VERSION ""

NS_ :

BS_:

BU_: Turbocharger OnBoardDataLogger OffBoardDiagnosticTool2 OffBoardDiagnosticTool1 FileServer ParkingBrakeController SeatControl2 FanDriveController SteeringColumnUnit CommunicationUnitRadio CommunicationUnitSatellite CommunicationUnitCellular PropulsionBatteryCharger ChassisController2 ChassisController1 EngineValveControl AuxiliaryHeater2 AuxiliaryHeater1 ClutchUnit RampControl InformationSystem1 SuspensionSystemController2 OilSensor VehicleDynamicStability ExhaustEmissionController TransmissionDisplay2 TransmissionDisplay1 ClimateControl2 WaterPumpController RearAxleSteeringController LightingOperatorControl SeatController1 IgnitionController2 IgnitionController1 TirePressureController CabController2 CabController1 PneumaticSystemController SuspensionSystemController1 HydraulicPumpController EnduranceBrakingSystem RetarderExhaustEngine2 OnBoardDiagnosticUnit HeadwayController RetarderExhaustEngine1 CabDisplay1 ManagementComputer VirtualTerminal OffVehicleGateway PowerTakeOffFront HitchControl AuxiliaryValveControl BodyController TractorTrailerBridge1 StarterSystem ElectricalSystem VehicleSecurity VehicleNavigation AerodynamicControl ElectricalChargingSystem ClimateControl1 TripRecorder InstrumentCluster SuspensionDriveAxle2 SuspensionDriveAxle1 SuspensionSteerAxle SteeringController FuelSystem CruiseControl RetarderDriveline RetarderEngine BrakesDriveAxle2 BrakesDriveAxle1 BrakesSystemController BrakesSteerAxle AxleDrive2 AxleDrive1 AxleSteering PowerTakeOff ShiftConsoleSecondary ShiftConsolePrimary Transmission2 Transmission1 Engine2 Engine1
VAL_TABLE_ FMI 31 "Not available" 19 "Received network data in error" 18 "Below normal (moderately severe)" 17 "Below normal (least severe)" 16 "Above normal (moderately severe)" 15 "Above normal (least severe)" 14 "Special intstructions" 13 "Out of calibration" 12 "Bad intelligent device" 11 "Root cause not known" 10 "Abnormal rate of change" 9 "Abnormal update rate" 8 "Abnormal frequency" 7 "Mechanical system not responding" 6 "Current above normal" 5 "Current below normal" 4 "Voltage below normal" 3 "Voltage above normal" 2 "Data erratic" 1 "Below normal (most severe)" 0 "Above normal (most severe)" ;

BO_ 3221225472 VECTOR__INDEPENDENT_SIG_MSG: 0 Vector__XXX
 SG_ New_Signal_6357 : 0|8@1+ (1,0) [0|0] "" Vector__XXX
 SG_ New_Signal_6356 : 0|8@1+ (1,0) [0|0] "" Vector__XXX
 SG_ TrailerWeight : 0|16@1+ (2,0) [0|128510] "kg" Vector__XXX
 SG_ ReferenceTirePressSetting : 0|8@1+ (1,0) [0|2000] "kPa" Vector__XXX
 SG_ ReferenceTirePress : 0|8@1+ (1,0) [0|2000] "kPa" Vector__XXX
 SG_ TirePressThresholdDetection : 0|3@1+ (1,0) [0|7] "" Vector__XXX
 SG_ TireAirLeakageRate : 0|16@1+ (0.1,0) [0|6425.5] "Pa/s" Vector__XXX
 SG_ CTIWheelEndElectricalFault : 0|2@1+ (1,0) [0|3] "" Vector__XXX
 SG_ CTITireStatus : 0|2@1+ (1,0) [0|3] "" Vector__XXX
 SG_ CTIWheelSensorStatus : 0|2@1+ (1,0) [0|3] "" Vector__XXX
 SG_ TireTemp : 0|16@1+ (0.03125,-273) [-273|1734.96875] "deg C" Vector__XXX
 SG_ TirePress : 0|8@1+ (4,0) [0|1000] "kPa" Vector__XXX
 SG_ EngTurningGearEngaged : 0|2@1+ (1,0) [0|3] "" Vector__XXX
 SG_ ChangeChildPositionParentObjectI : 0|16@1+ (1,0) [0|65535] "" Vector__XXX
 SG_ ChangeChildLocationParentObjectI : 0|16@1+ (1,0) [0|65535] "" Vector__XXX
 SG_ InputObjectId : 0|16@1+ (1,0) [0|255] "" Vector__XXX
 SG_ KeyActivationCode : 0|8@1+ (1,0) [0|2] "" Vector__XXX
 SG_ ButtonActivationCode : 0|8@1+ (1,0) [0|2] "" Vector__XXX
 SG_ XPosition : 0|16@1+ (1,0) [0|65535] "" Vector__XXX
 SG_ VTSelectInputObjectID : 0|16@1+ (1,0) [0|65535] "" Vector__XXX
 SG_ VTEscObjectID : 0|16@1+ (1,0) [0|65535] "" Vector__XXX
 SG_ VTChangeNumericValueObjectID : 0|16@1+ (1,0) [0|65535] "" Vector__XXX
 SG_ VTChangeActiveMaskObjectID : 0|16@1+ (1,0) [0|65535] "" Vector__XXX
 SG_ VTChangeSoftKeyMaskParentID : 0|16@1+ (1,0) [0|65535] "" Vector__XXX
 SG_ AuxiliaryFunctionObjectID : 0|16@1+ (1,0) [0|65535] "" Vector__XXX
 SG_ InputStatusObjectId : 0|16@1+ (1,0) [0|255] "" Vector__XXX
 SG_ SelectInputObjectID : 0|16@1+ (1,0) [0|65535] "" Vector__XXX
 SG_ ObjectToSizeID : 0|16@1+ (1,0) [0|65535] "" Vector__XXX
 SG_ ObjectToChangeColourID : 0|16@1+ (1,0) [0|65535] "" Vector__XXX
 SG_ ObjectToChangeNumValueID : 0|16@1+ (1,0) [0|65535] "" Vector__XXX
 SG_ ObjectToChangeEndPointID : 0|16@1+ (1,0) [0|65535] "" Vector__XXX
 SG_ ObjectToChangeFontID : 0|16@1+ (1,0) [0|65535] "" Vector__XXX
 SG_ ObjectToChangeFillAttributesID : 0|16@1+ (1,0) [0|65535] "" Vector__XXX
 SG_ ObjectToChangeAttributeID : 0|16@1+ (1,0) [0|65535] "" Vector__XXX
 SG_ AlarmMaskObjectID : 0|16@1+ (1,0) [0|65535] "" Vector__XXX
 SG_ ListInputObjectID : 0|16@1+ (1,0) [0|65535] "" Vector__XXX
 SG_ PolygonObjectToChangeID : 0|16@1+ (1,0) [0|65535] "" Vector__XXX
 SG_ PolygonObjectToScaleID : 0|16@1+ (1,0) [0|65535] "" Vector__XXX
 SG_ GraphicsContextObjectID : 0|16@1+ (1,0) [0|65535] "" Vector__XXX
 SG_ ObjectToGetAttributeID : 0|16@1+ (1,0) [0|65535] "" Vector__XXX
 SG_ ColourMapObjectID : 0|16@1+ (1,0) [0|65535] "" Vector__XXX
 SG_ LockUnlockCommand : 0|8@1+ (1,0) [0|1] "" Vector__XXX
 SG_ MacroObjecID : 0|8@1+ (1,0) [0|255] "" Vector__XXX
 SG_ CodePlane : 0|8@1+ (1,0) [0|16] "" Vector__XXX
 SG_ KeyObjectID : 0|16@1+ (1,0) [0|65535] "" Vector__XXX
 SG_ ButtonObjectID : 0|16@1+ (1,0) [0|65535] "" Vector__XXX
 SG_ DataOrAlarmMaskObjectID : 0|16@1+ (1,0) [0|65535] "" Vector__XXX
 SG_ MemoryRequired : 0|32@1+ (1,0) [0|4294967295] "" Vector__XXX
 SG_ FirstWideChar : 0|16@1+ (1,0) [0|65535] "" Vector__XXX
 SG_ IdentityNumber : 0|21@1+ (1,0) [0|2097152] "" Vector__XXX
 SG_ Status_1 : 0|8@1+ (1,0) [0|1] "" Vector__XXX
 SG_ YPosition : 0|16@1+ (1,0) [0|65535] "" Vector__XXX
 SG_ VTSelectInputObjectStatus : 0|8@1+ (1,0) [0|1] "" Vector__XXX
 SG_ VTChangeSoftKeyMaskObjectID : 0|16@1+ (1,0) [0|65535] "" Vector__XXX
 SG_ AuxInputEnable : 0|8@1+ (1,0) [0|1] "" Vector__XXX
 SG_ ChangeChildPositionObjectID : 0|16@1+ (1,0) [0|65535] "" Vector__XXX
 SG_ NewBackgroundColour : 0|8@1+ (1,0) [0|255] "" Vector__XXX
 SG_ AttributeID : 0|8@1+ (1,0) [0|16777200] "" Vector__XXX
 SG_ NewPriority : 0|8@1+ (1,0) [0|255] "" Vector__XXX
 SG_ ListIndex : 0|8@1+ (1,0) [0|255] "" Vector__XXX
 SG_ ChangeChildLocationObjectID : 0|16@1+ (1,0) [0|65535] "" Vector__XXX
 SG_ NewWidthAttribute : 0|16@1+ (1,0) [0|65535] "" Vector__XXX
 SG_ SubCommandID : 0|8@1+ (1,0) [0|0] "" Vector__XXX
 SG_ Value1 : 0|16@1+ (1,0) [0|65535] "" Vector__XXX
 SG_ KeyObjectParentID : 0|16@1+ (1,0) [0|65535] "" Vector__XXX
 SG_ ButtonObjectParentID : 0|16@1+ (1,0) [0|65535] "" Vector__XXX
 SG_ VTChangeNumericValueValue : 0|32@1+ (1,0) [0|4294967295] "" Vector__XXX
 SG_ NewObjectID : 0|16@1+ (1,0) [0|65535] "" Vector__XXX
 SG_ LastWideChar : 0|16@1+ (1,0) [0|65535] "" Vector__XXX
 SG_ ManufacturerCode : 0|11@1+ (1,0) [0|2047] "" Vector__XXX
 SG_ TouchState : 0|8@1+ (1,0) [0|255] "" Vector__XXX
 SG_ NewHeigthAttribute : 0|16@1+ (1,0) [0|0] "" Vector__XXX
 SG_ Value2 : 0|16@1+ (1,0) [0|65535] "" Vector__XXX
 SG_ Status_2 : 0|8@1+ (1,0) [0|1] "" Vector__XXX
 SG_ SoftKeyCode : 0|8@1+ (1,0) [0|255] "" Vector__XXX
 SG_ ButtonKeyCode : 0|8@1+ (1,0) [0|255] "" Vector__XXX
 SG_ ECUInstance : 0|3@1+ (1,0) [0|7] "" Vector__XXX
 SG_ FunctionInstance : 0|5@1+ (1,0) [0|31] "" Vector__XXX
 SG_ OperatingState1 : 0|1@1+ (1,0) [0|1] "" Vector__XXX
 SG_ Function : 0|8@1+ (1,0) [0|255] "" Vector__XXX
 SG_ OperatingState2 : 0|1@1+ (1,0) [0|1] "" Vector__XXX
 SG_ VehicleSystem2 : 0|7@1+ (1,0) [0|127] "" Vector__XXX
 SG_ VehicleSystemInstance : 0|4@1+ (1,0) [0|15] "" Vector__XXX
 SG_ IndustryGroup : 0|3@1+ (1,0) [0|7] "" Vector__XXX
 SG_ ArbitraryAddressCapable : 0|1@1+ (1,0) [0|1] "" Vector__XXX
 SG_ MalfunctionIndicatorLampStatus : 0|2@1+ (1,0) [0|3] "" Vector__XXX
 SG_ RedStopLampState : 0|2@1+ (1,0) [0|3] "" Vector__XXX
 SG_ AmberWarningLampStatus : 0|2@1+ (1,0) [0|3] "" Vector__XXX
 SG_ ProtectLampStatus : 0|2@1+ (1,0) [0|3] "" Vector__XXX
 SG_ FlashRedStopLamp : 0|2@1+ (1,0) [0|3] "" Vector__XXX
 SG_ FlashProtectLamp : 0|2@1+ (1,0) [0|3] "" Vector__XXX
 SG_ FlashMalfuncIndicatorLamp : 0|2@1+ (1,0) [0|3] "" Vector__XXX
 SG_ FlashAmberWarningLamp : 0|2@1+ (1,0) [0|3] "" Vector__XXX
 SG_ DTC5 : 0|32@1+ (1,0) [0|4294967295] "" Vector__XXX
 SG_ DTC4 : 0|32@1+ (1,0) [0|4294967295] "" Vector__XXX
 SG_ DTC3 : 0|32@1+ (1,0) [0|4294967295] "" Vector__XXX
 SG_ DTC2 : 0|32@1+ (1,0) [0|4294967295] "" Vector__XXX
 SG_ DTC1 : 0|32@1+ (1,0) [0|4294967295] "" Vector__XXX

BO_ 682 reverseCurrent2: 1 Vector__XXX
 SG_ error : 0|8@1+ (1,0) [0|0] "enum" Vector__XXX

BO_ 681 reverseCurrnet1: 4 Vector__XXX
 SG_ current : 0|32@1+ (1,0) [0|0] "uA" Vector__XXX

BO_ 2566835198 DM2: 22 Vector__XXX
 SG_ SPN_Conversion_Method5 : 175|1@1+ (1,0) [0|0] "" Vector__XXX
 SG_ Occurance_Count5 : 168|7@1+ (1,0) [0|0] "" Vector__XXX
 SG_ Failure_Mode_Indentifier5 : 160|5@1+ (1,0) [0|0] "" Vector__XXX
 SG_ SPN5 : 151|19@0+ (1,0) [0|0] "" Vector__XXX
 SG_ SPN_Conversion_Method4 : 143|1@1+ (1,0) [0|0] "" Vector__XXX
 SG_ Occurance_Count4 : 136|7@1+ (1,0) [0|0] "" Vector__XXX
 SG_ Failure_Mode_Indentifier4 : 128|5@1+ (1,0) [0|0] "" Vector__XXX
 SG_ SPN4 : 119|19@0+ (1,0) [0|0] "" Vector__XXX
 SG_ SPN_Conversion_Method3 : 111|1@1+ (1,0) [0|0] "" Vector__XXX
 SG_ Occurance_Count3 : 104|7@1+ (1,0) [0|0] "" Vector__XXX
 SG_ Failure_Mode_Indentifier3 : 96|5@1+ (1,0) [0|0] "" Vector__XXX
 SG_ SPN3 : 87|19@0+ (1,0) [0|0] "" Vector__XXX
 SG_ Occurance_Count2 : 72|7@1+ (1,0) [0|0] "" Vector__XXX
 SG_ SPN_Conversion_Method2 : 79|1@1+ (1,0) [0|0] "" Vector__XXX
 SG_ Failure_Mode_Indentifier2 : 64|5@1+ (1,0) [0|0] "" Vector__XXX
 SG_ SPN2 : 55|19@0+ (1,0) [0|0] "" Vector__XXX
 SG_ SPN : 23|19@0+ (1,0) [0|0] "" Vector__XXX
 SG_ SPN_Conversion_Method : 47|1@1+ (1,0) [0|0] "" Vector__XXX
 SG_ Occurance_Count : 40|7@1+ (1,0) [0|0] "" Vector__XXX
 SG_ Failure_Mode_Indentifier : 32|5@1+ (1,0) [0|0] "" Vector__XXX
 SG_ FlashRedStopLamp : 12|2@1+ (1,0) [0|3] "" Vector__XXX
 SG_ FlashProtectLamp : 8|2@1+ (1,0) [0|3] "" Vector__XXX
 SG_ FlashMalfuncIndicatorLamp : 14|2@1+ (1,0) [0|3] "" Vector__XXX
 SG_ FlashAmberWarningLamp : 10|2@1+ (1,0) [0|3] "" Vector__XXX
 SG_ MalfunctionIndicatorLampStatus : 6|2@1+ (1,0) [0|3] "" Vector__XXX
 SG_ AmberWarningLampStatus : 2|2@1+ (1,0) [0|3] "" Vector__XXX
 SG_ RedStopLampState : 4|2@1+ (1,0) [0|3] "" Vector__XXX
 SG_ ProtectLampStatus : 0|2@1+ (1,0) [0|3] "" Vector__XXX

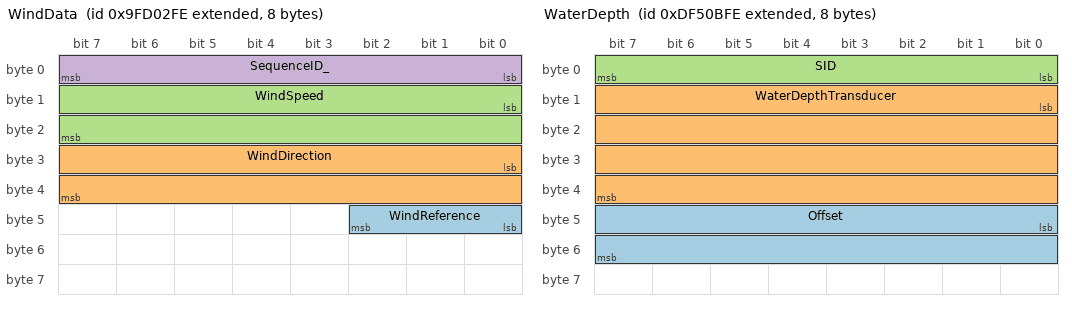
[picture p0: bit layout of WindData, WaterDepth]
BO_ 2315059966 WindData: 8 Vector__XXX
 SG_ WindReference : 40|3@1+ (1,0) [0|7] "" Vector__XXX
 SG_ WindDirection : 24|16@1+ (0.0001,0) [0|6.28318] "rad" Vector__XXX
 SG_ WindSpeed : 8|16@1+ (0.01,0) [0|655.32] "m/s" Vector__XXX
 SG_ SequenceID_ : 0|8@1+ (1,0) [0|252] "" Vector__XXX

BO_ 2381646846 WaterDepth: 8 Vector__XXX
 SG_ Offset : 40|16@1- (0.001,0) [-32.764|32.764] "m" Vector__XXX
 SG_ WaterDepthTransducer : 8|32@1+ (0.01,0) [0|42950000] "m" Vector__XXX
 SG_ SID : 0|8@1+ (1,0) [0|252] "" Vector__XXX

BO_ 2315129598 VesselSpeedComponents: 12 Vector__XXX
 SG_ SternSpeedGroundreferenced : 80|16@1- (0.001,0) [-32.764|32.764] "m/s" Vector__XXX
 SG_ SternSpeedWaterreferenced : 64|16@1- (0.001,0) [-32.764|32.764] "m/s" Vector__XXX
 SG_ TransverseSpeedGroundreferenced : 48|16@1- (0.001,0) [-32.764|32.764] "m/s" Vector__XXX
 SG_ LngtudinalSpeedGroundreferenced : 32|16@1- (0.001,0) [-32.764|32.764] "m/s" Vector__XXX
 SG_ TransverseSpeedWaterreferenced : 16|16@1- (0.001,0) [-32.764|32.764] "m/s" Vector__XXX
 SG_ LngitudinalSpeedWaterreferenced : 0|16@1- (0.001,0) [-32.764|32.764] "m/s" Vector__XXX

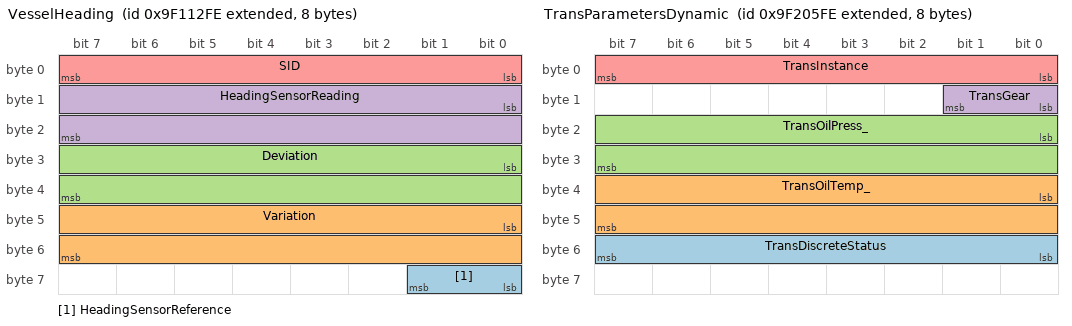
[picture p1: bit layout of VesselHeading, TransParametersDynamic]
BO_ 2314277630 VesselHeading: 8 Vector__XXX
 SG_ HeadingSensorReference : 56|2@1+ (1,0) [0|3] "" Vector__XXX
 SG_ Variation : 40|16@1- (0.0001,0) [-3.14159|3.14159] "rad" Vector__XXX
 SG_ Deviation : 24|16@1- (0.0001,0) [-3.14159|3.14159] "rad" Vector__XXX
 SG_ HeadingSensorReading : 8|16@1+ (0.0001,0) [0|6.28318] "rad" Vector__XXX
 SG_ SID : 0|8@1+ (1,0) [0|252] "" Vector__XXX

BO_ 2583172606 UserDatumSettings: 37 Vector__XXX
 SG_ DatumName : 288|8@1+ (1,0) [0|255] "ASCII" Vector__XXX
 SG_ EllipsoidFlatteningInverse : 256|32@1- (1,0) [-3.4E+038|3.4E+038] "" Vector__XXX
 SG_ EllipsoidSemimajorAxis : 224|32@1- (0.01,0) [-21470000|21470000] "m" Vector__XXX
 SG_ Scale : 192|32@1- (1,0) [-3.4E+038|3.4E+038] "" Vector__XXX
 SG_ RotationInZ : 160|32@1- (1,0) [-3.4E+038|3.4E+038] "" Vector__XXX
 SG_ RotationInY : 128|32@1- (1,0) [-3.4E+038|3.4E+038] "" Vector__XXX
 SG_ RotationInX : 96|32@1- (1,0) [-3.4E+038|3.4E+038] "" Vector__XXX
 SG_ DeltaZ : 64|32@1- (0.01,0) [-21470000|21470000] "m" Vector__XXX
 SG_ DeltaY : 32|32@1- (0.01,0) [-21470000|21470000] "m" Vector__XXX
 SG_ DeltaX : 0|32@1- (0.01,0) [-21470000|21470000] "m" Vector__XXX

BO_ 2515667198 TripParametersVessel: 14 Vector__XXX
 SG_ TripRunTime : 80|32@1+ (0.001,0) [0|4295000] "sec" Vector__XXX
 SG_ EstFuelRemaining : 64|16@1+ (0.001,0) [0|65.532] "cu m" Vector__XXX
 SG_ DistanceToEmpty : 32|32@1+ (0.01,0) [0|42950000] "m" Vector__XXX
 SG_ TimeToEmpty : 0|32@1+ (0.001,0) [0|4295000] "sec" Vector__XXX

BO_ 2515667454 TripParametersEng: 9 Vector__XXX
 SG_ InstantaneousFuelEconomy : 56|16@1- (0.0001,0) [-3.2764|3.2764] "(cu m)/hr" Vector__XXX
 SG_ FuelRateEconomy : 40|16@1- (0.0001,0) [-3.2764|3.2764] "(cu m)/hr" Vector__XXX
 SG_ FuelRateAverage : 24|16@1- (0.0001,0) [-3.2764|3.2764] "(cu m)/hr" Vector__XXX
 SG_ TripFuelUsed : 8|16@1+ (0.001,0) [0|65.532] "cu m" Vector__XXX
 SG_ EngInstance : 0|8@1+ (1,0) [0|255] "" Vector__XXX

BO_ 2314339838 TransParametersDynamic: 8 Vector__XXX
 SG_ TransDiscreteStatus : 48|8@1+ (1,0) [0|255] "" Vector__XXX
 SG_ TransOilTemp_ : 32|16@1+ (0.1,0) [0|6553.2] "°K" Vector__XXX
 SG_ TransOilPress_ : 16|16@1+ (100,0) [0|6553200] "Pa" Vector__XXX
 SG_ TransGear : 8|2@1+ (1,0) [0|3] "" Vector__XXX
 SG_ TransInstance : 0|8@1+ (1,0) [0|255] "" Vector__XXX

BO_ 2314602750 TrackedTargetData: 27 Vector__XXX
 SG_ CPA : 112|32@1- (0.01,0) [-21470000|21470000] "m" Vector__XXX
 SG_ Speed : 96|16@1+ (0.01,0) [0|655.32] "m/s" Vector__XXX
 SG_ Course : 80|16@1+ (0.0001,0) [0|6.28318] "rad" Vector__XXX
 SG_ Distance : 48|32@1- (0.01,0) [-21470000|21470000] "m" Vector__XXX
 SG_ Bearing : 32|16@1+ (0.0001,0) [0|6.28318] "rad" Vector__XXX
 SG_ BearingReference : 28|2@1+ (1,0) [0|3] "" Vector__XXX
 SG_ TrackStatus : 24|4@1+ (1,0) [0|15] "" Vector__XXX
 SG_ TargetID : 8|16@1+ (1,0) [0|65532] "" Vector__XXX
 SG_ SequenceID_ : 0|8@1+ (1,0) [0|252] "" Vector__XXX
 SG_ Name : 208|8@1+ (1,0) [0|255] "ASCII" Vector__XXX
 SG_ UTCOfFix : 176|32@1+ (0.0001,0) [0|86401] "sec" Vector__XXX
 SG_ TCPA : 144|32@1- (0.001,0) [-2148000|2148000] "sec" Vector__XXX

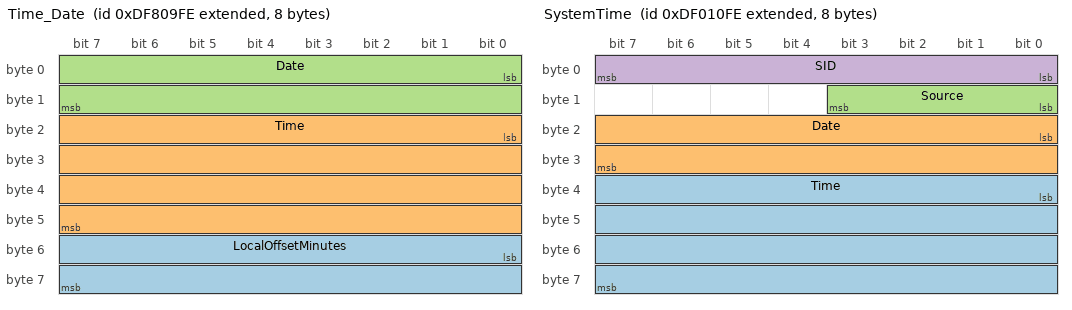
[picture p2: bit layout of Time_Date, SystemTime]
BO_ 2381842942 Time_Date: 8 Vector__XXX
 SG_ LocalOffsetMinutes : 48|16@1- (1,0) [-32764|32764] "mins" Vector__XXX
 SG_ Time : 16|32@1+ (0.0001,0) [0|86401] "sec" Vector__XXX
 SG_ Date : 0|16@1+ (1,0) [0|65532] "day" Vector__XXX

BO_ 2381911550 TimeTo_FromMark: 10 Vector__XXX
 SG_ MarkID : 48|32@1+ (1,0) [0|4294967292] "" Vector__XXX
 SG_ MarkType : 40|4@1+ (1,0) [0|15] "" Vector__XXX
 SG_ TimeElapsedTogoToMark : 8|32@1- (0.001,0) [-2148000|2148000] "sec" Vector__XXX
 SG_ SID : 0|8@1+ (1,0) [0|252] "" Vector__XXX

BO_ 2583499006 TideStationData: 20 Vector__XXX
 SG_ StationIDString : 152|8@1+ (1,0) [0|255] "ASCII" Vector__XXX
 SG_ TideLevelStandardDeviation : 136|16@1+ (0.01,0) [0|655.32] "m" Vector__XXX
 SG_ TideLevel : 120|16@1- (0.001,0) [-32.764|32.764] "m" Vector__XXX
 SG_ StationLocationLongitude : 88|32@1- (1E-007,0) [-180|180] "deg" Vector__XXX
 SG_ StationLocationLatitude : 56|32@1- (1E-007,0) [-90|90] "deg" Vector__XXX
 SG_ MeasurementTime : 24|32@1+ (0.0001,0) [0|86401] "sec" Vector__XXX
 SG_ MeasurementDate : 8|16@1+ (1,0) [0|65532] "day" Vector__XXX
 SG_ TideTendency : 4|2@1+ (1,0) [0|3] "" Vector__XXX
 SG_ Mode : 0|4@1+ (1,0) [0|15] "" Vector__XXX

BO_ 2381320446 SystemTime: 8 Vector__XXX
 SG_ Time : 32|32@1+ (0.0001,0) [0|86401] "sec" Vector__XXX
 SG_ Date : 16|16@1+ (1,0) [0|65532] "day" Vector__XXX
 SG_ Source : 8|4@1+ (1,0) [0|15] "" Vector__XXX
 SG_ SID : 0|8@1+ (1,0) [0|252] "" Vector__XXX

BO_ 2381451006 SwitchBankCtrl: 8 Vector__XXX
 SG_ Switch28 : 62|2@1+ (1,0) [0|3] "" Vector__XXX
 SG_ Switch27 : 60|2@1+ (1,0) [0|3] "" Vector__XXX
 SG_ Switch26 : 58|2@1+ (1,0) [0|3] "" Vector__XXX
 SG_ Switch25 : 56|2@1+ (1,0) [0|3] "" Vector__XXX
 SG_ Switch24 : 54|2@1+ (1,0) [0|3] "" Vector__XXX
 SG_ Switch23 : 52|2@1+ (1,0) [0|3] "" Vector__XXX
 SG_ Switch22 : 50|2@1+ (1,0) [0|3] "" Vector__XXX
 SG_ Switch21 : 48|2@1+ (1,0) [0|3] "" Vector__XXX
 SG_ Switch20 : 46|2@1+ (1,0) [0|3] "" Vector__XXX
 SG_ Switch19 : 44|2@1+ (1,0) [0|3] "" Vector__XXX
 SG_ Switch18 : 42|2@1+ (1,0) [0|3] "" Vector__XXX
 SG_ Switch17 : 40|2@1+ (1,0) [0|3] "" Vector__XXX
 SG_ Switch16 : 38|2@1+ (1,0) [0|3] "" Vector__XXX
 SG_ Switch15 : 36|2@1+ (1,0) [0|3] "" Vector__XXX
 SG_ Switch14 : 34|2@1+ (1,0) [0|3] "" Vector__XXX
 SG_ Switch13 : 32|2@1+ (1,0) [0|3] "" Vector__XXX
 SG_ Switch12 : 30|2@1+ (1,0) [0|3] "" Vector__XXX
 SG_ Switch11 : 28|2@1+ (1,0) [0|3] "" Vector__XXX
 SG_ Switch10 : 26|2@1+ (1,0) [0|3] "" Vector__XXX
 SG_ Switch9 : 24|2@1+ (1,0) [0|3] "" Vector__XXX
 SG_ Switch8 : 22|2@1+ (1,0) [0|3] "" Vector__XXX
 SG_ Switch7 : 20|2@1+ (1,0) [0|3] "" Vector__XXX
 SG_ Switch6 : 18|2@1+ (1,0) [0|3] "" Vector__XXX
 SG_ Switch5 : 16|2@1+ (1,0) [0|3] "" Vector__XXX
 SG_ Switch4 : 14|2@1+ (1,0) [0|3] "" Vector__XXX
 SG_ Switch3 : 12|2@1+ (1,0) [0|3] "" Vector__XXX
 SG_ Switch2 : 10|2@1+ (1,0) [0|3] "" Vector__XXX
 SG_ Switch1 : 8|2@1+ (1,0) [0|3] "" Vector__XXX
 SG_ SwitchBankInstance : 0|8@1+ (1,0) [0|252] "" Vector__XXX

BO_ 2314535934 Speed: 9 Vector__XXX
 SG_ SpeedGroundReferenced : 24|22@1+ (0.01,0) [0|655.32] "m/s" Vector__XXX
 SG_ SpeedWaterReferenced : 8|16@1+ (0.01,0) [0|655.32] "m/s" Vector__XXX
 SG_ SequenceID_ : 0|8@1+ (1,0) [0|252] "" Vector__XXX

BO_ 2315129086 SmallCraftStatus: 8 Vector__XXX
 SG_ StarboardTrimTab : 8|8@1- (1,0) [-124|124] "" Vector__XXX
 SG_ PortTrimTab : 0|8@1- (1,0) [-124|124] "" Vector__XXX

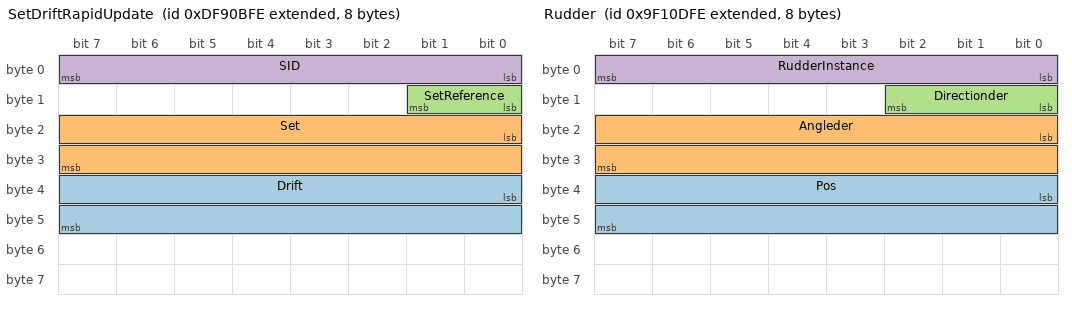
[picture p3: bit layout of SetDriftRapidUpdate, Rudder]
BO_ 2381908990 SetDriftRapidUpdate: 8 Vector__XXX
 SG_ Drift : 32|16@1+ (0.01,0) [0|655.32] "m/s" Vector__XXX
 SG_ Set : 16|16@1+ (0.0001,0) [0|6.28318] "rad" Vector__XXX
 SG_ SetReference : 8|2@1+ (1,0) [0|3] "" Vector__XXX
 SG_ SID : 0|8@1+ (1,0) [0|252] "" Vector__XXX

BO_ 2583499262 SalinityStationData: 22 Vector__XXX
 SG_ StationIDString : 168|8@1+ (1,0) [0|255] "ASCII" Vector__XXX
 SG_ WaterTemp : 152|16@1+ (0.01,0) [0|655.32] "°K" Vector__XXX
 SG_ Salinity : 120|32@1- (1,0) [-3.4E+038|3.4E+038] "" Vector__XXX
 SG_ StationLocationLongitude : 88|32@1- (1E-007,0) [-180|180] "deg" Vector__XXX
 SG_ StationLocationLatitude : 56|32@1- (1E-007,0) [-90|90] "deg" Vector__XXX
 SG_ MeasurementTime : 24|32@1+ (0.0001,0) [0|86401] "sec" Vector__XXX
 SG_ MeasurementDate : 8|16@1+ (1,0) [0|65532] "day" Vector__XXX
 SG_ Mode : 0|4@1+ (1,0) [0|15] "" Vector__XXX

BO_ 2650544894 RuteAndWPServiceWPListWPNamePos: 13 Vector__XXX
 SG_ WPName : 96|8@1+ (1,0) [0|255] "ASCII" Vector__XXX
 SG_ WPID : 80|16@1+ (1,0) [0|65532] "" Vector__XXX
 SG_ reserved : 64|16@1+ (1,0) [0|65532] "" Vector__XXX
 SG_ DatabaseID : 48|16@1+ (1,0) [0|65532] "" Vector__XXX
 SG_ NumberOfValidWPsInWPList : 32|16@1+ (1,0) [0|65532] "" Vector__XXX
 SG_ nItems : 16|16@1+ (1,0) [0|65532] "" Vector__XXX
 SG_ StartWPID : 0|16@1+ (1,0) [0|65532] "" Vector__XXX

BO_ 2650544382 RuteAndWPServiceDatabaseComment: 9 Vector__XXX
 SG_ CommentText : 64|8@1+ (1,0) [0|255] "ASCII" Vector__XXX
 SG_ DatabaseID : 48|16@1+ (1,0) [0|65532] "" Vector__XXX
 SG_ NumberOfDatabasesWithComments : 32|16@1+ (1,0) [0|65532] "" Vector__XXX
 SG_ nItems : 16|16@1+ (1,0) [0|65532] "" Vector__XXX
 SG_ StartDatabaseID : 0|16@1+ (1,0) [0|65532] "" Vector__XXX

BO_ 2314276350 Rudder: 8 Vector__XXX
 SG_ Pos : 32|16@1- (0.0001,0) [-3.14159|3.14159] "rad" Vector__XXX
 SG_ Angleder : 16|16@1- (0.0001,0) [-3.14159|3.14159] "rad" Vector__XXX
 SG_ Directionder : 8|3@1+ (1,0) [0|7] "" Vector__XXX
 SG_ RudderInstance : 0|8@1+ (1,0) [0|255] "" Vector__XXX

BO_ 2650543614 RtAndWPSrvcXTELmtNvgationMethod: 15 Vector__XXX
 SG_ NavMethodInLegAfterWP : 112|2@1+ (1,0) [0|3] "" Vector__XXX
 SG_ XTELimitInLegAfterWP : 96|16@1- (1,0) [-32764|32764] "m" Vector__XXX
 SG_ RPS : 80|16@1+ (1,0) [0|65532] "" Vector__XXX
 SG_ RouteID : 64|16@1+ (1,0) [0|65532] "" Vector__XXX
 SG_ DatabaseID : 48|16@1+ (1,0) [0|65532] "" Vector__XXX
 SG_ NmbrOfWypntsWthASpcfcXTELmtNvMth : 32|16@1+ (1,0) [0|65532] "" Vector__XXX
 SG_ nItems : 16|16@1+ (1,0) [0|65532] "" Vector__XXX
 SG_ StartRPS : 0|16@1+ (1,0) [0|65532] "" Vector__XXX

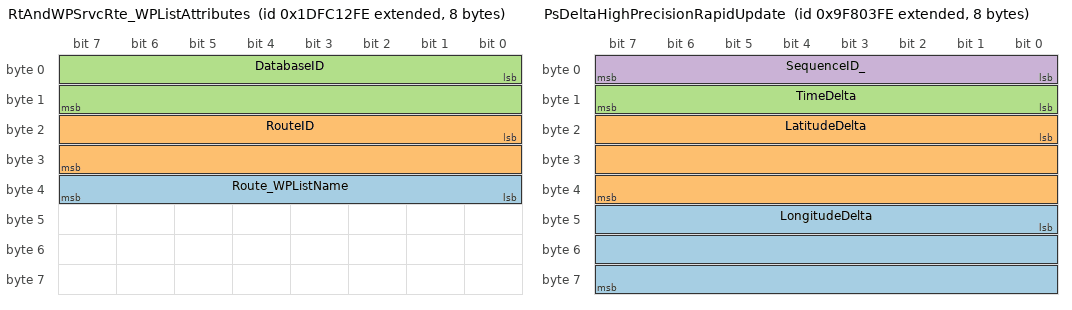
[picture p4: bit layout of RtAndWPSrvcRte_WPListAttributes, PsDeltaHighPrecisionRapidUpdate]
BO_ 2650542846 RtAndWPSrvcRte_WPListAttributes: 8 Vector__XXX
 SG_ Route_WPListName : 32|8@1+ (1,0) [0|255] "ASCII" Vector__XXX
 SG_ RouteID : 16|16@1+ (1,0) [0|65532] "" Vector__XXX
 SG_ DatabaseID : 0|16@1+ (1,0) [0|65532] "" Vector__XXX

BO_ 2650543870 RouteAndWPServiceWPComment: 13 Vector__XXX
 SG_ Comment : 96|8@1+ (1,0) [0|255] "ASCII" Vector__XXX
 SG_ WPID_RPS : 80|16@1+ (1,0) [0|65532] "" Vector__XXX
 SG_ RouteID : 64|16@1+ (1,0) [0|65532] "" Vector__XXX
 SG_ DatabaseID : 48|16@1+ (1,0) [0|65532] "" Vector__XXX
 SG_ NumberOfWPsWithComments : 32|16@1+ (1,0) [0|65532] "" Vector__XXX
 SG_ nItems : 16|16@1+ (1,0) [0|65532] "" Vector__XXX
 SG_ StartID : 0|16@1+ (1,0) [0|65532] "" Vector__XXX

BO_ 2650543102 RouteAndWPServiceRouteWPNamePos: 13 Vector__XXX
 SG_ WPName : 96|8@1+ (1,0) [0|255] "ASCII" Vector__XXX
 SG_ WPID : 80|16@1+ (1,0) [0|65532] "" Vector__XXX
 SG_ RouteID : 64|16@1+ (1,0) [0|65532] "" Vector__XXX
 SG_ DatabaseID : 48|16@1+ (1,0) [0|65532] "" Vector__XXX
 SG_ NumberOfWPsInRoute : 32|16@1+ (1,0) [0|65532] "" Vector__XXX
 SG_ nItems : 16|16@1+ (1,0) [0|65532] "" Vector__XXX
 SG_ StartRPS : 0|16@1+ (1,0) [0|65532] "" Vector__XXX

BO_ 2650543358 RouteAndWPServiceRouteWPName: 13 Vector__XXX
 SG_ WPName : 96|8@1+ (1,0) [0|255] "ASCII" Vector__XXX
 SG_ WPID : 80|16@1+ (1,0) [0|65532] "" Vector__XXX
 SG_ RouteID : 64|16@1+ (1,0) [0|65532] "" Vector__XXX
 SG_ DatabaseID : 48|16@1+ (1,0) [0|65532] "" Vector__XXX
 SG_ NumberOfWPsInRoute : 32|16@1+ (1,0) [0|65532] "" Vector__XXX
 SG_ nItems : 16|16@1+ (1,0) [0|65532] "" Vector__XXX
 SG_ StartRPS : 0|16@1+ (1,0) [0|65532] "" Vector__XXX

BO_ 2650542590 RouteAndWPServiceRouteList: 11 Vector__XXX
 SG_ RouteName : 80|8@1+ (1,0) [0|255] "ASCII" Vector__XXX
 SG_ RouteID : 64|16@1+ (1,0) [0|65532] "" Vector__XXX
 SG_ DatabaseID : 48|16@1+ (1,0) [0|65532] "" Vector__XXX
 SG_ NmbrOfRoutesAvailableInDatabase : 32|16@1+ (1,0) [0|65532] "" Vector__XXX
 SG_ nItems : 16|16@1+ (1,0) [0|65532] "" Vector__XXX
 SG_ StartRouteID : 0|16@1+ (1,0) [0|65532] "" Vector__XXX

BO_ 2650544126 RouteAndWPServiceRouteComment: 11 Vector__XXX
 SG_ Comment : 80|8@1+ (1,0) [0|255] "ASCII" Vector__XXX
 SG_ RouteID : 64|16@1+ (1,0) [0|65532] "" Vector__XXX
 SG_ DatabaseID : 48|16@1+ (1,0) [0|65532] "" Vector__XXX
 SG_ NumberOfRoutesWithComments : 32|16@1+ (1,0) [0|65532] "" Vector__XXX
 SG_ nItems : 16|16@1+ (1,0) [0|65532] "" Vector__XXX
 SG_ StartRouteID : 0|16@1+ (1,0) [0|65532] "" Vector__XXX

BO_ 2650544638 RouteAndWPServiceRadiusOfTurn: 14 Vector__XXX
 SG_ RadiusOfTurn : 96|16@1- (1,0) [-32764|32764] "m" Vector__XXX
 SG_ RPS : 80|16@1+ (1,0) [0|65532] "" Vector__XXX
 SG_ RouteID : 64|16@1+ (1,0) [0|65532] "" Vector__XXX
 SG_ DatabaseID : 48|16@1+ (1,0) [0|65532] "" Vector__XXX
 SG_ NmbrOfWypntsWthASpcfcRdusOfTurn : 32|16@1+ (1,0) [0|65532] "" Vector__XXX
 SG_ nItems : 16|16@1+ (1,0) [0|65532] "" Vector__XXX
 SG_ StartRPS : 0|16@1+ (1,0) [0|65532] "" Vector__XXX

BO_ 2650542334 RouteAndWPServiceDatabaseList: 9 Vector__XXX
 SG_ DatabaseName : 64|8@1+ (1,0) [0|255] "ASCII" Vector__XXX
 SG_ DatabaseID : 48|16@1+ (1,0) [0|65532] "" Vector__XXX
 SG_ NumberOfDatabasesAvailable : 32|16@1+ (1,0) [0|65532] "" Vector__XXX
 SG_ nItems : 16|16@1+ (1,0) [0|65532] "" Vector__XXX
 SG_ StartDatabaseID : 0|16@1+ (1,0) [0|65532] "" Vector__XXX

BO_ 2314277886 RateOfTurn: 8 Vector__XXX
 SG_ RateOfTurn : 8|16@1- (1,0) [-32768|32767] "rad/s" Vector__XXX
 SG_ SequenceID_ : 0|8@1+ (1,0) [0|252] "" Vector__XXX

BO_ 2382039038 RadioFrequency_Mode_Power: 9 Vector__XXX
 SG_ RadioChannel : 64|8@1+ (1,0) [0|255] "ASCII" Vector__XXX
 SG_ TxFrequency : 32|32@1+ (10,0) [0|327040] "Hz" Vector__XXX
 SG_ RxFrequency : 0|32@1+ (10,0) [0|327040] "Hz" Vector__XXX

BO_ 2314732542 PsDeltaHighPrecisionRapidUpdate: 8 Vector__XXX
 SG_ LongitudeDelta : 40|24@1- (1E-005,0) [-83|83] "s('')" Vector__XXX
 SG_ LatitudeDelta : 16|24@1- (1E-005,0) [-83|83] "s('')" Vector__XXX
 SG_ TimeDelta : 8|8@1+ (0.005,0) [0|1.26] "sec" Vector__XXX
 SG_ SequenceID_ : 0|8@1+ (1,0) [0|252] "" Vector__XXX

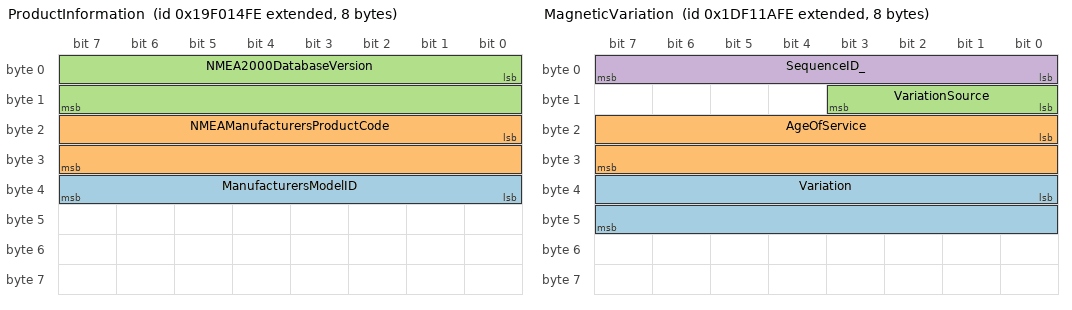
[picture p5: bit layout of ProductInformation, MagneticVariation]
BO_ 2582648062 ProductInformation: 8 Vector__XXX
 SG_ ManufacturersModelID : 32|8@1+ (1,0) [0|255] "ASCII" Vector__XXX
 SG_ NMEAManufacturersProductCode : 16|16@1+ (1,0) [0|65532] "" Vector__XXX
 SG_ NMEA2000DatabaseVersion : 0|16@1+ (1,0) [0|65532] "" Vector__XXX

BO_ 2314732030 PosRapidUpdate: 8 Vector__XXX
 SG_ Longitude_ : 32|32@1- (1E-007,0) [-180|180] "deg" Vector__XXX
 SG_ Latitude_ : 0|32@1- (1E-007,0) [-90|90] "deg" Vector__XXX

BO_ 2582576894 PGNLstTransmitPGNsGroupFunction: 8 Vector__XXX
 SG_ VrblNmbrOfFldsFldNmber2Repeated2 m1 : 32|24@1+ (1,0) [0|16777215] "" Vector__XXX
 SG_ FirstPGNSupported2 m1 : 8|24@1+ (1,0) [0|16777215] "" Vector__XXX
 SG_ VrblNmbrOfFldsFldNmber2Repeated m0 : 32|24@1+ (1,0) [0|16777215] "" Vector__XXX
 SG_ FirstPGNSupported m0 : 8|24@1+ (1,0) [0|16777215] "" Vector__XXX
 SG_ GrpFnctnTrnsmtAndReceivePGNList M : 0|8@1+ (1,0) [0|252] "" Vector__XXX

BO_ 2583234046 NavigationRoute_WPInformation: 11 Vector__XXX
 SG_ RouteName : 73|8@1+ (1,0) [0|255] "ASCII" Vector__XXX
 SG_ SpplmntaryRoute_WPDataAvailable : 68|2@1+ (1,0) [0|3] "" Vector__XXX
 SG_ NavigationDirectionInRoute : 64|4@1+ (1,0) [0|15] "" Vector__XXX
 SG_ RouteID : 48|16@1+ (1,0) [0|65532] "" Vector__XXX
 SG_ DatabaseID : 32|16@1+ (1,0) [0|65532] "" Vector__XXX
 SG_ nItems : 16|16@1+ (1,0) [0|65532] "" Vector__XXX
 SG_ StartRPS : 0|16@1+ (1,0) [0|65532] "" Vector__XXX

BO_ 2381907198 NavigationData: 34 Vector__XXX
 SG_ WaypointClosingVelocity : 256|16@1- (0.01,0) [-327.66|327.66] "m/s" Vector__XXX
 SG_ DestinationWptLongitude : 224|32@1- (1E-007,0) [-180|180] "deg" Vector__XXX
 SG_ DestinationWptLatitude : 192|32@1- (1E-007,0) [-90|90] "deg" Vector__XXX
 SG_ DestinationWaypointNumber : 160|32@1+ (1,0) [0|4294967292] "" Vector__XXX
 SG_ OriginWaypointNumber : 128|32@1+ (1,0) [0|4294967292] "" Vector__XXX
 SG_ BearingPosToDestinationWaypoint : 112|16@1+ (0.0001,0) [0|6.28318] "rad" Vector__XXX
 SG_ BaringiginToDestinationWaypoint : 96|16@1+ (0.0001,0) [0|6.28318] "rad" Vector__XXX
 SG_ ETADate : 80|16@1+ (1,0) [0|65532] "day" Vector__XXX
 SG_ ETATime : 48|32@1+ (0.0001,0) [0|86401] "sec" Vector__XXX
 SG_ CalculationType : 46|2@1+ (1,0) [0|3] "" Vector__XXX
 SG_ ArrivalCircleEntered : 44|2@1+ (1,0) [0|3] "" Vector__XXX
 SG_ PerpendicularCrossed : 42|2@1+ (1,0) [0|3] "" Vector__XXX
 SG_ Course_BearingRef : 40|2@1+ (1,0) [0|3] "" Vector__XXX
 SG_ DistanceToDestinationWaypoint : 8|32@1+ (0.01,0) [0|42950000] "m" Vector__XXX
 SG_ SID : 0|8@1+ (1,0) [0|252] "" Vector__XXX

BO_ 2381184766 NMEARqGroupFunction: 15 Vector__XXX
 SG_ NumberOfRqedCmdedParameters m2 : 48|8@1+ (1,0) [0|252] "" Vector__XXX
 SG_ VrblNmbrOfFldsFldNmber6Repeated3 m2 : 44|4@1+ (1,0) [0|15] "" Vector__XXX
 SG_ FirstParameterErrorCode m2 : 40|4@1+ (1,0) [0|15] "" Vector__XXX
 SG_ TransInterval_PriorityErrorCode m2 : 36|4@1+ (1,0) [0|15] "" Vector__XXX
 SG_ RqedCmdedPGNBeingAcknowledged m2 : 12|24@1+ (1,0) [0|16777215] "" Vector__XXX
 SG_ PGNErrorCode m2 : 8|4@1+ (1,0) [0|15] "" Vector__XXX
 SG_ VrblNmbrOfFldsFldNmber6Repeated2 m1 : 56|8@1+ (1,0) [0|252] "" Vector__XXX
 SG_ FeldNumberOfFirstCmdedParameter m1 : 48|8@1+ (1,0) [0|252] "" Vector__XXX
 SG_ NmbrOfPrsOfCmddPrmetersToFollow m1 : 40|8@1+ (1,0) [0|252] "" Vector__XXX
 SG_ PrioritySetting m1 : 32|4@1+ (1,0) [0|15] "" Vector__XXX
 SG_ CmdedPGN m1 : 8|24@1+ (1,0) [0|16777215] "" Vector__XXX
 SG_ VrblNmbrOfFldsFldNmber6Repeated m0 : 96|8@1+ (1,0) [0|252] "" Vector__XXX
 SG_ FieldNumberOfFirstRqedParameter m0 : 88|8@1+ (1,0) [0|252] "" Vector__XXX
 SG_ NmbrOfPrsOfRqParametersToFollow m0 : 80|8@1+ (1,0) [0|252] "" Vector__XXX
 SG_ TransIntervalOffset m0 : 64|16@1+ (0.01,0) [0|655.32] "sec" Vector__XXX
 SG_ TransInterval m0 : 32|32@1+ (0.001,0) [0|4295000] "sec" Vector__XXX
 SG_ RqedPGN m0 : 8|24@1+ (1,0) [0|16777215] "" Vector__XXX
 SG_ GroupFunctionRq_Cmd_Acknowledge M : 0|8@1+ (1,0) [0|252] "" Vector__XXX

BO_ 2583500030 MooredBuoyStationData: 35 Vector__XXX
 SG_ StationIDString : 272|8@1+ (1,0) [0|255] "ASCII" Vector__XXX
 SG_ WaterTemp : 256|16@1+ (0.01,0) [0|655.32] "°K" Vector__XXX
 SG_ AirTemp : 240|16@1+ (0.01,0) [0|655.32] "°K" Vector__XXX
 SG_ PressTendencyRate : 224|16@1- (10,0) [-327640|327640] "Pa/hr" Vector__XXX
 SG_ AtmosphericPress : 208|16@1+ (100,0) [0|6553200] "Pa" Vector__XXX
 SG_ DominateWavePeriod : 192|16@1+ (0.01,0) [0|655.32] "sec" Vector__XXX
 SG_ WaveHeight : 176|16@1+ (0.01,0) [0|655.32] "m" Vector__XXX
 SG_ WindGusts : 160|16@1+ (0.01,0) [0|655.32] "m/s" Vector__XXX
 SG_ WindReference : 152|3@1+ (1,0) [0|7] "" Vector__XXX
 SG_ WindDirection : 136|16@1+ (0.0001,0) [0|6.28318] "rad" Vector__XXX
 SG_ WindSpeed : 120|16@1+ (0.01,0) [0|655.32] "m/s" Vector__XXX
 SG_ StationLocationLongitude : 88|32@1- (1E-007,0) [-180|180] "deg" Vector__XXX
 SG_ StationLocationLatitude : 56|32@1- (1E-007,0) [-90|90] "deg" Vector__XXX
 SG_ MeasurementTime : 24|32@1+ (0.0001,0) [0|86401] "sec" Vector__XXX
 SG_ MeasurementDate : 8|16@1+ (1,0) [0|65532] "day" Vector__XXX
 SG_ Mode : 0|4@1+ (1,0) [0|15] "" Vector__XXX

BO_ 2583499774 MeteorologicalStationData: 27 Vector__XXX
 SG_ StationIDString : 203|8@1+ (1,0) [0|255] "ASCII" Vector__XXX
 SG_ AirTemp : 187|16@1+ (0.01,0) [0|655.32] "°K" Vector__XXX
 SG_ AtmosphericPress : 171|16@1+ (100,0) [0|6553200] "Pa" Vector__XXX
 SG_ WindGusts : 155|16@1+ (0.01,0) [0|655.32] "m/s" Vector__XXX
 SG_ WindReference : 152|3@1+ (1,0) [0|7] "" Vector__XXX
 SG_ WindDirection : 136|16@1+ (0.0001,0) [0|6.28318] "rad" Vector__XXX
 SG_ WindSpeed : 120|16@1+ (0.01,0) [0|655.32] "m/s" Vector__XXX
 SG_ StationLocationLongitude : 88|32@1- (1E-007,0) [-180|180] "deg" Vector__XXX
 SG_ StationLocationLatitude : 56|32@1- (1E-007,0) [-90|90] "deg" Vector__XXX
 SG_ MeasurementTime : 24|32@1+ (0.0001,0) [0|86401] "sec" Vector__XXX
 SG_ MeasurementDate : 8|16@1+ (1,0) [0|65532] "day" Vector__XXX
 SG_ Mode : 0|4@1+ (1,0) [0|15] "" Vector__XXX

BO_ 2649823998 MagneticVariation: 8 Vector__XXX
 SG_ Variation : 32|16@1- (0.0001,0) [-3.14159|3.14159] "rad" Vector__XXX
 SG_ AgeOfService : 16|16@1+ (1,0) [0|65532] "day" Vector__XXX
 SG_ VariationSource : 8|4@1+ (1,0) [0|15] "" Vector__XXX
 SG_ SequenceID_ : 0|8@1+ (1,0) [0|252] "" Vector__XXX

BO_ 2382103806 LoranCTDData: 32 Vector__XXX
 SG_ Mode : 248|4@1+ (1,0) [0|15] "" Vector__XXX
 SG_ StationStatusZ : 244|4@1+ (1,0) [0|15] "" Vector__XXX
 SG_ StationStatusY : 240|4@1+ (1,0) [0|15] "" Vector__XXX
 SG_ StationStatusX : 236|4@1+ (1,0) [0|15] "" Vector__XXX
 SG_ StationStatusW : 232|4@1+ (1,0) [0|15] "" Vector__XXX
 SG_ StationStatusV : 228|4@1+ (1,0) [0|15] "" Vector__XXX
 SG_ StationStatusMaster : 224|4@1+ (1,0) [0|15] "" Vector__XXX
 SG_ ZSecondTD : 192|32@1- (1E-009,0) [-2.14|2.14] "sec" Vector__XXX
 SG_ YSecondTD : 160|32@1- (1E-009,0) [-2.14|2.14] "sec" Vector__XXX
 SG_ XSecondTD : 128|32@1- (1E-009,0) [-2.14|2.14] "sec" Vector__XXX
 SG_ WSecondTD : 96|32@1- (1E-009,0) [-2.14|2.14] "sec" Vector__XXX
 SG_ VSecondTD : 64|32@1- (1E-009,0) [-2.14|2.14] "sec" Vector__XXX
 SG_ MasterRange : 32|32@1- (1E-009,0) [-2.14|2.14] "sec" Vector__XXX
 SG_ GroupRepetitionInterval : 0|32@1- (1E-009,0) [-2.14|2.14] "sec" Vector__XXX

BO_ 2382104318 LoranCSignalData: 8 Vector__XXX
 SG_ StationIdentifier : 32|8@1+ (1,0) [0|255] "ASCII" Vector__XXX
 SG_ GroupRepetitionInterval : 0|32@1- (1E-009,0) [-2.14|2.14] "sec" Vector__XXX

BO_ 2382104062 LoranCRangeData: 32 Vector__XXX
 SG_ Mode : 248|4@1+ (1,0) [0|15] "" Vector__XXX
 SG_ StationStatusZ : 244|4@1+ (1,0) [0|15] "" Vector__XXX
 SG_ StationStatusY : 240|4@1+ (1,0) [0|15] "" Vector__XXX
 SG_ StationStatusX : 236|4@1+ (1,0) [0|15] "" Vector__XXX
 SG_ StationStatusW : 232|4@1+ (1,0) [0|15] "" Vector__XXX
 SG_ StationStatusV : 228|4@1+ (1,0) [0|15] "" Vector__XXX
 SG_ StationStatusMaster : 224|4@1+ (1,0) [0|15] "" Vector__XXX
 SG_ ZSecondRange : 192|32@1- (1E-009,0) [-2.14|2.14] "sec" Vector__XXX
 SG_ YSecondRange : 160|32@1- (1E-009,0) [-2.14|2.14] "sec" Vector__XXX
 SG_ XSecondRange : 128|32@1- (1E-009,0) [-2.14|2.14] "sec" Vector__XXX
 SG_ WSecondRange : 96|32@1- (1E-009,0) [-2.14|2.14] "sec" Vector__XXX
 SG_ VSecondRange : 64|32@1- (1E-009,0) [-2.14|2.14] "sec" Vector__XXX
 SG_ MasterRange : 32|32@1- (1E-009,0) [-2.14|2.14] "sec" Vector__XXX
 SG_ GroupRepetitionInterval : 0|32@1- (1E-009,0) [-2.14|2.14] "sec" Vector__XXX

BO_ 2314274302 Heading_TrackCtrl: 21 Vector__XXX
 SG_ VesselHeading : 152|16@1+ (0.0001,0) [0|6.28318] "rad" Vector__XXX
 SG_ OffTrackLimit : 136|16@1- (1,0) [-32764|32764] "m" Vector__XXX
 SG_ RateOfTurnder : 120|16@1- (1,0) [-1|1] "rad/s" Vector__XXX
 SG_ RadiusOfTurnder : 104|16@1- (1,0) [-32764|32764] "m" Vector__XXX
 SG_ OffHeadingLimit : 88|16@1+ (0.0001,0) [0|6.28318] "rad" Vector__XXX
 SG_ RudderLimit : 72|16@1+ (0.0001,0) [0|6.28318] "rad" Vector__XXX
 SG_ Track : 56|16@1+ (0.0001,0) [0|6.28318] "rad" Vector__XXX
 SG_ HeadingToSteer : 40|16@1+ (0.0001,0) [0|6.28318] "rad" Vector__XXX
 SG_ CmdedRudderAngle : 24|16@1- (0.0001,0) [-3.14159|3.14159] "rad" Vector__XXX
 SG_ CmdedRudderDirection : 21|3@1+ (1,0) [0|7] "" Vector__XXX
 SG_ HeadingReference : 14|2@1+ (1,0) [0|3] "" Vector__XXX
 SG_ TurnMode : 11|3@1+ (1,0) [0|7] "" Vector__XXX
 SG_ SteerMode : 8|3@1+ (1,0) [0|7] "" Vector__XXX
 SG_ Override : 6|2@1+ (1,0) [0|3] "" Vector__XXX
 SG_ OffTrackLimitExceeded : 4|2@1+ (1,0) [0|3] "" Vector__XXX
 SG_ OffHeadingLimitExceeded : 2|2@1+ (1,0) [0|3] "" Vector__XXX
 SG_ RudderLimitExceeded : 0|2@1+ (1,0) [0|3] "" Vector__XXX

BO_ 2583299582 GPSAlmanacData: 26 Vector__XXX
 SG_ ClockParameter2 : 195|11@1+ (1,0) [0|2047] "" Vector__XXX
 SG_ ClockParameter1 : 184|11@1+ (1,0) [0|2047] "" Vector__XXX
 SG_ MeanAnomaly : 160|24@1+ (1,0) [0|16777215] "" Vector__XXX
 SG_ LongitudeOfAscensionNode : 136|24@1+ (1,0) [0|16777215] "" Vector__XXX
 SG_ ArgumentOfPerigee : 112|24@1+ (1,0) [0|16777215] "" Vector__XXX
 SG_ RootOfSemimajorAxis : 88|24@1+ (1,0) [0|16777215] "" Vector__XXX
 SG_ RateOfRightAscension : 72|16@1+ (1,0) [0|65535] "" Vector__XXX
 SG_ InclinationAngle : 56|16@1+ (1,0) [0|65535] "" Vector__XXX
 SG_ AlmanacReferenceTime : 48|8@1+ (1,0) [0|255] "" Vector__XXX
 SG_ Eccentricity : 32|16@1+ (1,0) [0|65535] "" Vector__XXX
 SG_ SVHealthBits : 24|8@1+ (1,0) [0|255] "" Vector__XXX
 SG_ GPSWeekNumber : 8|16@1+ (1,0) [0|65532] "" Vector__XXX
 SG_ PRN : 0|8@1+ (1,0) [0|252] "" Vector__XXX

BO_ 2583299326 GNSSSatsInView: 27 Vector__XXX
 SG_ PRNStatusN : 208|4@1+ (1,0) [0|15] "" Vector__XXX
 SG_ RangeResidualsN : 176|32@1- (1E-005,0) [-21470|21470] "m" Vector__XXX
 SG_ SNRN : 160|16@1- (0.01,0) [-327.64|327.64] "dB" Vector__XXX
 SG_ AzimuthN : 144|16@1+ (0.0001,0) [0|6.28318] "rad" Vector__XXX
 SG_ ElevationN : 128|16@1- (0.0001,0) [-3.14159|3.14159] "rad" Vector__XXX
 SG_ PRNN : 120|8@1+ (1,0) [0|252] "" Vector__XXX
 SG_ PRNStatus1 : 112|4@1+ (1,0) [0|15] "" Vector__XXX
 SG_ RangeResiduals1 : 80|32@1- (1E-005,0) [-21470|21470] "m" Vector__XXX
 SG_ SNR1 : 64|16@1- (0.01,0) [-327.64|327.64] "dB" Vector__XXX
 SG_ Azimuth1 : 48|16@1+ (0.0001,0) [0|6.28318] "rad" Vector__XXX
 SG_ Elevation1 : 32|16@1- (0.0001,0) [-3.14159|3.14159] "rad" Vector__XXX
 SG_ PRN1 : 24|8@1+ (1,0) [0|252] "" Vector__XXX
 SG_ NumberOfSVs_ : 16|8@1+ (1,0) [0|252] "" Vector__XXX
 SG_ SID : 0|8@1+ (1,0) [0|252] "" Vector__XXX
 SG_ RangeResidualMode : 8|2@1- (1,0) [0|3] "" Vector__XXX

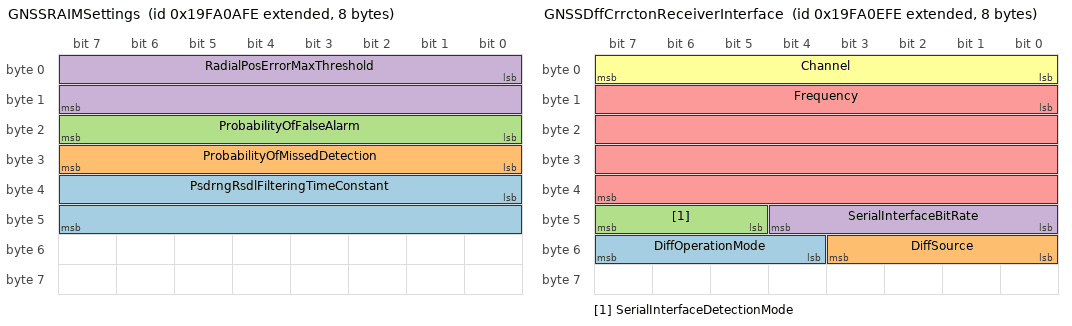
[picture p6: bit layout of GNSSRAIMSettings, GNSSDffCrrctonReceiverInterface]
BO_ 2583300862 GNSSRAIMSettings: 8 Vector__XXX
 SG_ PsdrngRsdlFilteringTimeConstant : 32|16@1+ (1,0) [0|65532] "sec" Vector__XXX
 SG_ ProbabilityOfMissedDetection : 24|8@1- (1,0) [-124|124] "%" Vector__XXX
 SG_ ProbabilityOfFalseAlarm : 16|8@1- (1,0) [-124|124] "" Vector__XXX
 SG_ RadialPosErrorMaxThreshold : 0|16@1+ (0.01,0) [0|655.32] "m" Vector__XXX

BO_ 2583300606 GNSSRAIMOutput: 15 Vector__XXX
 SG_ StdDeviationOfBias : 104|16@1- (0.01,0) [-327.64|327.64] "m" Vector__XXX
 SG_ EstimateOfPseudorangeBias : 88|16@1- (0.01,0) [-327.64|327.64] "m" Vector__XXX
 SG_ ProbabilityOfMissedDetection : 72|8@1- (1,0) [-124|124] "%" Vector__XXX
 SG_ SVIDOfMostLikelyFailedSat : 64|8@1+ (1,0) [0|252] "" Vector__XXX
 SG_ AltitudeExpectedError : 48|16@1- (0.01,0) [-327.64|327.64] "m" Vector__XXX
 SG_ LongitudeExpectedError : 32|16@1- (0.01,0) [-327.64|327.64] "m" Vector__XXX
 SG_ LatitudeExpectedError : 16|16@1- (0.01,0) [-327.64|327.64] "m" Vector__XXX
 SG_ IntegrityFlag : 8|2@1+ (1,0) [0|3] "" Vector__XXX
 SG_ SequenceID_ : 0|8@1+ (1,0) [0|252] "" Vector__XXX

BO_ 2583299838 GNSSPseudorangeNoiseStatistics: 15 Vector__XXX
 SG_ STDOfAltError : 104|16@1+ (0.01,0) [0|655.32] "m" Vector__XXX
 SG_ STDOfLonError : 88|16@1+ (0.01,0) [0|655.32] "m" Vector__XXX
 SG_ STDOfLatError : 72|16@1+ (0.01,0) [0|655.32] "m" Vector__XXX
 SG_ OrientationOfMajorAxis : 56|16@1+ (0.0001,0) [0|6.28318] "rad" Vector__XXX
 SG_ STDOfMinorAxis : 40|16@1+ (0.01,0) [0|655.32] "m" Vector__XXX
 SG_ STDOfMajorAxis : 24|16@1+ (0.01,0) [0|655.32] "m" Vector__XXX
 SG_ RMSOfPosUncertainty : 8|16@1+ (0.01,0) [0|655.32] "m" Vector__XXX
 SG_ SID : 0|8@1+ (1,0) [0|252] "" Vector__XXX

BO_ 2583301118 GNSSPseudorangeErrorStatistics: 15 Vector__XXX
 SG_ StdDevAltitudeError : 104|16@1+ (0.01,0) [0|655.32] "m" Vector__XXX
 SG_ StdDevLongitudeError : 88|16@1+ (0.01,0) [0|655.32] "m" Vector__XXX
 SG_ StdDevLatitudeError : 72|16@1+ (0.01,0) [0|655.32] "m" Vector__XXX
 SG_ OrientationOfErrorEllipse : 56|16@1+ (0.0001,0) [0|6.28318] "rad" Vector__XXX
 SG_ StdDevMinorErrorEllipse : 40|16@1+ (0.01,0) [0|655.32] "m" Vector__XXX
 SG_ StdDevMajorErrorEllipse : 24|16@1+ (0.01,0) [0|655.32] "m" Vector__XXX
 SG_ RMSStdDevOfRangeInputs : 8|16@1+ (0.01,0) [0|655.32] "m" Vector__XXX
 SG_ SequenceID_ : 0|8@1+ (1,0) [0|252] "" Vector__XXX

BO_ 2381841918 GNSSPosData: 51 Vector__XXX
 SG_ AgeOfDGNSSReferenceStationN : 392|16@1+ (0.01,0) [0|655.32] "sec" Vector__XXX
 SG_ ReferenceStationIDN : 380|12@1+ (1,0) [0|4095] "" Vector__XXX
 SG_ ReferenceStationTypeN : 376|4@1+ (1,0) [0|15] "" Vector__XXX
 SG_ AgeOfDGNSSCorrections1_ : 360|16@1+ (0.01,0) [0|655.32] "sec" Vector__XXX
 SG_ ReferenceStationID1_ : 348|12@1+ (1,0) [0|4095] "" Vector__XXX
 SG_ ReferenceStationType1 : 344|4@1+ (1,0) [0|15] "" Vector__XXX
 SG_ NumberOfReferenceStations_ : 336|8@1+ (1,0) [0|252] "" Vector__XXX
 SG_ GeoidalSeparation_ : 304|32@1- (0.01,0) [-21470000|21470000] "m" Vector__XXX
 SG_ PDOP_ : 288|16@1- (0.01,0) [-327.64|327.64] "" Vector__XXX
 SG_ HDOP_ : 272|16@1- (0.01,0) [-327.64|327.64] "" Vector__XXX
 SG_ NumberOfSVs_ : 264|8@1+ (1,0) [0|252] "" Vector__XXX
 SG_ Integrity : 256|2@1+ (1,0) [0|3] "" Vector__XXX
 SG_ MethodGNSS : 252|4@1+ (1,0) [0|15] "" Vector__XXX
 SG_ TypeOfSystem_ : 248|4@1+ (1,0) [0|15] "" Vector__XXX
 SG_ Altitude_high : 216|32@1- (4294.967296,0) [-9223000000000|9223000000000] "m" Vector__XXX
 SG_ Altitude_low : 184|32@1+ (1E-006,0) [0|4294.967295] "m" Vector__XXX
 SG_ Longitude_high : 152|32@1- (4.294967296E-007,0) [-180|180] "deg" Vector__XXX
 SG_ Longitude_low : 120|32@1+ (1E-016,0) [0|4.294967295E-007] "deg" Vector__XXX
 SG_ Latitude_high : 88|32@1- (4.294967296E-007,0) [-90|90] "deg" Vector__XXX
 SG_ Latitude_low : 56|32@1+ (1E-016,0) [0|4.294967295E-007] "deg" Vector__XXX
 SG_ PosTime : 24|32@1+ (0.0001,0) [0|86401] "sec" Vector__XXX
 SG_ PosDate : 8|16@1+ (1,0) [0|65532] "day" Vector__XXX
 SG_ SID : 0|8@1+ (1,0) [0|252] "" Vector__XXX

BO_ 2583301886 GNSSDffCrrctonReceiverInterface: 8 Vector__XXX
 SG_ DiffOperationMode : 52|4@1+ (1,0) [0|15] "" Vector__XXX
 SG_ DiffSource : 48|4@1+ (1,0) [0|15] "" Vector__XXX
 SG_ SerialInterfaceDetectionMode : 45|3@1+ (1,0) [0|7] "" Vector__XXX
 SG_ SerialInterfaceBitRate : 40|5@1+ (1,0) [0|31] "" Vector__XXX
 SG_ Frequency : 8|32@1+ (10,0) [0|327040] "Hz" Vector__XXX
 SG_ Channel : 0|8@1+ (1,0) [0|252] "" Vector__XXX

BO_ 2583302142 GNSSDffCorrectionReceiverSignal: 21 Vector__XXX
 SG_ SatelliteServiceIDNo : 147|16@1+ (1,0) [0|65535] "" Vector__XXX
 SG_ TimeSinceLastSatDiffSync : 131|16@1+ (0.01,0) [0|655.32] "sec" Vector__XXX
 SG_ DiffSource : 127|4@1+ (1,0) [0|15] "" Vector__XXX
 SG_ UsedAsCorrectionSource : 123|2@1+ (1,0) [0|3] "" Vector__XXX
 SG_ DiffSignalDetectionMode : 117|6@1+ (1,0) [0|63] "" Vector__XXX
 SG_ DiffSignalBitRate : 112|5@1+ (1,0) [0|31] "" Vector__XXX
 SG_ StationID : 100|12@1+ (1,0) [0|4095] "" Vector__XXX
 SG_ StationType : 96|4@1+ (1,0) [0|15] "" Vector__XXX
 SG_ Frequency : 64|32@1+ (10,0) [0|327040] "Hz" Vector__XXX
 SG_ SignalSNR : 48|16@1- (0.01,0) [-327.64|327.64] "dB" Vector__XXX
 SG_ SignalStrength : 16|32@1- (0.01,0) [-327.64|327.64] "dB re: uV/m" Vector__XXX
 SG_ Channel : 8|8@1+ (1,0) [0|252] "" Vector__XXX
 SG_ SID : 0|8@1+ (1,0) [0|252] "" Vector__XXX

CM_ BU_ HitchControl "Straight truck hitch (NOT Agricultural hitch – it is in IG 2) ";
CM_ BO_ 3221225472 "This is a message for not used signals, created by Vector CANdb++ DBC OLE DB Provider.";
CM_ SG_ 3221225472 TrailerWeight "Total mass of freight-carrying vehicle designed to be pulled by truck, including the weight of the contents.";
CM_ SG_ 3221225472 ReferenceTirePressSetting "Reference value of the tire pressure setting as basis for the tire pressure monitoring";
CM_ SG_ 3221225472 ReferenceTirePress "Reference value of the tire pressure as basis for the tire pressure monitoring";
CM_ SG_ 3221225472 TirePressThresholdDetection "Signal indicating the pressure level of the tire. The levels defined represent different pressure conditions of the tire:";
CM_ SG_ 3221225472 TireAirLeakageRate "The pressure loss rate of a tire.";
CM_ SG_ 3221225472 CTIWheelEndElectricalFault "Indicates the status of electrical fault on CTI wheel interface.";
CM_ SG_ 3221225472 CTITireStatus "Indicates the status of the tire.";
CM_ SG_ 3221225472 CTIWheelSensorStatus "Indicates whether the wheel is being monitored by the CTI controller.";
CM_ SG_ 3221225472 TireTemp "Temperature at the surface of the tire sidewall.";
CM_ SG_ 3221225472 TirePress "Pressure at which air is contained in cavity formed by tire and rim.";
CM_ SG_ 3221225472 EngTurningGearEngaged "Status signal which indicates that the turning gear is engaged. The turning gear is used to turn the flywheel/crankshaft,";
CM_ SG_ 3221225472 MalfunctionIndicatorLampStatus "A lamp used to relay only emissions-related trouble code information.";
CM_ SG_ 3221225472 RedStopLampState "This lamp is uesed to relay trouble code information that is of a severe enought condition that it warrants stopping the vehicle.";
CM_ SG_ 3221225472 AmberWarningLampStatus "This lamp is used to relay trouble code information that is reporting a problem with the vehicle system but the vehicle need
not be immediately stopped.";
CM_ SG_ 3221225472 ProtectLampStatus "This lamp is used to relay trouble code informatio that is reporting a problem with a vehicle system that is most
probably not electronic subsystem related.";
CM_ SG_ 3221225472 FlashRedStopLamp "This parameter provides the capability to flash the RSL (SPN 3039).";
CM_ SG_ 3221225472 FlashProtectLamp "This parameter provides the capability to flash the engine protect lamp (SPN 3041).";
CM_ SG_ 3221225472 FlashMalfuncIndicatorLamp "This parameter provides the capability to flash the MIL (SPN 3038).";
CM_ SG_ 3221225472 FlashAmberWarningLamp "This parameter provides the capability to flash the AWL (SPN 3040). ";
CM_ SG_ 3221225472 DTC5 "Diagnostic Trouble Code";
CM_ SG_ 3221225472 DTC4 "Diagnostic Trouble Code";
CM_ SG_ 3221225472 DTC3 "Diagnostic Trouble Code";
CM_ SG_ 3221225472 DTC2 "Diagnostic Trouble Code";
CM_ SG_ 3221225472 DTC1 "Diagnostic Trouble Code";
CM_ BO_ 2566835198 "Active diagnostic trouble codes";
CM_ SG_ 2566835198 FlashRedStopLamp "This parameter provides the capability to flash the RSL (SPN 3039).";
CM_ SG_ 2566835198 FlashProtectLamp "This parameter provides the capability to flash the engine protect lamp (SPN 3041).";
CM_ SG_ 2566835198 FlashMalfuncIndicatorLamp "This parameter provides the capability to flash the MIL (SPN 3038).";
CM_ SG_ 2566835198 FlashAmberWarningLamp "This parameter provides the capability to flash the AWL (SPN 3040). ";
CM_ SG_ 2566835198 MalfunctionIndicatorLampStatus "A lamp used to relay only emissions-related trouble code information.";
CM_ SG_ 2566835198 AmberWarningLampStatus "This lamp is used to relay trouble code information that is reporting a problem with the vehicle system but the vehicle need
not be immediately stopped.";
CM_ SG_ 2566835198 RedStopLampState "This lamp is uesed to relay trouble code information that is of a severe enought condition that it warrants stopping the vehicle.";
CM_ SG_ 2566835198 ProtectLampStatus "This lamp is used to relay trouble code informatio that is reporting a problem with a vehicle system that is most
probably not electronic subsystem related.";
CM_ BO_ 2315059966 "Direction and speed of Wind.True wind can be referenced to vessel to ground.Apparent Wind is what is felt standing on the(moving)ship,I.e.,wind measured by typical mast head instruments.
boat referenced true wind is given by vector sum of Apparent wind a";
CM_ SG_ 2315059966 WindReference "0x00 = True (referenced to North)
0x01 = Magnetic
0x02 = Apparent
0x03 = True (boat referenced)
0x04 = Reserved
0x05 = Reserved
0x06 = Error
0x07 = Null";
CM_ SG_ 2315059966 SequenceID_ "An upward counting number used to tie related information together between different PGNs.For example,SID would be used to tie together COG,SOG and RAIM values to a given Pos.255=no valid Pos fix to tie it to.Range 0 to 250 for valid Pos fixes.";
CM_ BO_ 2381646846 "Water depth relative to transducer and offset of measuring transducer.Positive offset numbers provide distance from transducer to waterline.Negative offset numbers provide distance from transducer to part of keel of interest.";
CM_ SG_ 2381646846 Offset "Positive values represent distance from transducer to water line and negative values represent distance from the transducer to the keel.";
CM_ SG_ 2381646846 WaterDepthTransducer "Depth relative to the transducer location.  Range of value specified in 'Maximum Range' field.";
CM_ SG_ 2381646846 SID "An upward counting number used to tie related information together between different PGNs.For example,SID would be used to tie together COG,SOG and RAIM values to a given Pos.255=no valid Pos fix to tie it to.Range 0 to 250 for valid Pos fixes.";
CM_ BO_ 2315129598 "This PGN provides a single Trans that accurately describes speed of a vessel by component vectors.

This information is relevant for large vessels and would typically be provided by a product that interfaces to sensors such as dual axis logs.Products th";
CM_ SG_ 2315129598 SternSpeedGroundreferenced "Positive values represent ahead or starboard transverse speed and negative values represent astern or port transverse speed.";
CM_ SG_ 2315129598 SternSpeedWaterreferenced "Positive values represent ahead or starboard transverse speed and negative values represent astern or port transverse speed.";
CM_ SG_ 2315129598 TransverseSpeedGroundreferenced "Positive values represent ahead or starboard transverse speed and negative values represent astern or port transverse speed.";
CM_ SG_ 2315129598 LngtudinalSpeedGroundreferenced "Positive values represent ahead or starboard transverse speed and negative values represent astern or port transverse speed.";
CM_ SG_ 2315129598 TransverseSpeedWaterreferenced "Positive values represent ahead or starboard transverse speed and negative values represent astern or port transverse speed.";
CM_ SG_ 2315129598 LngitudinalSpeedWaterreferenced "Positive values represent ahead or starboard transverse speed and negative values represent astern or port transverse speed.";
CM_ BO_ 2314277630 "Heading sensor value with a flag for True Magnetic.If sensor value is Magnetic,deviation field can be used to produce a Magnetic heading,and variation field can be used to correct Magnetic heading to produce a True heading.

To obtain Magnetic Heading f";
CM_ SG_ 2314277630 HeadingSensorReference "0 = True, 
1 = Magnetic, 
2 = Error, 
3 = Null";
CM_ SG_ 2314277630 Variation "Positive values are Easterly and negative values are Westerly.";
CM_ SG_ 2314277630 Deviation "Positive values are Easterly and negative values are Westerly.";
CM_ SG_ 2314277630 HeadingSensorReading "Primary output of heading as indicated by the heading sensor.";
CM_ SG_ 2314277630 SID "An upward counting number used to tie related information together between different PGNs.For example,SID would be used to tie together COG,SOG and RAIM values to a given Pos.255=no valid Pos fix to tie it to.Range 0 to 250 for valid Pos fixes.";
CM_ BO_ 2583172606 "Transformation parameters for converting from WGS-84 to other Datums.";
CM_ SG_ 2583172606 DatumName "4-character code for datum currently being output for Pos solution.datum's are defined in IHO Publication S-60,Appendices B and C.first three chars are datum ID as per IHO tables.fourth char is local datum subdivision code.A null char indicates datum subd";
CM_ SG_ 2583172606 EllipsoidFlatteningInverse "Flattening (1/f) of the user Datum ellipsoid.";
CM_ SG_ 2583172606 EllipsoidSemimajorAxis "Semi-major axis (a) of the User Datum ellipsoid.";
CM_ SG_ 2583172606 Scale "Scale factor expressed in parts-per-million";
CM_ SG_ 2583172606 RotationInZ "Rotational shift in X, Y, or Z axis from WGS 84.  Rotations presented use the geodetic sign convention.  When looking along the positive axis towards the origin, counter-clockwise rotations are positive.";
CM_ SG_ 2583172606 RotationInY "Rotational shift in X, Y, or Z axis from WGS 84.  Rotations presented use the geodetic sign convention.  When looking along the positive axis towards the origin, counter-clockwise rotations are positive.";
CM_ SG_ 2583172606 RotationInX "Rotational shift in X, Y, or Z axis from WGS 84.  Rotations presented use the geodetic sign convention.  When looking along the positive axis towards the origin, counter-clockwise rotations are positive.";
CM_ SG_ 2583172606 DeltaZ "Delta Shift in X, Y, or Z axis from WGS 84.";
CM_ SG_ 2583172606 DeltaY "Delta Shift in X, Y, or Z axis from WGS 84.";
CM_ SG_ 2583172606 DeltaX "Delta Shift in X, Y, or Z axis from WGS 84.";
CM_ BO_ 2515667198 "Trip parameters relative to Vessel";
CM_ BO_ 2515667454 "Engine related trip information.";
CM_ SG_ 2515667454 EngInstance "For Engs:
0 = Instance 0;          0 = Single Eng Dual Eng Port
1 = Instance 1;          1 = Dual Eng StarBoard  
                                  (for Multiple Engs,Instances will start 
        thru                            from Bow,Port(0)to Ste";
CM_ BO_ 2314339838 "Used to provide operational state and internal operating parameters of a specific Trans,indicated by Trans instance field.This Msg would normally be broadcasted periodically to provide information for instrumentation Ctrl functions.";
CM_ SG_ 2314339838 TransDiscreteStatus "xxxx xxx1 = Check Tranmission,
xxxx xx1x = Over Temp,
xxxx x1xx = Low Oil Press,
xxxx 1xxx = Low Oil Level,
xxx1 xxxx = Sail Drive,
xx1x xxxx = reserved,
x1xx xxxx = reserved,
1xxx xxxx = reserved,
                    where x = don't care";
CM_ SG_ 2314339838 TransGear "0 = Forward.
1 = Neutral,
2 = Reverse,
3 = [Unavailable, Unknown]";
CM_ SG_ 2314339838 TransInstance "For Engs:
0 = Instance 0;          0 = Single Eng Dual Eng Port
1 = Instance 1;          1 = Dual Eng StarBoard  
                                  (for Multiple Engs,Instances will start 
        thru                            from Bow,Port(0)to Ste";
CM_ BO_ 2314602750 "Message for reporting status and target data from tracking radar external devices.  The reporting interval will vary by the values for target status and quantity of track data files.";
CM_ SG_ 2314602750 Course "Degrees clockwise relative to True North.";
CM_ SG_ 2314602750 Bearing "Degrees clockwise relative to True North.";
CM_ SG_ 2314602750 BearingReference "0 = True, 
1 = Magnetic, 
2 = Error, 
3 = Releative";
CM_ SG_ 2314602750 TrackStatus "xx00 = Cancelled Not Available,
xx01 = Initial Acquisition Target,
xx10 = Tracking Target,
xx11 = Lost Target,
x0xx = Reported Target No,
x1xx = Reported Target Yes,
0xxx = Acquision Manual,
1xxx = Acquision Auto,
                    where x = don";
CM_ SG_ 2314602750 TargetID "Number of route, waypoint, event, mark, etc.";
CM_ SG_ 2314602750 SequenceID_ "An upward counting number used to tie related information together between different PGNs.For example,SID would be used to tie together COG,SOG and RAIM values to a given Pos.255=no valid Pos fix to tie it to.Range 0 to 250 for valid Pos fixes.";
CM_ SG_ 2314602750 Name "Name of place, route, waypoint, destination, vessel, vehicle, etc.";
CM_ SG_ 2314602750 UTCOfFix "24 hour clock, 0 =  midnight,  time is in UTC";
CM_ SG_ 2314602750 TCPA "Time interval in milli-sec.  '-'  = time elapsed since event, '+' = time to go before event.";
CM_ BO_ 2381842942 "This PGN has a single transmission that provides:

- UTC Time
- UTC Date
- Local offset

Products that can maintain or have a method of calculating or manually providing local offset should transmit this PGN.";
CM_ SG_ 2381842942 LocalOffsetMinutes "Local time zone offset in minutes.  Local time zone is added to local time to obtain UTC.  Local zone is generally negative for East longitudes, with local exceptions near the International Date Line.";
CM_ SG_ 2381842942 Time "24 hour clock, 0 =  midnight,  time is in UTC";
CM_ SG_ 2381842942 Date "Days since January 1, 1970,   Date is relative to UTC Time.";
CM_ BO_ 2381911550 "Time to go to elapsed from a generic mark,that may be non-fixed.mark is not generally a specific geographic point but may vary continuously and is most often determined by calculation(recommended turning tacking point for sailing vessels,wheel-over point ";
CM_ SG_ 2381911550 MarkID "Number of route, waypoint, event, mark, etc.";
CM_ SG_ 2381911550 MarkType "0   = Collision, 
  1   = Turning Point, 
  2   = Reference (general), 
  3   = Wheelover, 
  4   = Waypoint, 
5-13 = Reserved, 
 14  = Error, 
 15  = Null";
CM_ SG_ 2381911550 TimeElapsedTogoToMark "Time interval in milli-sec.  '-'  = time elapsed since event, '+' = time to go before event.";
CM_ SG_ 2381911550 SID "An upward counting number used to tie related information together between different PGNs.For example,SID would be used to tie together COG,SOG and RAIM values to a given Pos.255=no valid Pos fix to tie it to.Range 0 to 250 for valid Pos fixes.";
CM_ BO_ 2583499006 "Tide station measurement data including station location, numeric identifier, and name.";
CM_ SG_ 2583499006 StationIDString "Name of place, route, waypoint, destination, vessel, vehicle, etc.";
CM_ SG_ 2583499006 TideLevelStandardDeviation "following text is from NOAA and is placed here to convey an understanding of expected magnitude of values.'tide gage processes 181 water level samples,1 second apart,centered on 6 minute mark.It then computes standard deviation of Samples.Samples more tha";
CM_ SG_ 2583499006 TideLevel "This value is relative to mean lower low water (MLLW).";
CM_ SG_ 2583499006 MeasurementTime "24 hour clock, 0 =  midnight,  time is in UTC";
CM_ SG_ 2583499006 MeasurementDate "Days since January 1, 1970,   Date is relative to UTC Time.";
CM_ SG_ 2583499006 TideTendency "msb/lsb: 
00 = Falling, 
01 = Rising, 
10 = Error, 
11 = Unavailable, Unknown";
CM_ SG_ 2583499006 Mode "Range Residual used in position calculation or range residuals were calculated after the position.  
0=range residuals were used to calculate data; 
1=range residuals were calculated after the position., 
2=Error, 
3=Null";
CM_ BO_ 2381320446 "The purpose of this PGN is twofold:

- To provide a regular transmission of UTC time and date
- To provide synchronism for measurement data";
CM_ SG_ 2381320446 Time "24 hour clock, 0 =  midnight,  time is in UTC";
CM_ SG_ 2381320446 Date "Days since January 1, 1970,   Date is relative to UTC Time.";
CM_ SG_ 2381320446 Source "0x0 = GPS, 
0x1 =GLONASS, 
0x2 = WWV or equivalent Radio Station Time Sync, 
0x3 = Local Cesium clock, 
0x4 = Local Rubidium clock, 
0x5 = Local Crystal clock, 
0x6 - 0xE = reserved, 
0xF = Null";
CM_ SG_ 2381320446 SID "An upward counting number used to tie related information together between different PGNs.For example,SID would be used to tie together COG,SOG and RAIM values to a given Pos.255=no valid Pos fix to tie it to.Range 0 to 250 for valid Pos fixes.";
CM_ BO_ 2381451006 "Universal commands to multiple banks of two-state devices.";
CM_ SG_ 2381451006 Switch28 "00 = [Turn Off, Disable, Reset, Make '0'],
01 = [Turn On, Enable, Set, Make '1'],
02  = Reserved,
03  = No action";
CM_ SG_ 2381451006 Switch27 "00 = [Turn Off, Disable, Reset, Make '0'],
01 = [Turn On, Enable, Set, Make '1'],
02  = Reserved,
03  = No action";
CM_ SG_ 2381451006 Switch26 "00 = [Turn Off, Disable, Reset, Make '0'],
01 = [Turn On, Enable, Set, Make '1'],
02  = Reserved,
03  = No action";
CM_ SG_ 2381451006 Switch25 "00 = [Turn Off, Disable, Reset, Make '0'],
01 = [Turn On, Enable, Set, Make '1'],
02  = Reserved,
03  = No action";
CM_ SG_ 2381451006 Switch24 "00 = [Turn Off, Disable, Reset, Make '0'],
01 = [Turn On, Enable, Set, Make '1'],
02  = Reserved,
03  = No action";
CM_ SG_ 2381451006 Switch23 "00 = [Turn Off, Disable, Reset, Make '0'],
01 = [Turn On, Enable, Set, Make '1'],
02  = Reserved,
03  = No action";
CM_ SG_ 2381451006 Switch22 "00 = [Turn Off, Disable, Reset, Make '0'],
01 = [Turn On, Enable, Set, Make '1'],
02  = Reserved,
03  = No action";
CM_ SG_ 2381451006 Switch21 "00 = [Turn Off, Disable, Reset, Make '0'],
01 = [Turn On, Enable, Set, Make '1'],
02  = Reserved,
03  = No action";
CM_ SG_ 2381451006 Switch20 "00 = [Turn Off, Disable, Reset, Make '0'],
01 = [Turn On, Enable, Set, Make '1'],
02  = Reserved,
03  = No action";
CM_ SG_ 2381451006 Switch19 "00 = [Turn Off, Disable, Reset, Make '0'],
01 = [Turn On, Enable, Set, Make '1'],
02  = Reserved,
03  = No action";
CM_ SG_ 2381451006 Switch18 "00 = [Turn Off, Disable, Reset, Make '0'],
01 = [Turn On, Enable, Set, Make '1'],
02  = Reserved,
03  = No action";
CM_ SG_ 2381451006 Switch17 "00 = [Turn Off, Disable, Reset, Make '0'],
01 = [Turn On, Enable, Set, Make '1'],
02  = Reserved,
03  = No action";
CM_ SG_ 2381451006 Switch16 "00 = [Turn Off, Disable, Reset, Make '0'],
01 = [Turn On, Enable, Set, Make '1'],
02  = Reserved,
03  = No action";
CM_ SG_ 2381451006 Switch15 "00 = [Turn Off, Disable, Reset, Make '0'],
01 = [Turn On, Enable, Set, Make '1'],
02  = Reserved,
03  = No action";
CM_ SG_ 2381451006 Switch14 "00 = [Turn Off, Disable, Reset, Make '0'],
01 = [Turn On, Enable, Set, Make '1'],
02  = Reserved,
03  = No action";
CM_ SG_ 2381451006 Switch13 "00 = [Turn Off, Disable, Reset, Make '0'],
01 = [Turn On, Enable, Set, Make '1'],
02  = Reserved,
03  = No action";
CM_ SG_ 2381451006 Switch12 "00 = [Turn Off, Disable, Reset, Make '0'],
01 = [Turn On, Enable, Set, Make '1'],
02  = Reserved,
03  = No action";
CM_ SG_ 2381451006 Switch11 "00 = [Turn Off, Disable, Reset, Make '0'],
01 = [Turn On, Enable, Set, Make '1'],
02  = Reserved,
03  = No action";
CM_ SG_ 2381451006 Switch10 "00 = [Turn Off, Disable, Reset, Make '0'],
01 = [Turn On, Enable, Set, Make '1'],
02  = Reserved,
03  = No action";
CM_ SG_ 2381451006 Switch9 "00 = [Turn Off, Disable, Reset, Make '0'],
01 = [Turn On, Enable, Set, Make '1'],
02  = Reserved,
03  = No action";
CM_ SG_ 2381451006 Switch8 "00 = [Turn Off, Disable, Reset, Make '0'],
01 = [Turn On, Enable, Set, Make '1'],
02  = Reserved,
03  = No action";
CM_ SG_ 2381451006 Switch7 "00 = [Turn Off, Disable, Reset, Make '0'],
01 = [Turn On, Enable, Set, Make '1'],
02  = Reserved,
03  = No action";
CM_ SG_ 2381451006 Switch6 "00 = [Turn Off, Disable, Reset, Make '0'],
01 = [Turn On, Enable, Set, Make '1'],
02  = Reserved,
03  = No action";
CM_ SG_ 2381451006 Switch5 "00 = [Turn Off, Disable, Reset, Make '0'],
01 = [Turn On, Enable, Set, Make '1'],
02  = Reserved,
03  = No action";
CM_ SG_ 2381451006 Switch4 "00 = [Turn Off, Disable, Reset, Make '0'],
01 = [Turn On, Enable, Set, Make '1'],
02  = Reserved,
03  = No action";
CM_ SG_ 2381451006 Switch3 "00 = [Turn Off, Disable, Reset, Make '0'],
01 = [Turn On, Enable, Set, Make '1'],
02  = Reserved,
03  = No action";
CM_ SG_ 2381451006 Switch2 "00 = [Turn Off, Disable, Reset, Make '0'],
01 = [Turn On, Enable, Set, Make '1'],
02  = Reserved,
03  = No action";
CM_ SG_ 2381451006 Switch1 "00 = [Turn Off, Disable, Reset, Make '0'],
01 = [Turn On, Enable, Set, Make '1'],
02  = Reserved,
03  = No action";
CM_ SG_ 2381451006 SwitchBankInstance "Number of route, waypoint, event, mark, etc.";
CM_ BO_ 2314535934 "The purpose of this PGN is to provide a single transmission that describes the motion of a vessel.";
CM_ SG_ 2314535934 SequenceID_ "An upward counting number used to tie related information together between different PGNs.For example,SID would be used to tie together COG,SOG and RAIM values to a given Pos.255=no valid Pos fix to tie it to.Range 0 to 250 for valid Pos fixes.";
CM_ BO_ 2315129086 "Provides data on various small craft control surfaces and speed through the water. Used primarily by display or instrumentation devices.";
CM_ BO_ 2381908990 "Set and Drift effect on Vessel is direction and speed of  a current.Course&Speed(through water)vector added to Set&Drift vector is COG&SOG vector.bearings may be True Magnetic referenced.
When Set&Drift is calculated from data from a GPS,a compass and a ";
CM_ SG_ 2381908990 Set "Direction towards which current flows.  Degrees relative to True North.";
CM_ SG_ 2381908990 SetReference "0 = True, 
1 = Magnetic, 
2 = Error, 
3 = Null";
CM_ SG_ 2381908990 SID "An upward counting number used to tie related information together between different PGNs.For example,SID would be used to tie together COG,SOG and RAIM values to a given Pos.255=no valid Pos fix to tie it to.Range 0 to 250 for valid Pos fixes.";
CM_ BO_ 2583499262 "Salinity station measurement data including station location, numeric identifier, and name.";
CM_ SG_ 2583499262 StationIDString "Name of place, route, waypoint, destination, vessel, vehicle, etc.";
CM_ SG_ 2583499262 Salinity "The average Salinity of ocean water is about 35 grams of salts per kilogram of sea water (g/kg), usually written as 35 ppt which is read as 35 parts per thousand.";
CM_ SG_ 2583499262 MeasurementTime "24 hour clock, 0 =  midnight,  time is in UTC";
CM_ SG_ 2583499262 MeasurementDate "Days since January 1, 1970,   Date is relative to UTC Time.";
CM_ SG_ 2583499262 Mode "Range Residual used in position calculation or range residuals were calculated after the position.  
0=range residuals were used to calculate data; 
1=range residuals were calculated after the position., 
2=Error, 
3=Null";
CM_ BO_ 2650544894 "Complex Rq of this PGN should return Waypoints of a WP-List.

WARNING:Route Track may not be defined by Waypoint Poss only:Navigation Method(GC/RL)and Radius of Turn at each Waypoint are optional additional parameters defining Track.
PGN 130066 field #";
CM_ SG_ 2650544894 WPName "Name of place, route, waypoint, destination, vessel, vehicle, etc.";
CM_ SG_ 2650544894 WPID "Number of route, waypoint, event, mark, etc.";
CM_ SG_ 2650544894 reserved "Number of route, waypoint, event, mark, etc.";
CM_ SG_ 2650544894 DatabaseID "Number of route, waypoint, event, mark, etc.";
CM_ SG_ 2650544894 NumberOfValidWPsInWPList "Number of route, waypoint, event, mark, etc.";
CM_ SG_ 2650544894 nItems "Number of route, waypoint, event, mark, etc.";
CM_ SG_ 2650544894 StartWPID "Number of route, waypoint, event, mark, etc.";
CM_ BO_ 2650544382 "Complex Rq of this PGN should return supplementary Comments attached to Databases in navigation Device.

Databases without a Comment shall not be included in this PGN.

reply should use same transfer Protcl as Rq.
ISO Rq for this PGN shall return 059";
CM_ SG_ 2650544382 DatabaseID "Number of route, waypoint, event, mark, etc.";
CM_ SG_ 2650544382 NumberOfDatabasesWithComments "Number of route, waypoint, event, mark, etc.";
CM_ SG_ 2650544382 nItems "Number of route, waypoint, event, mark, etc.";
CM_ SG_ 2650544382 StartDatabaseID "Number of route, waypoint, event, mark, etc.";
CM_ BO_ 2314276350 "Rudderder Cmd in direction angle with current rudder angle reading.Directionder field is for non-follow-up rudderders and Angleder field is for follow-up rudderders.When used as a Cmd,Directionder field and Angleder field shall never containder values at ";
CM_ SG_ 2314276350 Pos "Rudder angle where positive values are starboard and negative values are port";
CM_ SG_ 2314276350 Angleder "Rudder angle where positive values are starboard and negative values are port";
CM_ SG_ 2314276350 Directionder "MSB/LSB: 
000 = No Order, 
001 = Move to starboard, 
010 = Move to port.";
CM_ SG_ 2314276350 RudderInstance "For Engs:
0 = Instance 0;          0 = Single Eng Dual Eng Port
1 = Instance 1;          1 = Dual Eng StarBoard  
                                  (for Multiple Engs,Instances will start 
        thru                            from Bow,Port(0)to Ste";
CM_ BO_ 2650543614 "Complex Rq of this PGN will return XTE Limit and/or Navigation Method specific to individual legs of a Route.

Database ID and Route ID shall be specified in Rq/reply.

parameters apply to one leg after Waypoint identified with RPS# in Forward Directi";
CM_ SG_ 2650543614 NavMethodInLegAfterWP "0 = Great Circle calculations, 
1 = Rhumb Line calculations, 
2 = Error, 
3 = Null";
CM_ SG_ 2650543614 XTELimitInLegAfterWP "A commanded distance like radius order, off-track limit, etc.";
CM_ SG_ 2650543614 RPS "Number of route, waypoint, event, mark, etc.";
CM_ SG_ 2650543614 RouteID "Number of route, waypoint, event, mark, etc.";
CM_ SG_ 2650543614 DatabaseID "Number of route, waypoint, event, mark, etc.";
CM_ SG_ 2650543614 NmbrOfWypntsWthASpcfcXTELmtNvMth "Number of route, waypoint, event, mark, etc.";
CM_ SG_ 2650543614 nItems "Number of route, waypoint, event, mark, etc.";
CM_ SG_ 2650543614 StartRPS "Number of route, waypoint, event, mark, etc.";
CM_ BO_ 2650542846 "Complex Rq for this PGN should return attributes of a Route WP-List.

WARNING:Route Track may not be defined by Waypoint Poss only:Navigation Method(GC/RL)and Radius of Turn at each Waypoint are optional additional parameters defining Track.
PGN 130066";
CM_ SG_ 2650542846 Route_WPListName "Name of place, route, waypoint, destination, vessel, vehicle, etc.";
CM_ SG_ 2650542846 RouteID "Number of route, waypoint, event, mark, etc.";
CM_ SG_ 2650542846 DatabaseID "Number of route, waypoint, event, mark, etc.";
CM_ BO_ 2650543870 "Complex Rq of this PGN should return supplementary Comments attached to Waypoints in a Route a WP-List.

Waypoints without a Commment shall not be included in this PGN.

If Route ID is set to 65535(NA),Comments will be for Waypoints in WP-List.
Datab";
CM_ SG_ 2650543870 WPID_RPS "Number of route, waypoint, event, mark, etc.";
CM_ SG_ 2650543870 RouteID "Number of route, waypoint, event, mark, etc.";
CM_ SG_ 2650543870 DatabaseID "Number of route, waypoint, event, mark, etc.";
CM_ SG_ 2650543870 NumberOfWPsWithComments "Number of route, waypoint, event, mark, etc.";
CM_ SG_ 2650543870 nItems "Number of route, waypoint, event, mark, etc.";
CM_ SG_ 2650543870 StartID "Number of route, waypoint, event, mark, etc.";
CM_ BO_ 2650543102 "Complex Rq of this PGN should return Waypoints belonging to a Route.

WARNING:Route Track may not be defined by Waypoint Poss only:Navigation Method(GC/RL)and Radius of Turn at each Waypoint are optional additional parameters defining Track.
PGN 130066";
CM_ SG_ 2650543102 WPName "Name of place, route, waypoint, destination, vessel, vehicle, etc.";
CM_ SG_ 2650543102 WPID "Number of route, waypoint, event, mark, etc.";
CM_ SG_ 2650543102 RouteID "Number of route, waypoint, event, mark, etc.";
CM_ SG_ 2650543102 DatabaseID "Number of route, waypoint, event, mark, etc.";
CM_ SG_ 2650543102 NumberOfWPsInRoute "Number of route, waypoint, event, mark, etc.";
CM_ SG_ 2650543102 nItems "Number of route, waypoint, event, mark, etc.";
CM_ SG_ 2650543102 StartRPS "Number of route, waypoint, event, mark, etc.";
CM_ BO_ 2650543358 "Complex Rq of this PGN should return Waypoints belonging to a Route.

WARNING:Route Track may not be defined by Waypoint Poss only:Navigation Method(GC/RL)and Radius of Turn at each Waypoint are optional additional parameters defining Track.
PGN 130066";
CM_ SG_ 2650543358 WPName "Name of place, route, waypoint, destination, vessel, vehicle, etc.";
CM_ SG_ 2650543358 WPID "Number of route, waypoint, event, mark, etc.";
CM_ SG_ 2650543358 RouteID "Number of route, waypoint, event, mark, etc.";
CM_ SG_ 2650543358 DatabaseID "Number of route, waypoint, event, mark, etc.";
CM_ SG_ 2650543358 NumberOfWPsInRoute "Number of route, waypoint, event, mark, etc.";
CM_ SG_ 2650543358 nItems "Number of route, waypoint, event, mark, etc.";
CM_ SG_ 2650543358 StartRPS "Number of route, waypoint, event, mark, etc.";
CM_ BO_ 2650542590 "Complex Rq for this PGN should return a list of Routes in a Database.

A Database may contain Routes identified with Route ID in range 0-65532.There may be empty gaps(Route ID does not represent a valid/existent Route)anywhere in this range.This PGN sha";
CM_ SG_ 2650542590 RouteName "Name of place, route, waypoint, destination, vessel, vehicle, etc.";
CM_ SG_ 2650542590 RouteID "Number of route, waypoint, event, mark, etc.";
CM_ SG_ 2650542590 DatabaseID "Number of route, waypoint, event, mark, etc.";
CM_ SG_ 2650542590 NmbrOfRoutesAvailableInDatabase "Number of route, waypoint, event, mark, etc.";
CM_ SG_ 2650542590 nItems "Number of route, waypoint, event, mark, etc.";
CM_ SG_ 2650542590 StartRouteID "Number of route, waypoint, event, mark, etc.";
CM_ BO_ 2650544126 "Complex Rq of this PGN should return supplementary Comments attached to Routes.

Database ID shall be specified in Rq/reply.
Routes without a comment shall not be included in this PGN.

reply should use same transfer Protcl as Rq.
ISO Rq for this PG";
CM_ SG_ 2650544126 RouteID "Number of route, waypoint, event, mark, etc.";
CM_ SG_ 2650544126 DatabaseID "Number of route, waypoint, event, mark, etc.";
CM_ SG_ 2650544126 NumberOfRoutesWithComments "Number of route, waypoint, event, mark, etc.";
CM_ SG_ 2650544126 nItems "Number of route, waypoint, event, mark, etc.";
CM_ SG_ 2650544126 StartRouteID "Number of route, waypoint, event, mark, etc.";
CM_ BO_ 2650544638 "Complex Rq of this PGN should return Radius of Turn at specific Waypoints of a Route.

For a complete description of Route and WP PGNs,see App note in Appendix D.Radius of Turn is described in Appendix D.5.15.6.

Database ID and Route ID shall be spec";
CM_ SG_ 2650544638 RadiusOfTurn "A commanded distance like radius order, off-track limit, etc.";
CM_ SG_ 2650544638 RPS "Number of route, waypoint, event, mark, etc.";
CM_ SG_ 2650544638 RouteID "Number of route, waypoint, event, mark, etc.";
CM_ SG_ 2650544638 DatabaseID "Number of route, waypoint, event, mark, etc.";
CM_ SG_ 2650544638 NmbrOfWypntsWthASpcfcRdusOfTurn "Number of route, waypoint, event, mark, etc.";
CM_ SG_ 2650544638 nItems "Number of route, waypoint, event, mark, etc.";
CM_ SG_ 2650544638 StartRPS "Number of route, waypoint, event, mark, etc.";
CM_ BO_ 2650542334 "Complex Rq for this PGN should return a list of Databases in which a navigation Deviceganizes its Routes and WPs.

A Database may contain one WP-List and multiple Routes.

A device need not support concept of multiple Databases.support of this PGN is ";
CM_ SG_ 2650542334 DatabaseName "Name of place, route, waypoint, destination, vessel, vehicle, etc.";
CM_ SG_ 2650542334 DatabaseID "Number of route, waypoint, event, mark, etc.";
CM_ SG_ 2650542334 NumberOfDatabasesAvailable "Number of route, waypoint, event, mark, etc.";
CM_ SG_ 2650542334 nItems "Number of route, waypoint, event, mark, etc.";
CM_ SG_ 2650542334 StartDatabaseID "Number of route, waypoint, event, mark, etc.";
CM_ BO_ 2314277886 "Rate of Turn is the rate of change of the Heading.

Heading is defined as the direction of the vertical projection of the fore-and-aft line of the ship onto the horizontal plane.";
CM_ SG_ 2314277886 RateOfTurn "+ = Bow turning to starboard, 1 deg/min = .00029 rad/sec";
CM_ SG_ 2314277886 SequenceID_ "An upward counting number used to tie related information together between different PGNs.For example,SID would be used to tie together COG,SOG and RAIM values to a given Pos.255=no valid Pos fix to tie it to.Range 0 to 250 for valid Pos fixes.";
CM_ BO_ 2382039038 "This PGN provides status and control for a Radiotelephone, connected to a NMEA 2000 network.

The Radiotelephone will transmit and receive status along with remote control and repeater products.";
CM_ SG_ 2382039038 RadioChannel "MF/HF telephone channels to have first digit 3 followed by ITU channel numbers with leading zeros as required.MF/HF teletype channels to have first digit 4; second and third digit give frequency bands; and fourth to sixth digits ITU channel numbers; each ";
CM_ BO_ 2314732542 "The'Pos Delta,High Precision Rapid Update'Parameter Group is intended for Apps where very high precision and very fast update rates are needed for Pos data.This PG can provide delta Pos changes down to 1 millimeter with a delta time period accurate to 5 m";
CM_ SG_ 2314732542 SequenceID_ "An upward counting number used to tie related information together between different PGNs.For example,SID would be used to tie together COG,SOG and RAIM values to a given Pos.255=no valid Pos fix to tie it to.Range 0 to 250 for valid Pos fixes.";
CM_ BO_ 2582648062 "Provides product information onto network that could be important for determining quality of data coming from this product.Each field must be provided if data is typically available from such a product.At Min NMEA 2000 Version,NMEA Manufacturer’s Product ";
CM_ SG_ 2582648062 ManufacturersModelID "Length specified by PGN field definition.";
CM_ SG_ 2582648062 NMEAManufacturersProductCode "Number of route, waypoint, event, mark, etc.";
CM_ SG_ 2582648062 NMEA2000DatabaseVersion "Number of route, waypoint, event, mark, etc.";
CM_ BO_ 2314732030 "This PGN provides latitude and longitude referenced to WGS84.Being defined as single frame Msg,as opposed to other PGNs that include latitude and longitude and are defined as fast multi-packet,this PGN lends itself to being transmitted more frequently wit";
CM_ BO_ 2582576894 "Transmit/Receive PGN List Group type of function is defined by first field.Msg will be a Transmit Receive PGN List group function.These are defined as follows:

Transmit PGN List group function:This Msg contains a list of Transmitted PGNs that are suppo";
CM_ SG_ 2582576894 VrblNmbrOfFldsFldNmber2Repeated2 "24-bit Parameter Group Number (PGN) expressed in binary, LSB is transmitted first";
CM_ SG_ 2582576894 FirstPGNSupported2 "24-bit Parameter Group Number (PGN) expressed in binary, LSB is transmitted first";
CM_ SG_ 2582576894 VrblNmbrOfFldsFldNmber2Repeated "24-bit Parameter Group Number (PGN) expressed in binary, LSB is transmitted first";
CM_ SG_ 2582576894 FirstPGNSupported "24-bit Parameter Group Number (PGN) expressed in binary, LSB is transmitted first";
CM_ SG_ 2582576894 GrpFnctnTrnsmtAndReceivePGNList "0 = Transmit PGN List Message, 
1 = Receive PGN List Message";
CM_ BO_ 2583234046 "This PGN shall return Route and WP data ahead in Active Route.
It can be Rqed may be transmitted without a Rq,typically at each Waypoint advance.
 
When navigating Route in Forward direction,Waypoints shall be included inder of increasing RPS#s.When na";
CM_ SG_ 2583234046 RouteName "Name of place, route, waypoint, destination, vessel, vehicle, etc.";
CM_ SG_ 2583234046 SpplmntaryRoute_WPDataAvailable "MSB/LSB: 
00 = [No, Off, Disabled, Reset, '0'], 
01 = [Yes, On, Enabled, Set, '1'], 
10 = Error, 
11= [Unavailable, Unknown]";
CM_ SG_ 2583234046 NavigationDirectionInRoute "0=Forward, 
1=Reverse, 
2-5 Reserved, 
6= Error, 
7=Null (info not available)";
CM_ SG_ 2583234046 RouteID "Number of route, waypoint, event, mark, etc.";
CM_ SG_ 2583234046 DatabaseID "Number of route, waypoint, event, mark, etc.";
CM_ SG_ 2583234046 nItems "Number of route, waypoint, event, mark, etc.";
CM_ SG_ 2583234046 StartRPS "Number of route, waypoint, event, mark, etc.";
CM_ BO_ 2381907198 "This PGN provides essential navigation data for following a route.

Transmissions will originate from products that can create and manage routes using waypoints.  This information is intended for navigational repeaters.";
CM_ SG_ 2381907198 WaypointClosingVelocity "Positive values represent ahead or starboard transverse speed and negative values represent astern or port transverse speed.";
CM_ SG_ 2381907198 DestinationWaypointNumber "Number of route, waypoint, event, mark, etc.";
CM_ SG_ 2381907198 OriginWaypointNumber "Number of route, waypoint, event, mark, etc.";
CM_ SG_ 2381907198 BearingPosToDestinationWaypoint "The horizontal direction of one terrestrial point from another, expressed as the angular distance from a reference direction, measured from 000 at the reference direction clockwise through 359 degrees.";
CM_ SG_ 2381907198 BaringiginToDestinationWaypoint "The horizontal direction of one terrestrial point from another, expressed as the angular distance from a reference direction, measured from 000 at the reference direction clockwise through 359 degrees.";
CM_ SG_ 2381907198 ETADate "Days since January 1, 1970,   Date is relative to UTC Time.";
CM_ SG_ 2381907198 ETATime "24 hour clock, 0 =  midnight,  time is in UTC";
CM_ SG_ 2381907198 CalculationType "0 = Great Circle calculations, 
1 = Rhumb Line calculations, 
2 = Error, 
3 = Null";
CM_ SG_ 2381907198 ArrivalCircleEntered "MSB/LSB: 
00 = [No, Off, Disabled, Reset, '0'], 
01 = [Yes, On, Enabled, Set, '1'], 
10 = Error, 
11= [Unavailable, Unknown]";
CM_ SG_ 2381907198 PerpendicularCrossed "MSB/LSB: 
00 = [No, Off, Disabled, Reset, '0'], 
01 = [Yes, On, Enabled, Set, '1'], 
10 = Error, 
11= [Unavailable, Unknown]";
CM_ SG_ 2381907198 Course_BearingRef "0 = True, 
1 = Magnetic, 
2 = Error, 
3 = Null";
CM_ SG_ 2381907198 SID "An upward counting number used to tie related information together between different PGNs.For example,SID would be used to tie together COG,SOG and RAIM values to a given Pos.255=no valid Pos fix to tie it to.Range 0 to 250 for valid Pos fixes.";
CM_ BO_ 2381184766 "Rq/Cmd/Acknowledge Group type of function is defined by first field.Msg will be a Rq,Cmd,or Acknowledge Group Function.These are defined as follows:

Rq Group Function:This Msg Rqs Trans of a specific set of data in a Parameter Group by setting variable";
CM_ SG_ 2381184766 NumberOfRqedCmdedParameters "Numeric count, event counter, sequence counter";
CM_ SG_ 2381184766 VrblNmbrOfFldsFldNmber6Repeated3 "0x0 = No Error/Acknowledge; 
0x1 = Invalid request or command parameter field; 
0x2 = Temporarily unable to comply; 
0x3 = Request or command parameter out-of-range; 
0x4 = Access denied; 
0x5 = Request or Command Group Function not supported";
CM_ SG_ 2381184766 FirstParameterErrorCode "0x0 = No Error/Acknowledge; 
0x1 = Invalid request or command parameter field; 
0x2 = Temporarily unable to comply; 
0x3 = Request or command parameter out-of-range; 
0x4 = Access denied; 
0x5 = Request or Command Group Function not supported";
CM_ SG_ 2381184766 TransInterval_PriorityErrorCode "0x0 = No Error/Acknowledge, 
0x1 = Transmit Interval /Priority not supported,
0x2 = Transmit interval is less than measurement/calculation interval, 
0x3 = Access denied.
0x4 = Request is not supported.";
CM_ SG_ 2381184766 RqedCmdedPGNBeingAcknowledged "24-bit Parameter Group Number (PGN) expressed in binary, LSB is transmitted first";
CM_ SG_ 2381184766 PGNErrorCode "0x0 = No Error/Acknowledge, 
0x1 = PGN not supported, 
0x2 = PGN temporarily not available, 
0x3 = Access denied,
0x4 = Request is not supported.";
CM_ SG_ 2381184766 VrblNmbrOfFldsFldNmber6Repeated2 "Number of route, waypoint, event, mark, etc.";
CM_ SG_ 2381184766 FeldNumberOfFirstCmdedParameter "Number of route, waypoint, event, mark, etc.";
CM_ SG_ 2381184766 NmbrOfPrsOfCmddPrmetersToFollow "Numeric count, event counter, sequence counter";
CM_ SG_ 2381184766 PrioritySetting "0x0 to 0x7 = commanded priority value; 
0x8 = do not change priority; 
0x9 = return priority to default; 
0xA to 0xF = reserved";
CM_ SG_ 2381184766 CmdedPGN "24-bit Parameter Group Number (PGN) expressed in binary, LSB is transmitted first";
CM_ SG_ 2381184766 VrblNmbrOfFldsFldNmber6Repeated "Number of route, waypoint, event, mark, etc.";
CM_ SG_ 2381184766 FieldNumberOfFirstRqedParameter "Number of route, waypoint, event, mark, etc.";
CM_ SG_ 2381184766 NmbrOfPrsOfRqParametersToFollow "Numeric count, event counter, sequence counter";
CM_ SG_ 2381184766 TransIntervalOffset "Offset in transmit time from time of request command: 0x0 = transmit immediately, 0xFFFF = Do not change offset.";
CM_ SG_ 2381184766 TransInterval "Time interval between data transmissions: 0x0 = Turn-off transmission  0xFFFF FFFF = Do not change interval";
CM_ SG_ 2381184766 RqedPGN "24-bit Parameter Group Number (PGN) expressed in binary, LSB is transmitted first";
CM_ SG_ 2381184766 GroupFunctionRq_Cmd_Acknowledge "0 = Request Message, 
1 = Command Message, 
2 = Acknowledge Message";
CM_ BO_ 2583500030 "Moored buoy measurement data including station location and numeric identifier.";
CM_ SG_ 2583500030 StationIDString "Name of place, route, waypoint, destination, vessel, vehicle, etc.";
CM_ SG_ 2583500030 PressTendencyRate "Positive value indicates Rising, Negative value indicates Falling.";
CM_ SG_ 2583500030 DominateWavePeriod "Average wave period of all waves during a 20-minute period. Dominant wave period is the period with the maximum wave energy.  Note: See DD50 note.";
CM_ SG_ 2583500030 WaveHeight "Wave height is calculated as highest one-third of all of wave heights during a 20-minute sampling period.Note:Accelerometers inclinometers on board buoys measure heave acceleration vertical displacement of buoy hull during wave acquisition time.A Fast Fou";
CM_ SG_ 2583500030 WindGusts "Peak wind gust speed.  Sustained wind over an interval of 5 seconds.";
CM_ SG_ 2583500030 WindReference "0x00 = True (referenced to North)
0x01 = Magnetic
0x02 = Apparent
0x03 = True (boat referenced)
0x04 = Reserved
0x05 = Reserved
0x06 = Error
0x07 = Null";
CM_ SG_ 2583500030 MeasurementTime "24 hour clock, 0 =  midnight,  time is in UTC";
CM_ SG_ 2583500030 MeasurementDate "Days since January 1, 1970,   Date is relative to UTC Time.";
CM_ SG_ 2583500030 Mode "Range Residual used in position calculation or range residuals were calculated after the position.  
0=range residuals were used to calculate data; 
1=range residuals were calculated after the position., 
2=Error, 
3=Null";
CM_ BO_ 2583499774 "Meteorological station measurement data including station location, numeric identifier, and name.";
CM_ SG_ 2583499774 StationIDString "Name of place, route, waypoint, destination, vessel, vehicle, etc.";
CM_ SG_ 2583499774 WindGusts "Peak wind gust speed.  Sustained wind over an interval of 5 seconds.";
CM_ SG_ 2583499774 WindReference "0x00 = True (referenced to North)
0x01 = Magnetic
0x02 = Apparent
0x03 = True (boat referenced)
0x04 = Reserved
0x05 = Reserved
0x06 = Error
0x07 = Null";
CM_ SG_ 2583499774 MeasurementTime "24 hour clock, 0 =  midnight,  time is in UTC";
CM_ SG_ 2583499774 MeasurementDate "Days since January 1, 1970,   Date is relative to UTC Time.";
CM_ SG_ 2583499774 Mode "Range Residual used in position calculation or range residuals were calculated after the position.  
0=range residuals were used to calculate data; 
1=range residuals were calculated after the position., 
2=Error, 
3=Null";
CM_ BO_ 2649823998 "Msg for transmitting variation.Msg contains a sequence number to allow synchronization of other Msgs such as Heading Course over Ground.quality of service and age of service are provided to enable recipients to determine an appropriate level of service if";
CM_ SG_ 2649823998 Variation "Positive values are Easterly and negative values are Westerly.";
CM_ SG_ 2649823998 AgeOfService "Days since January 1, 1970,   Date is relative to UTC Time.";
CM_ SG_ 2649823998 VariationSource "0x00 = Manual Entry,
0x01 = Automatic-Chart,
0x02 = Automatic Table,
0x03 = Automatic Calculation,
0x04 = WMM 2000,
0x05 = WMM 2005,
0x06 = WMM 2010,
0x07 = WMM 2015,
0x08 = WMM 2020,
0x09 = Reserve,
 thru
0x3E = Reserve,
0x3F = Data Not Avail";
CM_ SG_ 2649823998 SequenceID_ "An upward counting number used to tie related information together between different PGNs.For example,SID would be used to tie together COG,SOG and RAIM values to a given Pos.255=no valid Pos fix to tie it to.Range 0 to 250 for valid Pos fixes.";
CM_ BO_ 2382103806 "This provides Time Difference(TD)lines of Pos of Loran-C signals relative to a single Group Repetition Interval.

Field #1,Group Repetition Interval(GRI),is identified as a Rq parameter for this Parameter Group.All providers of this PGN shall accept and";
CM_ SG_ 2382103806 Mode "Range Residual used in position calculation or range residuals were calculated after the position.  
0=range residuals were used to calculate data; 
1=range residuals were calculated after the position., 
2=Error, 
3=Null";
CM_ SG_ 2382103806 StationStatusZ "MSB: to LSB:
xxx1 = Station in use, 
xx1x = Low SNR, 
x1xx = Cycle error, 
1xxx = Blink
            where x = don't care";
CM_ SG_ 2382103806 StationStatusY "MSB: to LSB:
xxx1 = Station in use, 
xx1x = Low SNR, 
x1xx = Cycle error, 
1xxx = Blink
            where x = don't care";
CM_ SG_ 2382103806 StationStatusX "MSB: to LSB:
xxx1 = Station in use, 
xx1x = Low SNR, 
x1xx = Cycle error, 
1xxx = Blink
            where x = don't care";
CM_ SG_ 2382103806 StationStatusW "MSB: to LSB:
xxx1 = Station in use, 
xx1x = Low SNR, 
x1xx = Cycle error, 
1xxx = Blink
            where x = don't care";
CM_ SG_ 2382103806 StationStatusV "MSB: to LSB:
xxx1 = Station in use, 
xx1x = Low SNR, 
x1xx = Cycle error, 
1xxx = Blink
            where x = don't care";
CM_ SG_ 2382103806 StationStatusMaster "MSB: to LSB:
xxx1 = Station in use, 
xx1x = Low SNR, 
x1xx = Cycle error, 
1xxx = Blink
            where x = don't care";
CM_ SG_ 2382103806 ZSecondTD "Loran-C Time difference (TD) in nano-sec.  The arrival time of a Loran-C secondary station signal minus the arrival time of the master station signal.";
CM_ SG_ 2382103806 YSecondTD "Loran-C Time difference (TD) in nano-sec.  The arrival time of a Loran-C secondary station signal minus the arrival time of the master station signal.";
CM_ SG_ 2382103806 XSecondTD "Loran-C Time difference (TD) in nano-sec.  The arrival time of a Loran-C secondary station signal minus the arrival time of the master station signal.";
CM_ SG_ 2382103806 WSecondTD "Loran-C Time difference (TD) in nano-sec.  The arrival time of a Loran-C secondary station signal minus the arrival time of the master station signal.";
CM_ SG_ 2382103806 VSecondTD "Loran-C Time difference (TD) in nano-sec.  The arrival time of a Loran-C secondary station signal minus the arrival time of the master station signal.";
CM_ SG_ 2382103806 MasterRange "The actual propagation time of a Loran-C signal from the station to a receiver in nano-sec.";
CM_ SG_ 2382103806 GroupRepetitionInterval "Group Repetition Interval (GRI) in nano-sec.  Often cited in units of 10 micro-sec. (i.e., 9960 = 99,600,000 ns)";
CM_ BO_ 2382104318 "SNR,ECD,and ASF values of Loran-C signals

Field #1,Group Repetition Interval(GRI),is identified as a Rq parameter for this Parameter Group.All providers of this PGN shall accept and process Rqs based upon Rqed value of Field #1.A device receiving an IS";
CM_ SG_ 2382104318 StationIdentifier "1-character code for the Loran-C station: M = master, V, W, X, Y, Z";
CM_ SG_ 2382104318 GroupRepetitionInterval "Group Repetition Interval (GRI) in nano-sec.  Often cited in units of 10 micro-sec. (i.e., 9960 = 99,600,000 ns)";
CM_ BO_ 2382104062 "This provides Propagation times(Ranges)of Loran-C signals relative to a single Group Repetition Interval.

Field #1,Group Repetition Interval(GRI),is identified as a Rq parameter for this Parameter Group.All providers of this PGN shall accept and proces";
CM_ SG_ 2382104062 Mode "Range Residual used in position calculation or range residuals were calculated after the position.  
0=range residuals were used to calculate data; 
1=range residuals were calculated after the position., 
2=Error, 
3=Null";
CM_ SG_ 2382104062 StationStatusZ "MSB: to LSB:
xxx1 = Station in use, 
xx1x = Low SNR, 
x1xx = Cycle error, 
1xxx = Blink
            where x = don't care";
CM_ SG_ 2382104062 StationStatusY "MSB: to LSB:
xxx1 = Station in use, 
xx1x = Low SNR, 
x1xx = Cycle error, 
1xxx = Blink
            where x = don't care";
CM_ SG_ 2382104062 StationStatusX "MSB: to LSB:
xxx1 = Station in use, 
xx1x = Low SNR, 
x1xx = Cycle error, 
1xxx = Blink
            where x = don't care";
CM_ SG_ 2382104062 StationStatusW "MSB: to LSB:
xxx1 = Station in use, 
xx1x = Low SNR, 
x1xx = Cycle error, 
1xxx = Blink
            where x = don't care";
CM_ SG_ 2382104062 StationStatusV "MSB: to LSB:
xxx1 = Station in use, 
xx1x = Low SNR, 
x1xx = Cycle error, 
1xxx = Blink
            where x = don't care";
CM_ SG_ 2382104062 StationStatusMaster "MSB: to LSB:
xxx1 = Station in use, 
xx1x = Low SNR, 
x1xx = Cycle error, 
1xxx = Blink
            where x = don't care";
CM_ SG_ 2382104062 ZSecondRange "The actual propagation time of a Loran-C signal from the station to a receiver in nano-sec.";
CM_ SG_ 2382104062 YSecondRange "The actual propagation time of a Loran-C signal from the station to a receiver in nano-sec.";
CM_ SG_ 2382104062 XSecondRange "The actual propagation time of a Loran-C signal from the station to a receiver in nano-sec.";
CM_ SG_ 2382104062 WSecondRange "The actual propagation time of a Loran-C signal from the station to a receiver in nano-sec.";
CM_ SG_ 2382104062 VSecondRange "The actual propagation time of a Loran-C signal from the station to a receiver in nano-sec.";
CM_ SG_ 2382104062 MasterRange "The actual propagation time of a Loran-C signal from the station to a receiver in nano-sec.";
CM_ SG_ 2382104062 GroupRepetitionInterval "Group Repetition Interval (GRI) in nano-sec.  Often cited in units of 10 micro-sec. (i.e., 9960 = 99,600,000 ns)";
CM_ BO_ 2314274302 "Sends Cmds to,and receives data from,heading Ctrl systems.Allows for navigational(remote)Ctrl of a heading Ctrl system and direct rudder Ctrl.When used as a Cmd,Cmded Rudder Direction field and Cmded Rudder Angle should never containder values at same tim";
CM_ SG_ 2314274302 VesselHeading "The horizontal direction in which a ship actually points or heads at any instant, expressed in angular units from a reference direction, usually from 000 at the reference direction clockwise through 359 degrees.";
CM_ SG_ 2314274302 OffTrackLimit "A commanded distance like radius order, off-track limit, etc.";
CM_ SG_ 2314274302 RateOfTurnder "+ = Bow turning to starboard, 1 deg/min = .00029 rad/sec";
CM_ SG_ 2314274302 RadiusOfTurnder "A commanded distance like radius order, off-track limit, etc.";
CM_ SG_ 2314274302 Track "intended desired horizontal direction of travel with respect to earth.track expressed in degrees of compass may differ from course due to allowances made in course for such factors as sea and weather conditions inder to achieve desired track.This field re";
CM_ SG_ 2314274302 HeadingToSteer "The horizontal direction in which a vessel is steered or intended to be steered, expressed as angular distance 000 north, clockwise through 359 degrees.  Not to be confused with Course-over-ground, Track, or Heading.";
CM_ SG_ 2314274302 CmdedRudderAngle "Rudder angle where positive values are starboard and negative values are port";
CM_ SG_ 2314274302 CmdedRudderDirection "MSB/LSB: 
000 = No Order, 
001 = Move to starboard, 
010 = Move to port.";
CM_ SG_ 2314274302 HeadingReference "0 = True, 
1 = Magnetic, 
2 = Error, 
3 = Null";
CM_ SG_ 2314274302 TurnMode "MSB/LSB:
000 = Rudder Limit Ctrlled,
001 = turn rate Ctrlled,
010 = radius Ctrlled.
Definitions:Rudder – An operator set rudder limit determines Max turning capability available,in which case system outputs rudderders up to and limited by rudder limit";
CM_ SG_ 2314274302 SteerMode "MSB/LSB:
000 = Main Steer,
001 = Non-Follow-up Device,
010 = Follow-up Device,
011 = Heading Ctrl Standalone,
100 = Heading Ctrl,
101 = Track Ctrl.
Definitions:Main Steer/Outside System – main Steer system is in use.
Non-Follow-up Device – system ";
CM_ SG_ 2314274302 Override "1 = Yes,0 = No.Yes means a temporary interruption of selected Steer mode.As long as this field is Yes,Steer Mode and Turn Mode shall be ignored by heading/track Ctrl and its computing parts shall operate as if manual Steer was selected.";
CM_ SG_ 2314274302 OffTrackLimitExceeded "MSB/LSB: 
00 = [No, Off, Disabled, Reset, '0'], 
01 = [Yes, On, Enabled, Set, '1'], 
10 = Error, 
11= [Unavailable, Unknown]";
CM_ SG_ 2314274302 OffHeadingLimitExceeded "MSB/LSB: 
00 = [No, Off, Disabled, Reset, '0'], 
01 = [Yes, On, Enabled, Set, '1'], 
10 = Error, 
11= [Unavailable, Unknown]";
CM_ SG_ 2314274302 RudderLimitExceeded "MSB/LSB: 
00 = [No, Off, Disabled, Reset, '0'], 
01 = [Yes, On, Enabled, Set, '1'], 
10 = Error, 
11= [Unavailable, Unknown]";
CM_ BO_ 2583299582 "This PGN provides a single Trans that contains relevant almanac data for GPS products.almanac contains satellite vehicle coursebital parameters.This information is not considered precise and is only valid for several months at a time.GPS products receive ";
CM_ SG_ 2583299582 ClockParameter2 "Clock Parameter 2.  Reference ICD-GPS-200 Table 20-VI for scaling factors and units.";
CM_ SG_ 2583299582 ClockParameter1 "Clock Parameter 1.  Reference ICD-GPS-200 Table 20-VI for scaling factors and units.";
CM_ SG_ 2583299582 MeanAnomaly "Mean anomaly.  Reference ICD-GPS-200 Table 20-VI for scaling factors and units.";
CM_ SG_ 2583299582 LongitudeOfAscensionNode "Longitude of ascension node.  Reference ICD-GPS-200 Table 20-VI for scaling factors and units.";
CM_ SG_ 2583299582 ArgumentOfPerigee "Argument of Perigee.  Reference ICD-GPS-200 Table 20-VI for scaling factors and units.";
CM_ SG_ 2583299582 RootOfSemimajorAxis "Root of semi-major axis.  Reference ICD-GPS-200 Table 20-VI for scaling factors and units.";
CM_ SG_ 2583299582 RateOfRightAscension "Rate of right ascension, OMEGADOT.  Reference ICD-GPS-200 Table 20-VI for scaling factors and units.";
CM_ SG_ 2583299582 InclinationAngle "Inclination angle.  Reference ICD-GPS-200 Table 20-VI for scaling factors and units.";
CM_ SG_ 2583299582 AlmanacReferenceTime "Almanac reference time.  Reference ICD-GPS-200 Table 20-VI for scaling factors and units.";
CM_ SG_ 2583299582 Eccentricity "Eccentricity, e.  Reference ICD-GPS-200 Table 20-VI for scaling factors and units.";
CM_ SG_ 2583299582 SVHealthBits "SV health, bits 17-24 of each almanac page.  Reference ICD-GPS-200 paragraph 20.3.3.5.1.3, Table 20-VII and Table 20-VIII";
CM_ SG_ 2583299582 GPSWeekNumber "GPS week number. Starting on 6 Jan., 1980.  The GPS week number roll over will not affect this value, i.e., it will continue to count up 1022, 1023, 1024, 1025.";
CM_ SG_ 2583299582 PRN "0 = value not used,
  1-32 = GPS,
33-64 = SBAS,Satellite,Based Augmentation System(ie WAAS)
65-96 = GLONASS.
For GLONASS,satellites are identified by 64+satellite slot number.slot numbers are 1 through 24 for full GLONASS constellation of 24 satellite";
CM_ BO_ 2583299326 "GNSS information on current satellites in view tagged by sequence ID.Information includes PRN,elevation,azimuth,and SNR.Field 4 defines number of satellites.Fields 5 thru 11 define satellite number and information.These fields sequentially repeated for ea";
CM_ SG_ 2583299326 PRNStatusN "0   = Not Tracked,
  1   = Tracked but not used in solution,
  2   = Used in solution without Diff corrections,
  3   = Diff Corrections available,
  4   = Tracked with Diff Corrections,
  5   = used with Diff Corrections,
6-13 =Reserved,
14    = E";
CM_ SG_ 2583299326 AzimuthN "Degrees clockwise relative to True North.";
CM_ SG_ 2583299326 ElevationN "Angle above or below the horizon. -90° to +90°; negative below the horizon";
CM_ SG_ 2583299326 PRNN "0 = value not used,
  1-32 = GPS,
33-64 = SBAS,Satellite,Based Augmentation System(ie WAAS)
65-96 = GLONASS.
For GLONASS,satellites are identified by 64+satellite slot number.slot numbers are 1 through 24 for full GLONASS constellation of 24 satellite";
CM_ SG_ 2583299326 PRNStatus1 "0   = Not Tracked,
  1   = Tracked but not used in solution,
  2   = Used in solution without Diff corrections,
  3   = Diff Corrections available,
  4   = Tracked with Diff Corrections,
  5   = used with Diff Corrections,
6-13 =Reserved,
14    = E";
CM_ SG_ 2583299326 Azimuth1 "Degrees clockwise relative to True North.";
CM_ SG_ 2583299326 Elevation1 "Angle above or below the horizon. -90° to +90°; negative below the horizon";
CM_ SG_ 2583299326 PRN1 "0 = value not used,
  1-32 = GPS,
33-64 = SBAS,Satellite,Based Augmentation System(ie WAAS)
65-96 = GLONASS.
For GLONASS,satellites are identified by 64+satellite slot number.slot numbers are 1 through 24 for full GLONASS constellation of 24 satellite";
CM_ SG_ 2583299326 NumberOfSVs_ "Numeric count, event counter, sequence counter";
CM_ SG_ 2583299326 SID "An upward counting number used to tie related information together between different PGNs.For example,SID would be used to tie together COG,SOG and RAIM values to a given Pos.255=no valid Pos fix to tie it to.Range 0 to 250 for valid Pos fixes.";
CM_ BO_ 2583300862 "This PGN is used to report the control parameters for a GNSS Receiver Autonomous Integrity Monitoring (RAIM) process.  The Command Group Function PGN 126208 provides the means to set these values over the network.";
CM_ SG_ 2583300862 RadialPosErrorMaxThreshold "Error distances expressed in meters.";
CM_ BO_ 2583300606 "This PGN is used to provide the output from a GNSS Receiver's Receiver Autonomous Integrity Monitoring (RAIM) process.  The Integrity field value is based upon the parameters set in PGN 130059 GNS RAIM Settings.";
CM_ SG_ 2583300606 SVIDOfMostLikelyFailedSat "0 = value not used,
  1-32 = GPS,
33-64 = SBAS,Satellite,Based Augmentation System(ie WAAS)
65-96 = GLONASS.
For GLONASS,satellites are identified by 64+satellite slot number.slot numbers are 1 through 24 for full GLONASS constellation of 24 satellite";
CM_ SG_ 2583300606 IntegrityFlag "0 = No Integrity checking,*
1 = Safe,
2 = Caution,
3 = Unsafe
  * means the receiver does not have this capability";
CM_ SG_ 2583300606 SequenceID_ "An upward counting number used to tie related information together between different PGNs.For example,SID would be used to tie together COG,SOG and RAIM values to a given Pos.255=no valid Pos fix to tie it to.Range 0 to 250 for valid Pos fixes.";
CM_ BO_ 2583299838 "GNSS pseudorange measurement noise statistics can be translated in the position domain in order to give statistical measures of the quality of the position solution. Intended for use with a Receiver Autonomous Integrity Monitoring (RAIM) application.";
CM_ SG_ 2583299838 STDOfAltError "Error distances expressed in meters.";
CM_ SG_ 2583299838 STDOfLonError "Error distances expressed in meters.";
CM_ SG_ 2583299838 STDOfLatError "Error distances expressed in meters.";
CM_ SG_ 2583299838 OrientationOfMajorAxis "Degrees clockwise relative to True North.";
CM_ SG_ 2583299838 STDOfMinorAxis "Error distances expressed in meters.";
CM_ SG_ 2583299838 STDOfMajorAxis "Error distances expressed in meters.";
CM_ SG_ 2583299838 RMSOfPosUncertainty "Error distances expressed in meters.";
CM_ SG_ 2583299838 SID "An upward counting number used to tie related information together between different PGNs.For example,SID would be used to tie together COG,SOG and RAIM values to a given Pos.255=no valid Pos fix to tie it to.Range 0 to 250 for valid Pos fixes.";
CM_ BO_ 2583301118 "This parameter group is used to support Receiver Autononmous Integrity Monitoring (RAIM).  Pseudorange measurement error statistics can be translated in the position domain in order to give statistical measures of the quality of the position solution.";
CM_ SG_ 2583301118 OrientationOfErrorEllipse "Degrees clockwise relative to True North.";
CM_ SG_ 2583301118 SequenceID_ "An upward counting number used to tie related information together between different PGNs.For example,SID would be used to tie together COG,SOG and RAIM values to a given Pos.255=no valid Pos fix to tie it to.Range 0 to 250 for valid Pos fixes.";
CM_ BO_ 2381841918 "This PGN conveys a comprehensive set of Global Navigation Satellite System (GNSS) parameters, including position information.  Equipment transmitting this PGN would typically also transmit PGN 129025 (Position – Rapid Update).";
CM_ SG_ 2381841918 AgeOfDGNSSReferenceStationN "Age of Differential corrections";
CM_ SG_ 2381841918 ReferenceStationIDN "Reference Station ID.  Reference Station number as provided by the Service Provider.[Reference document required]";
CM_ SG_ 2381841918 ReferenceStationTypeN "Reference Station Type. 
0x0=GPS; 
0x1=GLONASS; 
0x3 to 0xD=Reserved; 
0XE=Error; 
0XF=Null";
CM_ SG_ 2381841918 AgeOfDGNSSCorrections1_ "Age of Differential corrections";
CM_ SG_ 2381841918 ReferenceStationID1_ "Reference Station ID.  Reference Station number as provided by the Service Provider.[Reference document required]";
CM_ SG_ 2381841918 ReferenceStationType1 "Reference Station Type. 
0x0=GPS; 
0x1=GLONASS; 
0x3 to 0xD=Reserved; 
0XE=Error; 
0XF=Null";
CM_ SG_ 2381841918 NumberOfReferenceStations_ "Numeric count, event counter, sequence counter";
CM_ SG_ 2381841918 GeoidalSeparation_ "The difference between the earth ellipsoid and mean-sea-level (geoid) defined by the reference datum used in the position solution, '-' = mean-sea-level below ellipsoid.  Reference datum is defined in this packet.";
CM_ SG_ 2381841918 PDOP_ "Dilution of Precision(DOP)indicates contribution of satellite Config geometry to Posing error.A lower DOP value is preferred because less error is being introduced.Reported as components:HDOP(Horizontal),VDOP(Vertical),TDOP(Time).Min DOP value is 1.0(no e";
CM_ SG_ 2381841918 HDOP_ "Dilution of Precision(DOP)indicates contribution of satellite Config geometry to Posing error.A lower DOP value is preferred because less error is being introduced.Reported as components:HDOP(Horizontal),VDOP(Vertical),TDOP(Time).Min DOP value is 1.0(no e";
CM_ SG_ 2381841918 NumberOfSVs_ "Numeric count, event counter, sequence counter";
CM_ SG_ 2381841918 Integrity "0 = No Integrity checking,*
1 = Safe,
2 = Caution,
3 = Unsafe
  * means the receiver does not have this capability";
CM_ SG_ 2381841918 MethodGNSS "0 = no GPS,
1 = GNSS fix,
2 = DGNSS fix,
3 = Precise GNSS*,
4 = RTK Fixed Integer,
5 = RTK Float,
6 = Est(DR)mode,
7 = Manual Input,
8 = Simulate mode,
9-13 = Reserved,
14 = Error,
15 = Null.*Precise GNSS means no deliberate degradation(such as";
CM_ SG_ 2381841918 TypeOfSystem_ "0x00 = GPS
0x01 = GLONASS
0x02 = GPS+GLONASS
0x03 = GPS+SBAS(WAAS)
0x04 = GPS+SBAS+GLONASS
0x05 - 0x15 = Reserved for future combinations";
CM_ SG_ 2381841918 PosTime "24 hour clock, 0 =  midnight,  time is in UTC";
CM_ SG_ 2381841918 PosDate "Days since January 1, 1970,   Date is relative to UTC Time.";
CM_ SG_ 2381841918 SID "An upward counting number used to tie related information together between different PGNs.For example,SID would be used to tie together COG,SOG and RAIM values to a given Pos.255=no valid Pos fix to tie it to.Range 0 to 250 for valid Pos fixes.";
CM_ BO_ 2583301886 "GNSS common differential correction receiver parameter status.";
CM_ SG_ 2583301886 DiffOperationMode "0  = Manual, 
  1  = Auto Power, 
  2  = Auto Range, 
3-13 = Reserved, 
 14 = Error, 
 15 = No Selection";
CM_ SG_ 2583301886 DiffSource "0  = Auto Select,
  1 = Loran Communications 
  2  = MSK Beacon,
  3  = FM Subcarrier,
  4  = AIS(Automatic Identification System),
  5  = Other Ground-based Radio,
  6  = SBAS(Satellite Based Augmentation System,
  7  = Other Satellite,
8-13 = Re";
CM_ SG_ 2583301886 SerialInterfaceDetectionMode "This is the mode of operation for the correction receiver.  
0 = Auto bit rate set, 
1 = Manual bit rate set,  
2-5  = Reserved
6 = Error, 
7 = Null.";
CM_ SG_ 2583301886 SerialInterfaceBitRate "This is bit rate of correction receiver.
 0 = 25bps,
 1 = 50bps,
 2 = 100bps,
 3 = 200bps,
 4 = 300bps,
 5 = 500bps,
 6 = 1200bps,
 7 = 2400bps,
 8 = 4800bps,
 9 = 9600bps
10 = 19200bps,
11 = 38400bps,
12 = 57600bps,
13-29 = Reserved,
30 = ";
CM_ SG_ 2583301886 Frequency "This is the input frequency of the correction receiver.";
CM_ SG_ 2583301886 Channel "The channel number of the correction receiver.  If the receiver only has one beacon input channel, this value shall be 1; 0 is undefined.";
CM_ BO_ 2583302142 "GNSS differential correction receiver status tagged by sequence ID. Status information includes frequency, SNR, and use as a correction source.";
CM_ SG_ 2583302142 SatelliteServiceIDNo "Satellite Service ID number as provided by the Service Provider.[Reference document required]";
CM_ SG_ 2583302142 TimeSinceLastSatDiffSync "Age of Differential corrections";
CM_ SG_ 2583302142 DiffSource "0  = Auto Select,
  1 = Loran Communications 
  2  = MSK Beacon,
  3  = FM Subcarrier,
  4  = AIS(Automatic Identification System),
  5  = Other Ground-based Radio,
  6  = SBAS(Satellite Based Augmentation System,
  7  = Other Satellite,
8-13 = Re";
CM_ SG_ 2583302142 UsedAsCorrectionSource "MSB/LSB: 
00 = [No, Off, Disabled, Reset, '0'], 
01 = [Yes, On, Enabled, Set, '1'], 
10 = Error, 
11= [Unavailable, Unknown]";
CM_ SG_ 2583302142 DiffSignalDetectionMode "This is the mode of operation for the correction receiver.  
0 = Auto bit rate set, 
1 = Manual bit rate set,  
2-5  = Reserved
6 = Error, 
7 = Null.";
CM_ SG_ 2583302142 DiffSignalBitRate "This is bit rate of correction receiver.
 0 = 25bps,
 1 = 50bps,
 2 = 100bps,
 3 = 200bps,
 4 = 300bps,
 5 = 500bps,
 6 = 1200bps,
 7 = 2400bps,
 8 = 4800bps,
 9 = 9600bps
10 = 19200bps,
11 = 38400bps,
12 = 57600bps,
13-29 = Reserved,
30 = ";
CM_ SG_ 2583302142 StationID "Reference Station ID.  Reference Station number as provided by the Service Provider.[Reference document required]";
CM_ SG_ 2583302142 StationType "Reference Station Type. 
0x0=GPS; 
0x1=GLONASS; 
0x3 to 0xD=Reserved; 
0XE=Error; 
0XF=Null";
CM_ SG_ 2583302142 Frequency "This is the input frequency of the correction receiver.";
CM_ SG_ 2583302142 SignalStrength "This is the signal strength expressed in dB with respect to 1uV/m.";
CM_ SG_ 2583302142 Channel "The channel number of the correction receiver.  If the receiver only has one beacon input channel, this value shall be 1; 0 is undefined.";
CM_ SG_ 2583302142 SID "An upward counting number used to tie related information together between different PGNs.For example,SID would be used to tie together COG,SOG and RAIM values to a given Pos.255=no valid Pos fix to tie it to.Range 0 to 250 for valid Pos fixes.";
BA_DEF_ BO_  "GenMsgCycleTimeFast" INT 0 3600000;
BA_DEF_ BU_  "ISO11783IOPVersion" ENUM  "0","1","2","3","4";
BA_DEF_ BU_  "ISO11783PDDVersion" ENUM  "0","1","2","3";
BA_DEF_ SG_  "SigType" ENUM  "Default","Range","RangeSigned","ASCII","Discrete","Control","ReferencePGN","DTC","StringDelimiter","StringLength","StringLengthControl";
BA_DEF_ SG_  "GenSigStartValue" INT 0 10000;
BA_DEF_ SG_  "GenSigSendType" ENUM  "Cyclic","OnWrite","reserved","OnChange","reserved","reserved","reserved","NoSigSendType";
BA_DEF_ SG_  "GenSigILSupport" ENUM  "Yes","No";
BA_DEF_ SG_  "GenSigEVName" STRING ;
BA_DEF_ SG_  "SPN" INT 0 524287;
BA_DEF_ SG_  "DDI" INT 0 65535;
BA_DEF_ SG_  "SAEDocument" STRING ;
BA_DEF_ BO_  "GenMsgStartDelayTime" INT 0 100000;
BA_DEF_ BO_  "GenMsgILSupport" ENUM  "Yes","No";
BA_DEF_ BO_  "GenMsgRequestable" INT 0 1;
BA_DEF_ BO_  "GenMsgSendType" ENUM  "cyclic","reserved","cyclicIfActive","reserved","reserved","reserved","reserved","reserved","noMsgSendType";
BA_DEF_ BO_  "VFrameFormat" ENUM  "StandardCAN","ExtendedCAN","reserved","J1939PG";
BA_DEF_ BO_  "SingleFrame" INT 0 1;
BA_DEF_ BO_  "GenMsgCycleTime" INT 0 3600000;
BA_DEF_ BO_  "SAE_Document" STRING ;
BA_DEF_ BU_  "NmStationAddress" INT 0 255;
BA_DEF_ BU_  "NmJ1939IndustryGroup" INT 0 7;
BA_DEF_ BU_  "NmJ1939System" INT 0 127;
BA_DEF_ BU_  "NmJ1939Function" INT 0 255;
BA_DEF_ BU_  "NmJ1939FunctionInstance" INT 0 7;
BA_DEF_ BU_  "NmJ1939ECUInstance" INT 0 3;
BA_DEF_  "DatabaseVersion" STRING ;
BA_DEF_  "BusType" STRING ;
BA_DEF_  "ProtocolType" STRING ;
BA_DEF_  "SAE_J1939_75_SpecVersion" STRING ;
BA_DEF_  "SAE_J1939_21_SpecVersion" STRING ;
BA_DEF_  "SAE_J1939_73_SpecVersion" STRING ;
BA_DEF_  "SAE_J1939_71_SpecVersion" STRING ;
BA_DEF_ SG_  "SystemSignalLongSymbol" STRING ;
BA_DEF_DEF_  "GenMsgCycleTimeFast" 0;
BA_DEF_DEF_  "ISO11783IOPVersion" "3";
BA_DEF_DEF_  "ISO11783PDDVersion" "3";
BA_DEF_DEF_  "SigType" "Default";
BA_DEF_DEF_  "GenSigStartValue" 0;
BA_DEF_DEF_  "GenSigSendType" "NoSigSendType";
BA_DEF_DEF_  "GenSigILSupport" "Yes";
BA_DEF_DEF_  "GenSigEVName" "Env@Nodename_@Signame";
BA_DEF_DEF_  "SPN" 0;
BA_DEF_DEF_  "DDI" 0;
BA_DEF_DEF_  "SAEDocument" "";
BA_DEF_DEF_  "GenMsgStartDelayTime" 0;
BA_DEF_DEF_  "GenMsgILSupport" "Yes";
BA_DEF_DEF_  "GenMsgRequestable" 1;
BA_DEF_DEF_  "GenMsgSendType" "noMsgSendType";
BA_DEF_DEF_  "VFrameFormat" "J1939PG";
BA_DEF_DEF_  "SingleFrame" 1;
BA_DEF_DEF_  "GenMsgCycleTime" 0;
BA_DEF_DEF_  "SAE_Document" "";
BA_DEF_DEF_  "NmStationAddress" 254;
BA_DEF_DEF_  "NmJ1939IndustryGroup" 0;
BA_DEF_DEF_  "NmJ1939System" 0;
BA_DEF_DEF_  "NmJ1939Function" 0;
BA_DEF_DEF_  "NmJ1939FunctionInstance" 0;
BA_DEF_DEF_  "NmJ1939ECUInstance" 0;
BA_DEF_DEF_  "DatabaseVersion" "";
BA_DEF_DEF_  "BusType" "";
BA_DEF_DEF_  "ProtocolType" "";
BA_DEF_DEF_  "SAE_J1939_75_SpecVersion" "";
BA_DEF_DEF_  "SAE_J1939_21_SpecVersion" "";
BA_DEF_DEF_  "SAE_J1939_73_SpecVersion" "";
BA_DEF_DEF_  "SAE_J1939_71_SpecVersion" "";
BA_DEF_DEF_  "SystemSignalLongSymbol" "";
BA_ "DatabaseVersion" "7.5";
BA_ "BusType" "CAN";
BA_ "ProtocolType" "J1939";
BA_ "SAE_J1939_75_SpecVersion" "2005-10";
BA_ "SAE_J1939_21_SpecVersion" "2006-10";
BA_ "SAE_J1939_73_SpecVersion" "2010-10";
BA_ "SAE_J1939_71_SpecVersion" "2010-10";
BA_ "NmStationAddress" BU_ Turbocharger 2;
BA_ "NmJ1939Function" BU_ Turbocharger 133;
BA_ "NmStationAddress" BU_ OnBoardDataLogger 251;
BA_ "NmJ1939Function" BU_ OnBoardDataLogger 130;
BA_ "NmStationAddress" BU_ OffBoardDiagnosticTool2 250;
BA_ "NmJ1939Function" BU_ OffBoardDiagnosticTool2 129;
BA_ "NmJ1939FunctionInstance" BU_ OffBoardDiagnosticTool2 1;
BA_ "NmStationAddress" BU_ OffBoardDiagnosticTool1 249;
BA_ "NmJ1939Function" BU_ OffBoardDiagnosticTool1 129;
BA_ "NmStationAddress" BU_ FileServer 248;
BA_ "NmJ1939Function" BU_ FileServer 61;
BA_ "NmStationAddress" BU_ ParkingBrakeController 80;
BA_ "NmJ1939Function" BU_ ParkingBrakeController 9;
BA_ "NmStationAddress" BU_ SeatControl2 79;
BA_ "NmJ1939Function" BU_ SeatControl2 40;
BA_ "NmStationAddress" BU_ FanDriveController 78;
BA_ "NmJ1939Function" BU_ FanDriveController 58;
BA_ "NmStationAddress" BU_ SteeringColumnUnit 77;
BA_ "NmJ1939Function" BU_ SteeringColumnUnit 57;
BA_ "NmStationAddress" BU_ CommunicationUnitRadio 76;
BA_ "NmJ1939Function" BU_ CommunicationUnitRadio 56;
BA_ "NmStationAddress" BU_ CommunicationUnitSatellite 75;
BA_ "NmJ1939Function" BU_ CommunicationUnitSatellite 55;
BA_ "NmStationAddress" BU_ CommunicationUnitCellular 74;
BA_ "NmJ1939Function" BU_ CommunicationUnitCellular 54;
BA_ "NmStationAddress" BU_ PropulsionBatteryCharger 73;
BA_ "NmJ1939Function" BU_ PropulsionBatteryCharger 31;
BA_ "NmStationAddress" BU_ ChassisController2 72;
BA_ "NmJ1939Function" BU_ ChassisController2 52;
BA_ "NmJ1939FunctionInstance" BU_ ChassisController2 1;
BA_ "NmStationAddress" BU_ ChassisController1 71;
BA_ "NmJ1939Function" BU_ ChassisController1 52;
BA_ "NmStationAddress" BU_ EngineValveControl 70;
BA_ "NmJ1939Function" BU_ EngineValveControl 63;
BA_ "NmStationAddress" BU_ AuxiliaryHeater2 69;
BA_ "NmJ1939Function" BU_ AuxiliaryHeater2 50;
BA_ "NmJ1939FunctionInstance" BU_ AuxiliaryHeater2 1;
BA_ "NmStationAddress" BU_ AuxiliaryHeater1 68;
BA_ "NmJ1939Function" BU_ AuxiliaryHeater1 50;
BA_ "NmStationAddress" BU_ ClutchUnit 67;
BA_ "NmJ1939Function" BU_ ClutchUnit 49;
BA_ "NmStationAddress" BU_ RampControl 66;
BA_ "NmJ1939Function" BU_ RampControl 48;
BA_ "NmStationAddress" BU_ InformationSystem1 65;
BA_ "NmJ1939Function" BU_ InformationSystem1 47;
BA_ "NmStationAddress" BU_ SuspensionSystemController2 64;
BA_ "NmJ1939Function" BU_ SuspensionSystemController2 35;
BA_ "NmStationAddress" BU_ OilSensor 63;
BA_ "NmJ1939Function" BU_ OilSensor 46;
BA_ "NmStationAddress" BU_ VehicleDynamicStability 62;
BA_ "NmJ1939Function" BU_ VehicleDynamicStability 45;
BA_ "NmStationAddress" BU_ ExhaustEmissionController 61;
BA_ "NmJ1939Function" BU_ ExhaustEmissionController 44;
BA_ "NmStationAddress" BU_ TransmissionDisplay2 60;
BA_ "NmJ1939Function" BU_ TransmissionDisplay2 43;
BA_ "NmStationAddress" BU_ TransmissionDisplay1 59;
BA_ "NmJ1939Function" BU_ TransmissionDisplay1 43;
BA_ "NmStationAddress" BU_ ClimateControl2 58;
BA_ "NmJ1939Function" BU_ ClimateControl2 21;
BA_ "NmStationAddress" BU_ WaterPumpController 57;
BA_ "NmJ1939Function" BU_ WaterPumpController 42;
BA_ "NmStationAddress" BU_ RearAxleSteeringController 56;
BA_ "NmJ1939System" BU_ RearAxleSteeringController 127;
BA_ "NmJ1939Function" BU_ RearAxleSteeringController 255;
BA_ "NmStationAddress" BU_ LightingOperatorControl 55;
BA_ "NmJ1939Function" BU_ LightingOperatorControl 41;
BA_ "NmStationAddress" BU_ SeatController1 54;
BA_ "NmJ1939Function" BU_ SeatController1 40;
BA_ "NmStationAddress" BU_ IgnitionController2 53;
BA_ "NmJ1939Function" BU_ IgnitionController2 39;
BA_ "NmJ1939FunctionInstance" BU_ IgnitionController2 1;
BA_ "NmStationAddress" BU_ IgnitionController1 52;
BA_ "NmJ1939Function" BU_ IgnitionController1 39;
BA_ "NmStationAddress" BU_ TirePressureController 51;
BA_ "NmJ1939Function" BU_ TirePressureController 38;
BA_ "NmStationAddress" BU_ CabController2 50;
BA_ "NmJ1939Function" BU_ CabController2 37;
BA_ "NmStationAddress" BU_ CabController1 49;
BA_ "NmJ1939Function" BU_ CabController1 37;
BA_ "NmStationAddress" BU_ PneumaticSystemController 48;
BA_ "NmJ1939Function" BU_ PneumaticSystemController 36;
BA_ "NmStationAddress" BU_ SuspensionSystemController1 47;
BA_ "NmJ1939Function" BU_ SuspensionSystemController1 35;
BA_ "NmStationAddress" BU_ HydraulicPumpController 46;
BA_ "NmJ1939Function" BU_ HydraulicPumpController 34;
BA_ "NmStationAddress" BU_ EnduranceBrakingSystem 45;
BA_ "NmJ1939Function" BU_ EnduranceBrakingSystem 64;
BA_ "NmStationAddress" BU_ RetarderExhaustEngine2 44;
BA_ "NmJ1939Function" BU_ RetarderExhaustEngine2 12;
BA_ "NmJ1939FunctionInstance" BU_ RetarderExhaustEngine2 1;
BA_ "NmStationAddress" BU_ OnBoardDiagnosticUnit 43;
BA_ "NmJ1939Function" BU_ OnBoardDiagnosticUnit 62;
BA_ "NmStationAddress" BU_ HeadwayController 42;
BA_ "NmJ1939Function" BU_ HeadwayController 32;
BA_ "NmStationAddress" BU_ RetarderExhaustEngine1 41;
BA_ "NmJ1939Function" BU_ RetarderExhaustEngine1 12;
BA_ "NmStationAddress" BU_ CabDisplay1 40;
BA_ "NmJ1939Function" BU_ CabDisplay1 60;
BA_ "NmStationAddress" BU_ ManagementComputer 39;
BA_ "NmJ1939Function" BU_ ManagementComputer 30;
BA_ "NmStationAddress" BU_ VirtualTerminal 38;
BA_ "NmJ1939Function" BU_ VirtualTerminal 29;
BA_ "NmStationAddress" BU_ OffVehicleGateway 37;
BA_ "NmJ1939Function" BU_ OffVehicleGateway 28;
BA_ "NmStationAddress" BU_ PowerTakeOffFront 36;
BA_ "NmJ1939Function" BU_ PowerTakeOffFront 27;
BA_ "NmStationAddress" BU_ HitchControl 35;
BA_ "NmJ1939System" BU_ HitchControl 127;
BA_ "NmJ1939Function" BU_ HitchControl 255;
BA_ "NmStationAddress" BU_ AuxiliaryValveControl 34;
BA_ "NmJ1939IndustryGroup" BU_ AuxiliaryValveControl 2;
BA_ "NmJ1939System" BU_ AuxiliaryValveControl 1;
BA_ "NmJ1939Function" BU_ AuxiliaryValveControl 129;
BA_ "NmStationAddress" BU_ BodyController 33;
BA_ "NmJ1939Function" BU_ BodyController 26;
BA_ "NmStationAddress" BU_ TractorTrailerBridge1 32;
BA_ "NmJ1939System" BU_ TractorTrailerBridge1 127;
BA_ "NmJ1939Function" BU_ TractorTrailerBridge1 255;
BA_ "NmStationAddress" BU_ StarterSystem 31;
BA_ "NmJ1939Function" BU_ StarterSystem 59;
BA_ "NmStationAddress" BU_ ElectricalSystem 30;
BA_ "NmJ1939Function" BU_ ElectricalSystem 67;
BA_ "NmStationAddress" BU_ VehicleSecurity 29;
BA_ "NmJ1939Function" BU_ VehicleSecurity 24;
BA_ "NmStationAddress" BU_ VehicleNavigation 28;
BA_ "NmJ1939Function" BU_ VehicleNavigation 23;
BA_ "NmStationAddress" BU_ AerodynamicControl 27;
BA_ "NmJ1939Function" BU_ AerodynamicControl 22;
BA_ "NmStationAddress" BU_ ElectricalChargingSystem 26;
BA_ "NmJ1939Function" BU_ ElectricalChargingSystem 53;
BA_ "NmStationAddress" BU_ ClimateControl1 25;
BA_ "NmJ1939Function" BU_ ClimateControl1 21;
BA_ "NmStationAddress" BU_ TripRecorder 24;
BA_ "NmJ1939Function" BU_ TripRecorder 20;
BA_ "NmStationAddress" BU_ InstrumentCluster 23;
BA_ "NmJ1939Function" BU_ InstrumentCluster 19;
BA_ "NmStationAddress" BU_ SuspensionDriveAxle2 22;
BA_ "NmJ1939Function" BU_ SuspensionDriveAxle2 18;
BA_ "NmJ1939FunctionInstance" BU_ SuspensionDriveAxle2 1;
BA_ "NmStationAddress" BU_ SuspensionDriveAxle1 21;
BA_ "NmJ1939Function" BU_ SuspensionDriveAxle1 18;
BA_ "NmStationAddress" BU_ SuspensionSteerAxle 20;
BA_ "NmJ1939Function" BU_ SuspensionSteerAxle 17;
BA_ "NmStationAddress" BU_ SteeringController 19;
BA_ "NmJ1939Function" BU_ SteeringController 16;
BA_ "NmStationAddress" BU_ FuelSystem 18;
BA_ "NmJ1939Function" BU_ FuelSystem 15;
BA_ "NmStationAddress" BU_ CruiseControl 17;
BA_ "NmJ1939Function" BU_ CruiseControl 14;
BA_ "NmStationAddress" BU_ RetarderDriveline 16;
BA_ "NmJ1939Function" BU_ RetarderDriveline 13;
BA_ "NmStationAddress" BU_ RetarderEngine 15;
BA_ "NmJ1939Function" BU_ RetarderEngine 12;
BA_ "NmStationAddress" BU_ BrakesDriveAxle2 14;
BA_ "NmJ1939Function" BU_ BrakesDriveAxle2 11;
BA_ "NmJ1939FunctionInstance" BU_ BrakesDriveAxle2 1;
BA_ "NmStationAddress" BU_ BrakesDriveAxle1 13;
BA_ "NmJ1939Function" BU_ BrakesDriveAxle1 11;
BA_ "NmStationAddress" BU_ BrakesSystemController 11;
BA_ "NmJ1939Function" BU_ BrakesSystemController 9;
BA_ "NmStationAddress" BU_ BrakesSteerAxle 12;
BA_ "NmJ1939Function" BU_ BrakesSteerAxle 10;
BA_ "NmStationAddress" BU_ AxleDrive2 10;
BA_ "NmJ1939Function" BU_ AxleDrive2 8;
BA_ "NmJ1939FunctionInstance" BU_ AxleDrive2 1;
BA_ "NmStationAddress" BU_ AxleDrive1 9;
BA_ "NmJ1939Function" BU_ AxleDrive1 8;
BA_ "NmStationAddress" BU_ AxleSteering 8;
BA_ "NmJ1939Function" BU_ AxleSteering 7;
BA_ "NmStationAddress" BU_ PowerTakeOff 7;
BA_ "NmJ1939Function" BU_ PowerTakeOff 6;
BA_ "NmStationAddress" BU_ ShiftConsoleSecondary 6;
BA_ "NmJ1939Function" BU_ ShiftConsoleSecondary 5;
BA_ "NmJ1939FunctionInstance" BU_ ShiftConsoleSecondary 1;
BA_ "NmStationAddress" BU_ ShiftConsolePrimary 5;
BA_ "NmJ1939Function" BU_ ShiftConsolePrimary 5;
BA_ "NmStationAddress" BU_ Transmission2 4;
BA_ "NmJ1939Function" BU_ Transmission2 3;
BA_ "NmJ1939ECUInstance" BU_ Transmission2 1;
BA_ "NmStationAddress" BU_ Transmission1 3;
BA_ "NmJ1939Function" BU_ Transmission1 3;
BA_ "NmStationAddress" BU_ Engine2 1;
BA_ "NmJ1939FunctionInstance" BU_ Engine2 1;
BA_ "NmStationAddress" BU_ Engine1 0;
BA_ "VFrameFormat" BO_ 682 0;
BA_ "VFrameFormat" BO_ 681 0;
BA_ "SAE_Document" BO_ 2566835198 "J1939-73";
BA_ "SAE_Document" BO_ 2315059966 "NMEA2000";
BA_ "GenMsgCycleTime" BO_ 2315059966 100;
BA_ "SAE_Document" BO_ 2381646846 "NMEA2000";
BA_ "GenMsgCycleTime" BO_ 2381646846 1000;
BA_ "SAE_Document" BO_ 2315129598 "NMEA2000";
BA_ "GenMsgCycleTime" BO_ 2315129598 250;
BA_ "SingleFrame" BO_ 2315129598 0;
BA_ "SAE_Document" BO_ 2314277630 "NMEA2000";
BA_ "GenMsgCycleTime" BO_ 2314277630 100;
BA_ "SAE_Document" BO_ 2583172606 "NMEA2000";
BA_ "SingleFrame" BO_ 2583172606 0;
BA_ "SAE_Document" BO_ 2515667198 "NMEA2000";
BA_ "GenMsgCycleTime" BO_ 2515667198 1000;
BA_ "SingleFrame" BO_ 2515667198 0;
BA_ "GenMsgRequestable" BO_ 2515667198 0;
BA_ "SAE_Document" BO_ 2515667454 "NMEA2000";
BA_ "GenMsgCycleTime" BO_ 2515667454 1000;
BA_ "SingleFrame" BO_ 2515667454 0;
BA_ "SAE_Document" BO_ 2314339838 "NMEA2000";
BA_ "GenMsgCycleTime" BO_ 2314339838 100;
BA_ "SAE_Document" BO_ 2314602750 "NMEA2000";
BA_ "GenMsgCycleTime" BO_ 2314602750 1000;
BA_ "SingleFrame" BO_ 2314602750 0;
BA_ "SAE_Document" BO_ 2381842942 "NMEA2000";
BA_ "GenMsgCycleTime" BO_ 2381842942 1000;
BA_ "SAE_Document" BO_ 2381911550 "NMEA2000";
BA_ "GenMsgCycleTime" BO_ 2381911550 1000;
BA_ "SingleFrame" BO_ 2381911550 0;
BA_ "SAE_Document" BO_ 2583499006 "NMEA2000";
BA_ "GenMsgCycleTime" BO_ 2583499006 1000;
BA_ "SingleFrame" BO_ 2583499006 0;
BA_ "SAE_Document" BO_ 2381320446 "NMEA2000";
BA_ "GenMsgCycleTime" BO_ 2381320446 1000;
BA_ "SAE_Document" BO_ 2381451006 "NMEA2000";
BA_ "SAE_Document" BO_ 2314535934 "NMEA2000";
BA_ "GenMsgCycleTime" BO_ 2314535934 1000;
BA_ "SAE_Document" BO_ 2315129086 "NMEA2000";
BA_ "GenMsgCycleTime" BO_ 2315129086 200;
BA_ "SAE_Document" BO_ 2381908990 "NMEA2000";
BA_ "GenMsgCycleTime" BO_ 2381908990 1000;
BA_ "SAE_Document" BO_ 2583499262 "NMEA2000";
BA_ "GenMsgCycleTime" BO_ 2583499262 1000;
BA_ "SingleFrame" BO_ 2583499262 0;
BA_ "SAE_Document" BO_ 2650544894 "NMEA2000";
BA_ "SingleFrame" BO_ 2650544894 0;
BA_ "SAE_Document" BO_ 2650544382 "NMEA2000";
BA_ "SingleFrame" BO_ 2650544382 0;
BA_ "SAE_Document" BO_ 2314276350 "NMEA2000";
BA_ "GenMsgCycleTime" BO_ 2314276350 100;
BA_ "SAE_Document" BO_ 2650543614 "NMEA2000";
BA_ "SingleFrame" BO_ 2650543614 0;
BA_ "SAE_Document" BO_ 2650542846 "NMEA2000";
BA_ "SingleFrame" BO_ 2650542846 0;
BA_ "SAE_Document" BO_ 2650543870 "NMEA2000";
BA_ "SingleFrame" BO_ 2650543870 0;
BA_ "SAE_Document" BO_ 2650543102 "NMEA2000";
BA_ "SingleFrame" BO_ 2650543102 0;
BA_ "SAE_Document" BO_ 2650543358 "NMEA2000";
BA_ "SingleFrame" BO_ 2650543358 0;
BA_ "SAE_Document" BO_ 2650542590 "NMEA2000";
BA_ "SingleFrame" BO_ 2650542590 0;
BA_ "SAE_Document" BO_ 2650544126 "NMEA2000";
BA_ "SingleFrame" BO_ 2650544126 0;
BA_ "SAE_Document" BO_ 2650544638 "NMEA2000";
BA_ "SingleFrame" BO_ 2650544638 0;
BA_ "SAE_Document" BO_ 2650542334 "NMEA2000";
BA_ "SingleFrame" BO_ 2650542334 0;
BA_ "SAE_Document" BO_ 2314277886 "NMEA2000";
BA_ "GenMsgCycleTime" BO_ 2314277886 100;
BA_ "SAE_Document" BO_ 2382039038 "NMEA2000";
BA_ "SingleFrame" BO_ 2382039038 0;
BA_ "SAE_Document" BO_ 2314732542 "NMEA2000";
BA_ "GenMsgCycleTime" BO_ 2314732542 100;
BA_ "GenMsgRequestable" BO_ 2314732542 0;
BA_ "SAE_Document" BO_ 2582648062 "NMEA2000";
BA_ "SingleFrame" BO_ 2582648062 0;
BA_ "SAE_Document" BO_ 2314732030 "NMEA2000";
BA_ "GenMsgCycleTime" BO_ 2314732030 100;
BA_ "SAE_Document" BO_ 2582576894 "NMEA2000";
BA_ "SingleFrame" BO_ 2582576894 0;
BA_ "SAE_Document" BO_ 2583234046 "NMEA2000";
BA_ "SingleFrame" BO_ 2583234046 0;
BA_ "GenMsgRequestable" BO_ 2583234046 0;
BA_ "SAE_Document" BO_ 2381907198 "NMEA2000";
BA_ "GenMsgCycleTime" BO_ 2381907198 1000;
BA_ "SingleFrame" BO_ 2381907198 0;
BA_ "SAE_Document" BO_ 2381184766 "NMEA2000";
BA_ "SingleFrame" BO_ 2381184766 0;
BA_ "SAE_Document" BO_ 2583500030 "NMEA2000";
BA_ "GenMsgCycleTime" BO_ 2583500030 1000;
BA_ "SingleFrame" BO_ 2583500030 0;
BA_ "SAE_Document" BO_ 2583499774 "NMEA2000";
BA_ "GenMsgCycleTime" BO_ 2583499774 1000;
BA_ "SingleFrame" BO_ 2583499774 0;
BA_ "SAE_Document" BO_ 2649823998 "NMEA2000";
BA_ "GenMsgCycleTime" BO_ 2649823998 1000;
BA_ "GenMsgRequestable" BO_ 2649823998 0;
BA_ "SAE_Document" BO_ 2382103806 "NMEA2000";
BA_ "GenMsgCycleTime" BO_ 2382103806 1000;
BA_ "SingleFrame" BO_ 2382103806 0;
BA_ "SAE_Document" BO_ 2382104318 "NMEA2000";
BA_ "GenMsgCycleTime" BO_ 2382104318 1000;
BA_ "SingleFrame" BO_ 2382104318 0;
BA_ "SAE_Document" BO_ 2382104062 "NMEA2000";
BA_ "GenMsgCycleTime" BO_ 2382104062 1000;
BA_ "SingleFrame" BO_ 2382104062 0;
BA_ "SAE_Document" BO_ 2314274302 "NMEA2000";
BA_ "GenMsgCycleTime" BO_ 2314274302 250;
BA_ "SingleFrame" BO_ 2314274302 0;
BA_ "SAE_Document" BO_ 2583299582 "NMEA2000";
BA_ "SingleFrame" BO_ 2583299582 0;
BA_ "SAE_Document" BO_ 2583299326 "NMEA2000";
BA_ "GenMsgCycleTime" BO_ 2583299326 1000;
BA_ "SingleFrame" BO_ 2583299326 0;
BA_ "SAE_Document" BO_ 2583300862 "NMEA2000";
BA_ "SAE_Document" BO_ 2583300606 "NMEA2000";
BA_ "SingleFrame" BO_ 2583300606 0;
BA_ "SAE_Document" BO_ 2583299838 "NMEA2000";
BA_ "GenMsgCycleTime" BO_ 2583299838 1000;
BA_ "SingleFrame" BO_ 2583299838 0;
BA_ "SAE_Document" BO_ 2583301118 "NMEA2000";
BA_ "SingleFrame" BO_ 2583301118 0;
BA_ "GenMsgRequestable" BO_ 2583301118 0;
BA_ "SAE_Document" BO_ 2381841918 "NMEA2000";
BA_ "GenMsgCycleTime" BO_ 2381841918 1000;
BA_ "SingleFrame" BO_ 2381841918 0;
BA_ "SAE_Document" BO_ 2583301886 "NMEA2000";
BA_ "SAE_Document" BO_ 2583302142 "NMEA2000";
BA_ "SingleFrame" BO_ 2583302142 0;
BA_ "SigType" SG_ 3221225472 TrailerWeight 1;
BA_ "SPN" SG_ 3221225472 TrailerWeight 180;
BA_ "SAEDocument" SG_ 3221225472 TrailerWeight "J1939-71";
BA_ "SPN" SG_ 3221225472 ReferenceTirePressSetting 3193;
BA_ "SAEDocument" SG_ 3221225472 ReferenceTirePressSetting "J1939-71";
BA_ "SPN" SG_ 3221225472 ReferenceTirePress 3191;
BA_ "SAEDocument" SG_ 3221225472 ReferenceTirePress "J1939-71";
BA_ "SPN" SG_ 3221225472 TirePressThresholdDetection 2587;
BA_ "SAEDocument" SG_ 3221225472 TirePressThresholdDetection "J1939-71";
BA_ "SigType" SG_ 3221225472 TireAirLeakageRate 1;
BA_ "SPN" SG_ 3221225472 TireAirLeakageRate 2586;
BA_ "SAEDocument" SG_ 3221225472 TireAirLeakageRate "J1939-71";
BA_ "SigType" SG_ 3221225472 CTIWheelEndElectricalFault 4;
BA_ "SPN" SG_ 3221225472 CTIWheelEndElectricalFault 1697;
BA_ "SAEDocument" SG_ 3221225472 CTIWheelEndElectricalFault "J1939-71";
BA_ "SigType" SG_ 3221225472 CTITireStatus 4;
BA_ "SPN" SG_ 3221225472 CTITireStatus 1698;
BA_ "SAEDocument" SG_ 3221225472 CTITireStatus "J1939-71";
BA_ "SigType" SG_ 3221225472 CTIWheelSensorStatus 4;
BA_ "SPN" SG_ 3221225472 CTIWheelSensorStatus 1699;
BA_ "SAEDocument" SG_ 3221225472 CTIWheelSensorStatus "J1939-71";
BA_ "SigType" SG_ 3221225472 TireTemp 1;
BA_ "SPN" SG_ 3221225472 TireTemp 242;
BA_ "SAEDocument" SG_ 3221225472 TireTemp "J1939-71";
BA_ "SigType" SG_ 3221225472 TirePress 1;
BA_ "SPN" SG_ 3221225472 TirePress 241;
BA_ "SAEDocument" SG_ 3221225472 TirePress "J1939-71";
BA_ "SigType" SG_ 3221225472 EngTurningGearEngaged 4;
BA_ "SPN" SG_ 3221225472 EngTurningGearEngaged 1206;
BA_ "SAEDocument" SG_ 3221225472 EngTurningGearEngaged "J1939-71";
BA_ "SystemSignalLongSymbol" SG_ 3221225472 ChangeChildPositionParentObjectI "ChangeChildPositionParentObjectID";
BA_ "SystemSignalLongSymbol" SG_ 3221225472 ChangeChildLocationParentObjectI "ChangeChildLocationParentObjectID";
BA_ "SigType" SG_ 3221225472 MalfunctionIndicatorLampStatus 4;
BA_ "SPN" SG_ 3221225472 MalfunctionIndicatorLampStatus 1213;
BA_ "SAEDocument" SG_ 3221225472 MalfunctionIndicatorLampStatus "J1939-73";
BA_ "SigType" SG_ 3221225472 RedStopLampState 4;
BA_ "SPN" SG_ 3221225472 RedStopLampState 623;
BA_ "SAEDocument" SG_ 3221225472 RedStopLampState "J1939-73";
BA_ "SigType" SG_ 3221225472 AmberWarningLampStatus 4;
BA_ "SPN" SG_ 3221225472 AmberWarningLampStatus 624;
BA_ "SAEDocument" SG_ 3221225472 AmberWarningLampStatus "J1939-73";
BA_ "SigType" SG_ 3221225472 ProtectLampStatus 4;
BA_ "SPN" SG_ 3221225472 ProtectLampStatus 987;
BA_ "SAEDocument" SG_ 3221225472 ProtectLampStatus "J1939-73";
BA_ "SigType" SG_ 3221225472 FlashRedStopLamp 4;
BA_ "SPN" SG_ 3221225472 FlashRedStopLamp 3039;
BA_ "SAEDocument" SG_ 3221225472 FlashRedStopLamp "J1939-73";
BA_ "SigType" SG_ 3221225472 FlashProtectLamp 4;
BA_ "SPN" SG_ 3221225472 FlashProtectLamp 3041;
BA_ "SAEDocument" SG_ 3221225472 FlashProtectLamp "J1939-73";
BA_ "SigType" SG_ 3221225472 FlashMalfuncIndicatorLamp 4;
BA_ "SPN" SG_ 3221225472 FlashMalfuncIndicatorLamp 3038;
BA_ "SAEDocument" SG_ 3221225472 FlashMalfuncIndicatorLamp "J1939-73";
BA_ "SigType" SG_ 3221225472 FlashAmberWarningLamp 4;
BA_ "SPN" SG_ 3221225472 FlashAmberWarningLamp 3040;
BA_ "SAEDocument" SG_ 3221225472 FlashAmberWarningLamp "J1939-73";
BA_ "SigType" SG_ 3221225472 DTC5 7;
BA_ "SAEDocument" SG_ 3221225472 DTC5 "J1939-73";
BA_ "SigType" SG_ 3221225472 DTC4 7;
BA_ "SAEDocument" SG_ 3221225472 DTC4 "J1939-73";
BA_ "SigType" SG_ 3221225472 DTC3 7;
BA_ "SAEDocument" SG_ 3221225472 DTC3 "J1939-73";
BA_ "SigType" SG_ 3221225472 DTC2 7;
BA_ "SAEDocument" SG_ 3221225472 DTC2 "J1939-73";
BA_ "SigType" SG_ 3221225472 DTC1 7;
BA_ "SAEDocument" SG_ 3221225472 DTC1 "J1939-73";
BA_ "SigType" SG_ 2566835198 FlashRedStopLamp 4;
BA_ "SPN" SG_ 2566835198 FlashRedStopLamp 3039;
BA_ "SAEDocument" SG_ 2566835198 FlashRedStopLamp "J1939-73";
BA_ "SigType" SG_ 2566835198 FlashProtectLamp 4;
BA_ "SPN" SG_ 2566835198 FlashProtectLamp 3041;
BA_ "SAEDocument" SG_ 2566835198 FlashProtectLamp "J1939-73";
BA_ "SigType" SG_ 2566835198 FlashMalfuncIndicatorLamp 4;
BA_ "SPN" SG_ 2566835198 FlashMalfuncIndicatorLamp 3038;
BA_ "SAEDocument" SG_ 2566835198 FlashMalfuncIndicatorLamp "J1939-73";
BA_ "SigType" SG_ 2566835198 FlashAmberWarningLamp 4;
BA_ "SPN" SG_ 2566835198 FlashAmberWarningLamp 3040;
BA_ "SAEDocument" SG_ 2566835198 FlashAmberWarningLamp "J1939-73";
BA_ "SigType" SG_ 2566835198 MalfunctionIndicatorLampStatus 4;
BA_ "SPN" SG_ 2566835198 MalfunctionIndicatorLampStatus 1213;
BA_ "SAEDocument" SG_ 2566835198 MalfunctionIndicatorLampStatus "J1939-73";
BA_ "SigType" SG_ 2566835198 AmberWarningLampStatus 4;
BA_ "SPN" SG_ 2566835198 AmberWarningLampStatus 624;
BA_ "SAEDocument" SG_ 2566835198 AmberWarningLampStatus "J1939-73";
BA_ "SigType" SG_ 2566835198 RedStopLampState 4;
BA_ "SPN" SG_ 2566835198 RedStopLampState 623;
BA_ "SAEDocument" SG_ 2566835198 RedStopLampState "J1939-73";
BA_ "SigType" SG_ 2566835198 ProtectLampStatus 4;
BA_ "SPN" SG_ 2566835198 ProtectLampStatus 987;
BA_ "SAEDocument" SG_ 2566835198 ProtectLampStatus "J1939-73";
BA_ "SAEDocument" SG_ 2315059966 WindReference "NMEA2000";
BA_ "SAEDocument" SG_ 2315059966 WindDirection "NMEA2000";
BA_ "SigType" SG_ 2315059966 WindDirection 1;
BA_ "DDI" SG_ 2315059966 WindDirection 208;
BA_ "SAEDocument" SG_ 2315059966 WindSpeed "NMEA2000";
BA_ "SigType" SG_ 2315059966 WindSpeed 1;
BA_ "DDI" SG_ 2315059966 WindSpeed 207;
BA_ "SAEDocument" SG_ 2315059966 SequenceID_ "NMEA2000";
BA_ "SigType" SG_ 2315059966 SequenceID_ 1;
BA_ "SAEDocument" SG_ 2381646846 Offset "NMEA2000";
BA_ "SigType" SG_ 2381646846 Offset 2;
BA_ "SAEDocument" SG_ 2381646846 WaterDepthTransducer "NMEA2000";
BA_ "SigType" SG_ 2381646846 WaterDepthTransducer 1;
BA_ "SAEDocument" SG_ 2381646846 SID "NMEA2000";
BA_ "SigType" SG_ 2381646846 SID 1;
BA_ "SAEDocument" SG_ 2315129598 SternSpeedGroundreferenced "NMEA2000";
BA_ "SigType" SG_ 2315129598 SternSpeedGroundreferenced 2;
BA_ "SAEDocument" SG_ 2315129598 SternSpeedWaterreferenced "NMEA2000";
BA_ "SigType" SG_ 2315129598 SternSpeedWaterreferenced 2;
BA_ "SAEDocument" SG_ 2315129598 TransverseSpeedGroundreferenced "NMEA2000";
BA_ "SigType" SG_ 2315129598 TransverseSpeedGroundreferenced 2;
BA_ "SAEDocument" SG_ 2315129598 LngtudinalSpeedGroundreferenced "NMEA2000";
BA_ "SigType" SG_ 2315129598 LngtudinalSpeedGroundreferenced 2;
BA_ "SAEDocument" SG_ 2315129598 TransverseSpeedWaterreferenced "NMEA2000";
BA_ "SigType" SG_ 2315129598 TransverseSpeedWaterreferenced 2;
BA_ "SAEDocument" SG_ 2315129598 LngitudinalSpeedWaterreferenced "NMEA2000";
BA_ "SigType" SG_ 2315129598 LngitudinalSpeedWaterreferenced 2;
BA_ "SAEDocument" SG_ 2314277630 HeadingSensorReference "NMEA2000";
BA_ "SigType" SG_ 2314277630 HeadingSensorReference 4;
BA_ "SAEDocument" SG_ 2314277630 Variation "NMEA2000";
BA_ "SigType" SG_ 2314277630 Variation 2;
BA_ "SAEDocument" SG_ 2314277630 Deviation "NMEA2000";
BA_ "SigType" SG_ 2314277630 Deviation 2;
BA_ "SAEDocument" SG_ 2314277630 HeadingSensorReading "NMEA2000";
BA_ "SigType" SG_ 2314277630 HeadingSensorReading 1;
BA_ "SAEDocument" SG_ 2314277630 SID "NMEA2000";
BA_ "SigType" SG_ 2314277630 SID 1;
BA_ "SAEDocument" SG_ 2583172606 DatumName "NMEA2000";
BA_ "SigType" SG_ 2583172606 DatumName 1;
BA_ "SAEDocument" SG_ 2583172606 EllipsoidFlatteningInverse "NMEA2000";
BA_ "SigType" SG_ 2583172606 EllipsoidFlatteningInverse 2;
BA_ "SAEDocument" SG_ 2583172606 EllipsoidSemimajorAxis "NMEA2000";
BA_ "SigType" SG_ 2583172606 EllipsoidSemimajorAxis 2;
BA_ "SAEDocument" SG_ 2583172606 Scale "NMEA2000";
BA_ "SigType" SG_ 2583172606 Scale 2;
BA_ "SAEDocument" SG_ 2583172606 RotationInZ "NMEA2000";
BA_ "SigType" SG_ 2583172606 RotationInZ 2;
BA_ "SAEDocument" SG_ 2583172606 RotationInY "NMEA2000";
BA_ "SigType" SG_ 2583172606 RotationInY 2;
BA_ "SAEDocument" SG_ 2583172606 RotationInX "NMEA2000";
BA_ "SigType" SG_ 2583172606 RotationInX 2;
BA_ "SAEDocument" SG_ 2583172606 DeltaZ "NMEA2000";
BA_ "SigType" SG_ 2583172606 DeltaZ 2;
BA_ "SAEDocument" SG_ 2583172606 DeltaY "NMEA2000";
BA_ "SigType" SG_ 2583172606 DeltaY 2;
BA_ "SAEDocument" SG_ 2583172606 DeltaX "NMEA2000";
BA_ "SigType" SG_ 2583172606 DeltaX 2;
BA_ "SAEDocument" SG_ 2515667198 TripRunTime "NMEA2000";
BA_ "SigType" SG_ 2515667198 TripRunTime 1;
BA_ "SAEDocument" SG_ 2515667198 EstFuelRemaining "NMEA2000";
BA_ "SigType" SG_ 2515667198 EstFuelRemaining 1;
BA_ "SAEDocument" SG_ 2515667198 DistanceToEmpty "NMEA2000";
BA_ "SigType" SG_ 2515667198 DistanceToEmpty 1;
BA_ "SAEDocument" SG_ 2515667198 TimeToEmpty "NMEA2000";
BA_ "SigType" SG_ 2515667198 TimeToEmpty 1;
BA_ "SAEDocument" SG_ 2515667454 InstantaneousFuelEconomy "NMEA2000";
BA_ "SigType" SG_ 2515667454 InstantaneousFuelEconomy 2;
BA_ "SAEDocument" SG_ 2515667454 FuelRateEconomy "NMEA2000";
BA_ "SigType" SG_ 2515667454 FuelRateEconomy 2;
BA_ "SAEDocument" SG_ 2515667454 FuelRateAverage "NMEA2000";
BA_ "SigType" SG_ 2515667454 FuelRateAverage 2;
BA_ "SAEDocument" SG_ 2515667454 TripFuelUsed "NMEA2000";
BA_ "SigType" SG_ 2515667454 TripFuelUsed 1;
BA_ "SAEDocument" SG_ 2515667454 EngInstance "NMEA2000";
BA_ "SigType" SG_ 2515667454 EngInstance 1;
BA_ "SAEDocument" SG_ 2314339838 TransDiscreteStatus "NMEA2000";
BA_ "SigType" SG_ 2314339838 TransDiscreteStatus 1;
BA_ "SAEDocument" SG_ 2314339838 TransOilTemp_ "NMEA2000";
BA_ "SigType" SG_ 2314339838 TransOilTemp_ 1;
BA_ "SAEDocument" SG_ 2314339838 TransOilPress_ "NMEA2000";
BA_ "SigType" SG_ 2314339838 TransOilPress_ 1;
BA_ "SAEDocument" SG_ 2314339838 TransGear "NMEA2000";
BA_ "SAEDocument" SG_ 2314339838 TransInstance "NMEA2000";
BA_ "SigType" SG_ 2314339838 TransInstance 1;
BA_ "SAEDocument" SG_ 2314602750 CPA "NMEA2000";
BA_ "SigType" SG_ 2314602750 CPA 2;
BA_ "SAEDocument" SG_ 2314602750 Speed "NMEA2000";
BA_ "SigType" SG_ 2314602750 Speed 1;
BA_ "SAEDocument" SG_ 2314602750 Course "NMEA2000";
BA_ "SigType" SG_ 2314602750 Course 1;
BA_ "SAEDocument" SG_ 2314602750 Distance "NMEA2000";
BA_ "SigType" SG_ 2314602750 Distance 2;
BA_ "SAEDocument" SG_ 2314602750 Bearing "NMEA2000";
BA_ "SigType" SG_ 2314602750 Bearing 1;
BA_ "SAEDocument" SG_ 2314602750 BearingReference "NMEA2000";
BA_ "SAEDocument" SG_ 2314602750 TrackStatus "NMEA2000";
BA_ "SAEDocument" SG_ 2314602750 TargetID "NMEA2000";
BA_ "SigType" SG_ 2314602750 TargetID 1;
BA_ "SAEDocument" SG_ 2314602750 SequenceID_ "NMEA2000";
BA_ "SigType" SG_ 2314602750 SequenceID_ 1;
BA_ "SAEDocument" SG_ 2314602750 Name "NMEA2000";
BA_ "SigType" SG_ 2314602750 Name 1;
BA_ "SAEDocument" SG_ 2314602750 UTCOfFix "NMEA2000";
BA_ "SigType" SG_ 2314602750 UTCOfFix 1;
BA_ "SAEDocument" SG_ 2314602750 TCPA "NMEA2000";
BA_ "SigType" SG_ 2314602750 TCPA 2;
BA_ "SAEDocument" SG_ 2381842942 LocalOffsetMinutes "NMEA2000";
BA_ "SigType" SG_ 2381842942 LocalOffsetMinutes 2;
BA_ "SAEDocument" SG_ 2381842942 Time "NMEA2000";
BA_ "SigType" SG_ 2381842942 Time 1;
BA_ "SAEDocument" SG_ 2381842942 Date "NMEA2000";
BA_ "SigType" SG_ 2381842942 Date 1;
BA_ "SAEDocument" SG_ 2381911550 MarkID "NMEA2000";
BA_ "SigType" SG_ 2381911550 MarkID 1;
BA_ "SAEDocument" SG_ 2381911550 MarkType "NMEA2000";
BA_ "SAEDocument" SG_ 2381911550 TimeElapsedTogoToMark "NMEA2000";
BA_ "SigType" SG_ 2381911550 TimeElapsedTogoToMark 2;
BA_ "SAEDocument" SG_ 2381911550 SID "NMEA2000";
BA_ "SigType" SG_ 2381911550 SID 1;
BA_ "SAEDocument" SG_ 2583499006 StationIDString "NMEA2000";
BA_ "SigType" SG_ 2583499006 StationIDString 1;
BA_ "SAEDocument" SG_ 2583499006 TideLevelStandardDeviation "NMEA2000";
BA_ "SigType" SG_ 2583499006 TideLevelStandardDeviation 1;
BA_ "SAEDocument" SG_ 2583499006 TideLevel "NMEA2000";
BA_ "SigType" SG_ 2583499006 TideLevel 2;
BA_ "SAEDocument" SG_ 2583499006 StationLocationLongitude "NMEA2000";
BA_ "SigType" SG_ 2583499006 StationLocationLongitude 2;
BA_ "SAEDocument" SG_ 2583499006 StationLocationLatitude "NMEA2000";
BA_ "SigType" SG_ 2583499006 StationLocationLatitude 2;
BA_ "SAEDocument" SG_ 2583499006 MeasurementTime "NMEA2000";
BA_ "SigType" SG_ 2583499006 MeasurementTime 1;
BA_ "SAEDocument" SG_ 2583499006 MeasurementDate "NMEA2000";
BA_ "SigType" SG_ 2583499006 MeasurementDate 1;
BA_ "SAEDocument" SG_ 2583499006 TideTendency "NMEA2000";
BA_ "SigType" SG_ 2583499006 TideTendency 4;
BA_ "SAEDocument" SG_ 2583499006 Mode "NMEA2000";
BA_ "SAEDocument" SG_ 2381320446 Time "NMEA2000";
BA_ "SigType" SG_ 2381320446 Time 1;
BA_ "SAEDocument" SG_ 2381320446 Date "NMEA2000";
BA_ "SigType" SG_ 2381320446 Date 1;
BA_ "SAEDocument" SG_ 2381320446 Source "NMEA2000";
BA_ "SAEDocument" SG_ 2381320446 SID "NMEA2000";
BA_ "SigType" SG_ 2381320446 SID 1;
BA_ "SAEDocument" SG_ 2381451006 Switch28 "NMEA2000";
BA_ "SigType" SG_ 2381451006 Switch28 4;
BA_ "SAEDocument" SG_ 2381451006 Switch27 "NMEA2000";
BA_ "SigType" SG_ 2381451006 Switch27 4;
BA_ "SAEDocument" SG_ 2381451006 Switch26 "NMEA2000";
BA_ "SigType" SG_ 2381451006 Switch26 4;
BA_ "SAEDocument" SG_ 2381451006 Switch25 "NMEA2000";
BA_ "SigType" SG_ 2381451006 Switch25 4;
BA_ "SAEDocument" SG_ 2381451006 Switch24 "NMEA2000";
BA_ "SigType" SG_ 2381451006 Switch24 4;
BA_ "SAEDocument" SG_ 2381451006 Switch23 "NMEA2000";
BA_ "SigType" SG_ 2381451006 Switch23 4;
BA_ "SAEDocument" SG_ 2381451006 Switch22 "NMEA2000";
BA_ "SigType" SG_ 2381451006 Switch22 4;
BA_ "SAEDocument" SG_ 2381451006 Switch21 "NMEA2000";
BA_ "SigType" SG_ 2381451006 Switch21 4;
BA_ "SAEDocument" SG_ 2381451006 Switch20 "NMEA2000";
BA_ "SigType" SG_ 2381451006 Switch20 4;
BA_ "SAEDocument" SG_ 2381451006 Switch19 "NMEA2000";
BA_ "SigType" SG_ 2381451006 Switch19 4;
BA_ "SAEDocument" SG_ 2381451006 Switch18 "NMEA2000";
BA_ "SigType" SG_ 2381451006 Switch18 4;
BA_ "SAEDocument" SG_ 2381451006 Switch17 "NMEA2000";
BA_ "SigType" SG_ 2381451006 Switch17 4;
BA_ "SAEDocument" SG_ 2381451006 Switch16 "NMEA2000";
BA_ "SigType" SG_ 2381451006 Switch16 4;
BA_ "SAEDocument" SG_ 2381451006 Switch15 "NMEA2000";
BA_ "SigType" SG_ 2381451006 Switch15 4;
BA_ "SAEDocument" SG_ 2381451006 Switch14 "NMEA2000";
BA_ "SigType" SG_ 2381451006 Switch14 4;
BA_ "SAEDocument" SG_ 2381451006 Switch13 "NMEA2000";
BA_ "SigType" SG_ 2381451006 Switch13 4;
BA_ "SAEDocument" SG_ 2381451006 Switch12 "NMEA2000";
BA_ "SigType" SG_ 2381451006 Switch12 4;
BA_ "SAEDocument" SG_ 2381451006 Switch11 "NMEA2000";
BA_ "SigType" SG_ 2381451006 Switch11 4;
BA_ "SAEDocument" SG_ 2381451006 Switch10 "NMEA2000";
BA_ "SigType" SG_ 2381451006 Switch10 4;
BA_ "SAEDocument" SG_ 2381451006 Switch9 "NMEA2000";
BA_ "SigType" SG_ 2381451006 Switch9 4;
BA_ "SAEDocument" SG_ 2381451006 Switch8 "NMEA2000";
BA_ "SigType" SG_ 2381451006 Switch8 4;
BA_ "SAEDocument" SG_ 2381451006 Switch7 "NMEA2000";
BA_ "SigType" SG_ 2381451006 Switch7 4;
BA_ "SAEDocument" SG_ 2381451006 Switch6 "NMEA2000";
BA_ "SigType" SG_ 2381451006 Switch6 4;
BA_ "SAEDocument" SG_ 2381451006 Switch5 "NMEA2000";
BA_ "SigType" SG_ 2381451006 Switch5 4;
BA_ "SAEDocument" SG_ 2381451006 Switch4 "NMEA2000";
BA_ "SigType" SG_ 2381451006 Switch4 4;
BA_ "SAEDocument" SG_ 2381451006 Switch3 "NMEA2000";
BA_ "SigType" SG_ 2381451006 Switch3 4;
BA_ "SAEDocument" SG_ 2381451006 Switch2 "NMEA2000";
BA_ "SigType" SG_ 2381451006 Switch2 4;
BA_ "SAEDocument" SG_ 2381451006 Switch1 "NMEA2000";
BA_ "SigType" SG_ 2381451006 Switch1 4;
BA_ "SAEDocument" SG_ 2381451006 SwitchBankInstance "NMEA2000";
BA_ "SigType" SG_ 2381451006 SwitchBankInstance 1;
BA_ "SAEDocument" SG_ 2314535934 SpeedGroundReferenced "NMEA2000";
BA_ "SigType" SG_ 2314535934 SpeedGroundReferenced 1;
BA_ "SAEDocument" SG_ 2314535934 SpeedWaterReferenced "NMEA2000";
BA_ "SigType" SG_ 2314535934 SpeedWaterReferenced 1;
BA_ "SAEDocument" SG_ 2314535934 SequenceID_ "NMEA2000";
BA_ "SigType" SG_ 2314535934 SequenceID_ 1;
BA_ "SAEDocument" SG_ 2315129086 StarboardTrimTab "NMEA2000";
BA_ "SigType" SG_ 2315129086 StarboardTrimTab 2;
BA_ "SAEDocument" SG_ 2315129086 PortTrimTab "NMEA2000";
BA_ "SigType" SG_ 2315129086 PortTrimTab 2;
BA_ "SAEDocument" SG_ 2381908990 Drift "NMEA2000";
BA_ "SigType" SG_ 2381908990 Drift 1;
BA_ "SAEDocument" SG_ 2381908990 Set "NMEA2000";
BA_ "SigType" SG_ 2381908990 Set 1;
BA_ "SAEDocument" SG_ 2381908990 SetReference "NMEA2000";
BA_ "SigType" SG_ 2381908990 SetReference 4;
BA_ "SAEDocument" SG_ 2381908990 SID "NMEA2000";
BA_ "SigType" SG_ 2381908990 SID 1;
BA_ "SAEDocument" SG_ 2583499262 StationIDString "NMEA2000";
BA_ "SigType" SG_ 2583499262 StationIDString 1;
BA_ "SAEDocument" SG_ 2583499262 WaterTemp "NMEA2000";
BA_ "SigType" SG_ 2583499262 WaterTemp 1;
BA_ "SAEDocument" SG_ 2583499262 Salinity "NMEA2000";
BA_ "SigType" SG_ 2583499262 Salinity 2;
BA_ "SAEDocument" SG_ 2583499262 StationLocationLongitude "NMEA2000";
BA_ "SigType" SG_ 2583499262 StationLocationLongitude 2;
BA_ "SAEDocument" SG_ 2583499262 StationLocationLatitude "NMEA2000";
BA_ "SigType" SG_ 2583499262 StationLocationLatitude 2;
BA_ "SAEDocument" SG_ 2583499262 MeasurementTime "NMEA2000";
BA_ "SigType" SG_ 2583499262 MeasurementTime 1;
BA_ "SAEDocument" SG_ 2583499262 MeasurementDate "NMEA2000";
BA_ "SigType" SG_ 2583499262 MeasurementDate 1;
BA_ "SAEDocument" SG_ 2583499262 Mode "NMEA2000";
BA_ "SAEDocument" SG_ 2650544894 WPName "NMEA2000";
BA_ "SigType" SG_ 2650544894 WPName 1;
BA_ "SAEDocument" SG_ 2650544894 WPID "NMEA2000";
BA_ "SigType" SG_ 2650544894 WPID 1;
BA_ "SAEDocument" SG_ 2650544894 reserved "NMEA2000";
BA_ "SigType" SG_ 2650544894 reserved 1;
BA_ "SAEDocument" SG_ 2650544894 DatabaseID "NMEA2000";
BA_ "SigType" SG_ 2650544894 DatabaseID 1;
BA_ "SAEDocument" SG_ 2650544894 NumberOfValidWPsInWPList "NMEA2000";
BA_ "SigType" SG_ 2650544894 NumberOfValidWPsInWPList 1;
BA_ "SAEDocument" SG_ 2650544894 nItems "NMEA2000";
BA_ "SigType" SG_ 2650544894 nItems 1;
BA_ "SAEDocument" SG_ 2650544894 StartWPID "NMEA2000";
BA_ "SigType" SG_ 2650544894 StartWPID 1;
BA_ "SAEDocument" SG_ 2650544382 CommentText "NMEA2000";
BA_ "SigType" SG_ 2650544382 CommentText 1;
BA_ "SAEDocument" SG_ 2650544382 DatabaseID "NMEA2000";
BA_ "SigType" SG_ 2650544382 DatabaseID 1;
BA_ "SAEDocument" SG_ 2650544382 NumberOfDatabasesWithComments "NMEA2000";
BA_ "SigType" SG_ 2650544382 NumberOfDatabasesWithComments 1;
BA_ "SAEDocument" SG_ 2650544382 nItems "NMEA2000";
BA_ "SigType" SG_ 2650544382 nItems 1;
BA_ "SAEDocument" SG_ 2650544382 StartDatabaseID "NMEA2000";
BA_ "SigType" SG_ 2650544382 StartDatabaseID 1;
BA_ "SAEDocument" SG_ 2314276350 Pos "NMEA2000";
BA_ "SigType" SG_ 2314276350 Pos 2;
BA_ "SAEDocument" SG_ 2314276350 Angleder "NMEA2000";
BA_ "SigType" SG_ 2314276350 Angleder 2;
BA_ "SAEDocument" SG_ 2314276350 Directionder "NMEA2000";
BA_ "SAEDocument" SG_ 2314276350 RudderInstance "NMEA2000";
BA_ "SigType" SG_ 2314276350 RudderInstance 1;
BA_ "SAEDocument" SG_ 2650543614 NavMethodInLegAfterWP "NMEA2000";
BA_ "SigType" SG_ 2650543614 NavMethodInLegAfterWP 4;
BA_ "SAEDocument" SG_ 2650543614 XTELimitInLegAfterWP "NMEA2000";
BA_ "SigType" SG_ 2650543614 XTELimitInLegAfterWP 2;
BA_ "SAEDocument" SG_ 2650543614 RPS "NMEA2000";
BA_ "SigType" SG_ 2650543614 RPS 1;
BA_ "SAEDocument" SG_ 2650543614 RouteID "NMEA2000";
BA_ "SigType" SG_ 2650543614 RouteID 1;
BA_ "SAEDocument" SG_ 2650543614 DatabaseID "NMEA2000";
BA_ "SigType" SG_ 2650543614 DatabaseID 1;
BA_ "SAEDocument" SG_ 2650543614 NmbrOfWypntsWthASpcfcXTELmtNvMth "NMEA2000";
BA_ "SigType" SG_ 2650543614 NmbrOfWypntsWthASpcfcXTELmtNvMth 1;
BA_ "SAEDocument" SG_ 2650543614 nItems "NMEA2000";
BA_ "SigType" SG_ 2650543614 nItems 1;
BA_ "SAEDocument" SG_ 2650543614 StartRPS "NMEA2000";
BA_ "SigType" SG_ 2650543614 StartRPS 1;
BA_ "SAEDocument" SG_ 2650542846 Route_WPListName "NMEA2000";
BA_ "SigType" SG_ 2650542846 Route_WPListName 1;
BA_ "SAEDocument" SG_ 2650542846 RouteID "NMEA2000";
BA_ "SigType" SG_ 2650542846 RouteID 1;
BA_ "SAEDocument" SG_ 2650542846 DatabaseID "NMEA2000";
BA_ "SigType" SG_ 2650542846 DatabaseID 1;
BA_ "SAEDocument" SG_ 2650543870 Comment "NMEA2000";
BA_ "SigType" SG_ 2650543870 Comment 1;
BA_ "SAEDocument" SG_ 2650543870 WPID_RPS "NMEA2000";
BA_ "SigType" SG_ 2650543870 WPID_RPS 1;
BA_ "SAEDocument" SG_ 2650543870 RouteID "NMEA2000";
BA_ "SigType" SG_ 2650543870 RouteID 1;
BA_ "SAEDocument" SG_ 2650543870 DatabaseID "NMEA2000";
BA_ "SigType" SG_ 2650543870 DatabaseID 1;
BA_ "SAEDocument" SG_ 2650543870 NumberOfWPsWithComments "NMEA2000";
BA_ "SigType" SG_ 2650543870 NumberOfWPsWithComments 1;
BA_ "SAEDocument" SG_ 2650543870 nItems "NMEA2000";
BA_ "SigType" SG_ 2650543870 nItems 1;
BA_ "SAEDocument" SG_ 2650543870 StartID "NMEA2000";
BA_ "SigType" SG_ 2650543870 StartID 1;
BA_ "SAEDocument" SG_ 2650543102 WPName "NMEA2000";
BA_ "SigType" SG_ 2650543102 WPName 1;
BA_ "SAEDocument" SG_ 2650543102 WPID "NMEA2000";
BA_ "SigType" SG_ 2650543102 WPID 1;
BA_ "SAEDocument" SG_ 2650543102 RouteID "NMEA2000";
BA_ "SigType" SG_ 2650543102 RouteID 1;
BA_ "SAEDocument" SG_ 2650543102 DatabaseID "NMEA2000";
BA_ "SigType" SG_ 2650543102 DatabaseID 1;
BA_ "SAEDocument" SG_ 2650543102 NumberOfWPsInRoute "NMEA2000";
BA_ "SigType" SG_ 2650543102 NumberOfWPsInRoute 1;
BA_ "SAEDocument" SG_ 2650543102 nItems "NMEA2000";
BA_ "SigType" SG_ 2650543102 nItems 1;
BA_ "SAEDocument" SG_ 2650543102 StartRPS "NMEA2000";
BA_ "SigType" SG_ 2650543102 StartRPS 1;
BA_ "SAEDocument" SG_ 2650543358 WPName "NMEA2000";
BA_ "SigType" SG_ 2650543358 WPName 1;
BA_ "SAEDocument" SG_ 2650543358 WPID "NMEA2000";
BA_ "SigType" SG_ 2650543358 WPID 1;
BA_ "SAEDocument" SG_ 2650543358 RouteID "NMEA2000";
BA_ "SigType" SG_ 2650543358 RouteID 1;
BA_ "SAEDocument" SG_ 2650543358 DatabaseID "NMEA2000";
BA_ "SigType" SG_ 2650543358 DatabaseID 1;
BA_ "SAEDocument" SG_ 2650543358 NumberOfWPsInRoute "NMEA2000";
BA_ "SigType" SG_ 2650543358 NumberOfWPsInRoute 1;
BA_ "SAEDocument" SG_ 2650543358 nItems "NMEA2000";
BA_ "SigType" SG_ 2650543358 nItems 1;
BA_ "SAEDocument" SG_ 2650543358 StartRPS "NMEA2000";
BA_ "SigType" SG_ 2650543358 StartRPS 1;
BA_ "SAEDocument" SG_ 2650542590 RouteName "NMEA2000";
BA_ "SigType" SG_ 2650542590 RouteName 1;
BA_ "SAEDocument" SG_ 2650542590 RouteID "NMEA2000";
BA_ "SigType" SG_ 2650542590 RouteID 1;
BA_ "SAEDocument" SG_ 2650542590 DatabaseID "NMEA2000";
BA_ "SigType" SG_ 2650542590 DatabaseID 1;
BA_ "SAEDocument" SG_ 2650542590 NmbrOfRoutesAvailableInDatabase "NMEA2000";
BA_ "SigType" SG_ 2650542590 NmbrOfRoutesAvailableInDatabase 1;
BA_ "SAEDocument" SG_ 2650542590 nItems "NMEA2000";
BA_ "SigType" SG_ 2650542590 nItems 1;
BA_ "SAEDocument" SG_ 2650542590 StartRouteID "NMEA2000";
BA_ "SigType" SG_ 2650542590 StartRouteID 1;
BA_ "SAEDocument" SG_ 2650544126 Comment "NMEA2000";
BA_ "SigType" SG_ 2650544126 Comment 1;
BA_ "SAEDocument" SG_ 2650544126 RouteID "NMEA2000";
BA_ "SigType" SG_ 2650544126 RouteID 1;
BA_ "SAEDocument" SG_ 2650544126 DatabaseID "NMEA2000";
BA_ "SigType" SG_ 2650544126 DatabaseID 1;
BA_ "SAEDocument" SG_ 2650544126 NumberOfRoutesWithComments "NMEA2000";
BA_ "SigType" SG_ 2650544126 NumberOfRoutesWithComments 1;
BA_ "SAEDocument" SG_ 2650544126 nItems "NMEA2000";
BA_ "SigType" SG_ 2650544126 nItems 1;
BA_ "SAEDocument" SG_ 2650544126 StartRouteID "NMEA2000";
BA_ "SigType" SG_ 2650544126 StartRouteID 1;
BA_ "SAEDocument" SG_ 2650544638 RadiusOfTurn "NMEA2000";
BA_ "SigType" SG_ 2650544638 RadiusOfTurn 2;
BA_ "SAEDocument" SG_ 2650544638 RPS "NMEA2000";
BA_ "SigType" SG_ 2650544638 RPS 1;
BA_ "SAEDocument" SG_ 2650544638 RouteID "NMEA2000";
BA_ "SigType" SG_ 2650544638 RouteID 1;
BA_ "SAEDocument" SG_ 2650544638 DatabaseID "NMEA2000";
BA_ "SigType" SG_ 2650544638 DatabaseID 1;
BA_ "SAEDocument" SG_ 2650544638 NmbrOfWypntsWthASpcfcRdusOfTurn "NMEA2000";
BA_ "SigType" SG_ 2650544638 NmbrOfWypntsWthASpcfcRdusOfTurn 1;
BA_ "SAEDocument" SG_ 2650544638 nItems "NMEA2000";
BA_ "SigType" SG_ 2650544638 nItems 1;
BA_ "SAEDocument" SG_ 2650544638 StartRPS "NMEA2000";
BA_ "SigType" SG_ 2650544638 StartRPS 1;
BA_ "SAEDocument" SG_ 2650542334 DatabaseName "NMEA2000";
BA_ "SigType" SG_ 2650542334 DatabaseName 1;
BA_ "SAEDocument" SG_ 2650542334 DatabaseID "NMEA2000";
BA_ "SigType" SG_ 2650542334 DatabaseID 1;
BA_ "SAEDocument" SG_ 2650542334 NumberOfDatabasesAvailable "NMEA2000";
BA_ "SigType" SG_ 2650542334 NumberOfDatabasesAvailable 1;
BA_ "SAEDocument" SG_ 2650542334 nItems "NMEA2000";
BA_ "SigType" SG_ 2650542334 nItems 1;
BA_ "SAEDocument" SG_ 2650542334 StartDatabaseID "NMEA2000";
BA_ "SigType" SG_ 2650542334 StartDatabaseID 1;
BA_ "SAEDocument" SG_ 2314277886 RateOfTurn "NMEA2000";
BA_ "SigType" SG_ 2314277886 RateOfTurn 2;
BA_ "SAEDocument" SG_ 2314277886 SequenceID_ "NMEA2000";
BA_ "SigType" SG_ 2314277886 SequenceID_ 1;
BA_ "SAEDocument" SG_ 2382039038 RadioChannel "NMEA2000";
BA_ "SigType" SG_ 2382039038 RadioChannel 1;
BA_ "SAEDocument" SG_ 2382039038 TxFrequency "NMEA2000";
BA_ "SigType" SG_ 2382039038 TxFrequency 1;
BA_ "SAEDocument" SG_ 2382039038 RxFrequency "NMEA2000";
BA_ "SigType" SG_ 2382039038 RxFrequency 1;
BA_ "SAEDocument" SG_ 2314732542 LongitudeDelta "NMEA2000";
BA_ "SigType" SG_ 2314732542 LongitudeDelta 2;
BA_ "SAEDocument" SG_ 2314732542 LatitudeDelta "NMEA2000";
BA_ "SigType" SG_ 2314732542 LatitudeDelta 2;
BA_ "SAEDocument" SG_ 2314732542 TimeDelta "NMEA2000";
BA_ "SigType" SG_ 2314732542 TimeDelta 1;
BA_ "SAEDocument" SG_ 2314732542 SequenceID_ "NMEA2000";
BA_ "SigType" SG_ 2314732542 SequenceID_ 1;
BA_ "SAEDocument" SG_ 2582648062 ManufacturersModelID "NMEA2000";
BA_ "SigType" SG_ 2582648062 ManufacturersModelID 1;
BA_ "SAEDocument" SG_ 2582648062 NMEAManufacturersProductCode "NMEA2000";
BA_ "SigType" SG_ 2582648062 NMEAManufacturersProductCode 1;
BA_ "SAEDocument" SG_ 2582648062 NMEA2000DatabaseVersion "NMEA2000";
BA_ "SigType" SG_ 2582648062 NMEA2000DatabaseVersion 1;
BA_ "SAEDocument" SG_ 2314732030 Longitude_ "NMEA2000";
BA_ "SigType" SG_ 2314732030 Longitude_ 2;
BA_ "SAEDocument" SG_ 2314732030 Latitude_ "NMEA2000";
BA_ "SigType" SG_ 2314732030 Latitude_ 2;
BA_ "SAEDocument" SG_ 2582576894 VrblNmbrOfFldsFldNmber2Repeated2 "NMEA2000";
BA_ "SigType" SG_ 2582576894 VrblNmbrOfFldsFldNmber2Repeated2 1;
BA_ "SAEDocument" SG_ 2582576894 FirstPGNSupported2 "NMEA2000";
BA_ "SigType" SG_ 2582576894 FirstPGNSupported2 6;
BA_ "SAEDocument" SG_ 2582576894 VrblNmbrOfFldsFldNmber2Repeated "NMEA2000";
BA_ "SigType" SG_ 2582576894 VrblNmbrOfFldsFldNmber2Repeated 1;
BA_ "SAEDocument" SG_ 2582576894 FirstPGNSupported "NMEA2000";
BA_ "SigType" SG_ 2582576894 FirstPGNSupported 6;
BA_ "SAEDocument" SG_ 2582576894 GrpFnctnTrnsmtAndReceivePGNList "NMEA2000";
BA_ "SigType" SG_ 2582576894 GrpFnctnTrnsmtAndReceivePGNList 1;
BA_ "SAEDocument" SG_ 2583234046 RouteName "NMEA2000";
BA_ "SigType" SG_ 2583234046 RouteName 1;
BA_ "SAEDocument" SG_ 2583234046 SpplmntaryRoute_WPDataAvailable "NMEA2000";
BA_ "SigType" SG_ 2583234046 SpplmntaryRoute_WPDataAvailable 4;
BA_ "SAEDocument" SG_ 2583234046 NavigationDirectionInRoute "NMEA2000";
BA_ "SAEDocument" SG_ 2583234046 RouteID "NMEA2000";
BA_ "SigType" SG_ 2583234046 RouteID 1;
BA_ "SAEDocument" SG_ 2583234046 DatabaseID "NMEA2000";
BA_ "SigType" SG_ 2583234046 DatabaseID 1;
BA_ "SAEDocument" SG_ 2583234046 nItems "NMEA2000";
BA_ "SigType" SG_ 2583234046 nItems 1;
BA_ "SAEDocument" SG_ 2583234046 StartRPS "NMEA2000";
BA_ "SigType" SG_ 2583234046 StartRPS 1;
BA_ "SAEDocument" SG_ 2381907198 WaypointClosingVelocity "NMEA2000";
BA_ "SigType" SG_ 2381907198 WaypointClosingVelocity 2;
BA_ "SAEDocument" SG_ 2381907198 DestinationWptLongitude "NMEA2000";
BA_ "SigType" SG_ 2381907198 DestinationWptLongitude 2;
BA_ "SAEDocument" SG_ 2381907198 DestinationWptLatitude "NMEA2000";
BA_ "SigType" SG_ 2381907198 DestinationWptLatitude 2;
BA_ "SAEDocument" SG_ 2381907198 DestinationWaypointNumber "NMEA2000";
BA_ "SigType" SG_ 2381907198 DestinationWaypointNumber 1;
BA_ "SAEDocument" SG_ 2381907198 OriginWaypointNumber "NMEA2000";
BA_ "SigType" SG_ 2381907198 OriginWaypointNumber 1;
BA_ "SAEDocument" SG_ 2381907198 BearingPosToDestinationWaypoint "NMEA2000";
BA_ "SigType" SG_ 2381907198 BearingPosToDestinationWaypoint 1;
BA_ "SAEDocument" SG_ 2381907198 BaringiginToDestinationWaypoint "NMEA2000";
BA_ "SigType" SG_ 2381907198 BaringiginToDestinationWaypoint 1;
BA_ "SAEDocument" SG_ 2381907198 ETADate "NMEA2000";
BA_ "SigType" SG_ 2381907198 ETADate 1;
BA_ "SAEDocument" SG_ 2381907198 ETATime "NMEA2000";
BA_ "SigType" SG_ 2381907198 ETATime 1;
BA_ "SAEDocument" SG_ 2381907198 CalculationType "NMEA2000";
BA_ "SigType" SG_ 2381907198 CalculationType 4;
BA_ "SAEDocument" SG_ 2381907198 ArrivalCircleEntered "NMEA2000";
BA_ "SigType" SG_ 2381907198 ArrivalCircleEntered 4;
BA_ "SAEDocument" SG_ 2381907198 PerpendicularCrossed "NMEA2000";
BA_ "SigType" SG_ 2381907198 PerpendicularCrossed 4;
BA_ "SAEDocument" SG_ 2381907198 Course_BearingRef "NMEA2000";
BA_ "SigType" SG_ 2381907198 Course_BearingRef 4;
BA_ "SAEDocument" SG_ 2381907198 DistanceToDestinationWaypoint "NMEA2000";
BA_ "SigType" SG_ 2381907198 DistanceToDestinationWaypoint 1;
BA_ "SAEDocument" SG_ 2381907198 SID "NMEA2000";
BA_ "SigType" SG_ 2381907198 SID 1;
BA_ "SAEDocument" SG_ 2381184766 NumberOfRqedCmdedParameters "NMEA2000";
BA_ "SigType" SG_ 2381184766 NumberOfRqedCmdedParameters 1;
BA_ "SAEDocument" SG_ 2381184766 VrblNmbrOfFldsFldNmber6Repeated3 "NMEA2000";
BA_ "SAEDocument" SG_ 2381184766 FirstParameterErrorCode "NMEA2000";
BA_ "SAEDocument" SG_ 2381184766 TransInterval_PriorityErrorCode "NMEA2000";
BA_ "SAEDocument" SG_ 2381184766 RqedCmdedPGNBeingAcknowledged "NMEA2000";
BA_ "SigType" SG_ 2381184766 RqedCmdedPGNBeingAcknowledged 6;
BA_ "SAEDocument" SG_ 2381184766 PGNErrorCode "NMEA2000";
BA_ "SAEDocument" SG_ 2381184766 VrblNmbrOfFldsFldNmber6Repeated2 "NMEA2000";
BA_ "SigType" SG_ 2381184766 VrblNmbrOfFldsFldNmber6Repeated2 1;
BA_ "SAEDocument" SG_ 2381184766 FeldNumberOfFirstCmdedParameter "NMEA2000";
BA_ "SigType" SG_ 2381184766 FeldNumberOfFirstCmdedParameter 1;
BA_ "SAEDocument" SG_ 2381184766 NmbrOfPrsOfCmddPrmetersToFollow "NMEA2000";
BA_ "SigType" SG_ 2381184766 NmbrOfPrsOfCmddPrmetersToFollow 1;
BA_ "SAEDocument" SG_ 2381184766 PrioritySetting "NMEA2000";
BA_ "SAEDocument" SG_ 2381184766 CmdedPGN "NMEA2000";
BA_ "SigType" SG_ 2381184766 CmdedPGN 6;
BA_ "SAEDocument" SG_ 2381184766 VrblNmbrOfFldsFldNmber6Repeated "NMEA2000";
BA_ "SigType" SG_ 2381184766 VrblNmbrOfFldsFldNmber6Repeated 1;
BA_ "SAEDocument" SG_ 2381184766 FieldNumberOfFirstRqedParameter "NMEA2000";
BA_ "SigType" SG_ 2381184766 FieldNumberOfFirstRqedParameter 1;
BA_ "SAEDocument" SG_ 2381184766 NmbrOfPrsOfRqParametersToFollow "NMEA2000";
BA_ "SigType" SG_ 2381184766 NmbrOfPrsOfRqParametersToFollow 1;
BA_ "SAEDocument" SG_ 2381184766 TransIntervalOffset "NMEA2000";
BA_ "SigType" SG_ 2381184766 TransIntervalOffset 1;
BA_ "SAEDocument" SG_ 2381184766 TransInterval "NMEA2000";
BA_ "SigType" SG_ 2381184766 TransInterval 1;
BA_ "SAEDocument" SG_ 2381184766 RqedPGN "NMEA2000";
BA_ "SigType" SG_ 2381184766 RqedPGN 6;
BA_ "SAEDocument" SG_ 2381184766 GroupFunctionRq_Cmd_Acknowledge "NMEA2000";
BA_ "SigType" SG_ 2381184766 GroupFunctionRq_Cmd_Acknowledge 1;
BA_ "SAEDocument" SG_ 2583500030 StationIDString "NMEA2000";
BA_ "SigType" SG_ 2583500030 StationIDString 1;
BA_ "SAEDocument" SG_ 2583500030 WaterTemp "NMEA2000";
BA_ "SigType" SG_ 2583500030 WaterTemp 1;
BA_ "SAEDocument" SG_ 2583500030 AirTemp "NMEA2000";
BA_ "SigType" SG_ 2583500030 AirTemp 1;
BA_ "SAEDocument" SG_ 2583500030 PressTendencyRate "NMEA2000";
BA_ "SigType" SG_ 2583500030 PressTendencyRate 2;
BA_ "SAEDocument" SG_ 2583500030 AtmosphericPress "NMEA2000";
BA_ "SigType" SG_ 2583500030 AtmosphericPress 1;
BA_ "SAEDocument" SG_ 2583500030 DominateWavePeriod "NMEA2000";
BA_ "SigType" SG_ 2583500030 DominateWavePeriod 1;
BA_ "SAEDocument" SG_ 2583500030 WaveHeight "NMEA2000";
BA_ "SigType" SG_ 2583500030 WaveHeight 1;
BA_ "SAEDocument" SG_ 2583500030 WindGusts "NMEA2000";
BA_ "SigType" SG_ 2583500030 WindGusts 1;
BA_ "SAEDocument" SG_ 2583500030 WindReference "NMEA2000";
BA_ "SAEDocument" SG_ 2583500030 WindDirection "NMEA2000";
BA_ "SigType" SG_ 2583500030 WindDirection 1;
BA_ "DDI" SG_ 2583500030 WindDirection 208;
BA_ "SAEDocument" SG_ 2583500030 WindSpeed "NMEA2000";
BA_ "SigType" SG_ 2583500030 WindSpeed 1;
BA_ "DDI" SG_ 2583500030 WindSpeed 207;
BA_ "SAEDocument" SG_ 2583500030 StationLocationLongitude "NMEA2000";
BA_ "SigType" SG_ 2583500030 StationLocationLongitude 2;
BA_ "SAEDocument" SG_ 2583500030 StationLocationLatitude "NMEA2000";
BA_ "SigType" SG_ 2583500030 StationLocationLatitude 2;
BA_ "SAEDocument" SG_ 2583500030 MeasurementTime "NMEA2000";
BA_ "SigType" SG_ 2583500030 MeasurementTime 1;
BA_ "SAEDocument" SG_ 2583500030 MeasurementDate "NMEA2000";
BA_ "SigType" SG_ 2583500030 MeasurementDate 1;
BA_ "SAEDocument" SG_ 2583500030 Mode "NMEA2000";
BA_ "SAEDocument" SG_ 2583499774 StationIDString "NMEA2000";
BA_ "SigType" SG_ 2583499774 StationIDString 1;
BA_ "SAEDocument" SG_ 2583499774 AirTemp "NMEA2000";
BA_ "SigType" SG_ 2583499774 AirTemp 1;
BA_ "SAEDocument" SG_ 2583499774 AtmosphericPress "NMEA2000";
BA_ "SigType" SG_ 2583499774 AtmosphericPress 1;
BA_ "SAEDocument" SG_ 2583499774 WindGusts "NMEA2000";
BA_ "SigType" SG_ 2583499774 WindGusts 1;
BA_ "SAEDocument" SG_ 2583499774 WindReference "NMEA2000";
BA_ "SAEDocument" SG_ 2583499774 WindDirection "NMEA2000";
BA_ "SigType" SG_ 2583499774 WindDirection 1;
BA_ "DDI" SG_ 2583499774 WindDirection 208;
BA_ "SAEDocument" SG_ 2583499774 WindSpeed "NMEA2000";
BA_ "SigType" SG_ 2583499774 WindSpeed 1;
BA_ "DDI" SG_ 2583499774 WindSpeed 207;
BA_ "SAEDocument" SG_ 2583499774 StationLocationLongitude "NMEA2000";
BA_ "SigType" SG_ 2583499774 StationLocationLongitude 2;
BA_ "SAEDocument" SG_ 2583499774 StationLocationLatitude "NMEA2000";
BA_ "SigType" SG_ 2583499774 StationLocationLatitude 2;
BA_ "SAEDocument" SG_ 2583499774 MeasurementTime "NMEA2000";
BA_ "SigType" SG_ 2583499774 MeasurementTime 1;
BA_ "SAEDocument" SG_ 2583499774 MeasurementDate "NMEA2000";
BA_ "SigType" SG_ 2583499774 MeasurementDate 1;
BA_ "SAEDocument" SG_ 2583499774 Mode "NMEA2000";
BA_ "SAEDocument" SG_ 2649823998 Variation "NMEA2000";
BA_ "SigType" SG_ 2649823998 Variation 2;
BA_ "SAEDocument" SG_ 2649823998 AgeOfService "NMEA2000";
BA_ "SigType" SG_ 2649823998 AgeOfService 1;
BA_ "SAEDocument" SG_ 2649823998 VariationSource "NMEA2000";
BA_ "SAEDocument" SG_ 2649823998 SequenceID_ "NMEA2000";
BA_ "SigType" SG_ 2649823998 SequenceID_ 1;
BA_ "SAEDocument" SG_ 2382103806 Mode "NMEA2000";
BA_ "SAEDocument" SG_ 2382103806 StationStatusZ "NMEA2000";
BA_ "SAEDocument" SG_ 2382103806 StationStatusY "NMEA2000";
BA_ "SAEDocument" SG_ 2382103806 StationStatusX "NMEA2000";
BA_ "SAEDocument" SG_ 2382103806 StationStatusW "NMEA2000";
BA_ "SAEDocument" SG_ 2382103806 StationStatusV "NMEA2000";
BA_ "SAEDocument" SG_ 2382103806 StationStatusMaster "NMEA2000";
BA_ "SAEDocument" SG_ 2382103806 ZSecondTD "NMEA2000";
BA_ "SigType" SG_ 2382103806 ZSecondTD 2;
BA_ "SAEDocument" SG_ 2382103806 YSecondTD "NMEA2000";
BA_ "SigType" SG_ 2382103806 YSecondTD 2;
BA_ "SAEDocument" SG_ 2382103806 XSecondTD "NMEA2000";
BA_ "SigType" SG_ 2382103806 XSecondTD 2;
BA_ "SAEDocument" SG_ 2382103806 WSecondTD "NMEA2000";
BA_ "SigType" SG_ 2382103806 WSecondTD 2;
BA_ "SAEDocument" SG_ 2382103806 VSecondTD "NMEA2000";
BA_ "SigType" SG_ 2382103806 VSecondTD 2;
BA_ "SAEDocument" SG_ 2382103806 MasterRange "NMEA2000";
BA_ "SigType" SG_ 2382103806 MasterRange 2;
BA_ "SAEDocument" SG_ 2382103806 GroupRepetitionInterval "NMEA2000";
BA_ "SigType" SG_ 2382103806 GroupRepetitionInterval 2;
BA_ "SAEDocument" SG_ 2382104318 StationIdentifier "NMEA2000";
BA_ "SigType" SG_ 2382104318 StationIdentifier 1;
BA_ "SAEDocument" SG_ 2382104318 GroupRepetitionInterval "NMEA2000";
BA_ "SigType" SG_ 2382104318 GroupRepetitionInterval 2;
BA_ "SAEDocument" SG_ 2382104062 Mode "NMEA2000";
BA_ "SAEDocument" SG_ 2382104062 StationStatusZ "NMEA2000";
BA_ "SAEDocument" SG_ 2382104062 StationStatusY "NMEA2000";
BA_ "SAEDocument" SG_ 2382104062 StationStatusX "NMEA2000";
BA_ "SAEDocument" SG_ 2382104062 StationStatusW "NMEA2000";
BA_ "SAEDocument" SG_ 2382104062 StationStatusV "NMEA2000";
BA_ "SAEDocument" SG_ 2382104062 StationStatusMaster "NMEA2000";
BA_ "SAEDocument" SG_ 2382104062 ZSecondRange "NMEA2000";
BA_ "SigType" SG_ 2382104062 ZSecondRange 2;
BA_ "SAEDocument" SG_ 2382104062 YSecondRange "NMEA2000";
BA_ "SigType" SG_ 2382104062 YSecondRange 2;
BA_ "SAEDocument" SG_ 2382104062 XSecondRange "NMEA2000";
BA_ "SigType" SG_ 2382104062 XSecondRange 2;
BA_ "SAEDocument" SG_ 2382104062 WSecondRange "NMEA2000";
BA_ "SigType" SG_ 2382104062 WSecondRange 2;
BA_ "SAEDocument" SG_ 2382104062 VSecondRange "NMEA2000";
BA_ "SigType" SG_ 2382104062 VSecondRange 2;
BA_ "SAEDocument" SG_ 2382104062 MasterRange "NMEA2000";
BA_ "SigType" SG_ 2382104062 MasterRange 2;
BA_ "SAEDocument" SG_ 2382104062 GroupRepetitionInterval "NMEA2000";
BA_ "SigType" SG_ 2382104062 GroupRepetitionInterval 2;
BA_ "SAEDocument" SG_ 2314274302 VesselHeading "NMEA2000";
BA_ "SigType" SG_ 2314274302 VesselHeading 1;
BA_ "SAEDocument" SG_ 2314274302 OffTrackLimit "NMEA2000";
BA_ "SigType" SG_ 2314274302 OffTrackLimit 2;
BA_ "SAEDocument" SG_ 2314274302 RateOfTurnder "NMEA2000";
BA_ "SigType" SG_ 2314274302 RateOfTurnder 2;
BA_ "SAEDocument" SG_ 2314274302 RadiusOfTurnder "NMEA2000";
BA_ "SigType" SG_ 2314274302 RadiusOfTurnder 2;
BA_ "SAEDocument" SG_ 2314274302 OffHeadingLimit "NMEA2000";
BA_ "SigType" SG_ 2314274302 OffHeadingLimit 1;
BA_ "SAEDocument" SG_ 2314274302 RudderLimit "NMEA2000";
BA_ "SigType" SG_ 2314274302 RudderLimit 1;
BA_ "SAEDocument" SG_ 2314274302 Track "NMEA2000";
BA_ "SigType" SG_ 2314274302 Track 1;
BA_ "SAEDocument" SG_ 2314274302 HeadingToSteer "NMEA2000";
BA_ "SigType" SG_ 2314274302 HeadingToSteer 1;
BA_ "SAEDocument" SG_ 2314274302 CmdedRudderAngle "NMEA2000";
BA_ "SigType" SG_ 2314274302 CmdedRudderAngle 2;
BA_ "SAEDocument" SG_ 2314274302 CmdedRudderDirection "NMEA2000";
BA_ "SAEDocument" SG_ 2314274302 HeadingReference "NMEA2000";
BA_ "SigType" SG_ 2314274302 HeadingReference 4;
BA_ "SAEDocument" SG_ 2314274302 TurnMode "NMEA2000";
BA_ "SAEDocument" SG_ 2314274302 SteerMode "NMEA2000";
BA_ "SAEDocument" SG_ 2314274302 Override "NMEA2000";
BA_ "SigType" SG_ 2314274302 Override 4;
BA_ "SAEDocument" SG_ 2314274302 OffTrackLimitExceeded "NMEA2000";
BA_ "SigType" SG_ 2314274302 OffTrackLimitExceeded 4;
BA_ "SAEDocument" SG_ 2314274302 OffHeadingLimitExceeded "NMEA2000";
BA_ "SigType" SG_ 2314274302 OffHeadingLimitExceeded 4;
BA_ "SAEDocument" SG_ 2314274302 RudderLimitExceeded "NMEA2000";
BA_ "SigType" SG_ 2314274302 RudderLimitExceeded 4;
BA_ "SAEDocument" SG_ 2583299582 ClockParameter2 "NMEA2000";
BA_ "SigType" SG_ 2583299582 ClockParameter2 1;
BA_ "SAEDocument" SG_ 2583299582 ClockParameter1 "NMEA2000";
BA_ "SigType" SG_ 2583299582 ClockParameter1 1;
BA_ "SAEDocument" SG_ 2583299582 MeanAnomaly "NMEA2000";
BA_ "SigType" SG_ 2583299582 MeanAnomaly 1;
BA_ "SAEDocument" SG_ 2583299582 LongitudeOfAscensionNode "NMEA2000";
BA_ "SigType" SG_ 2583299582 LongitudeOfAscensionNode 1;
BA_ "SAEDocument" SG_ 2583299582 ArgumentOfPerigee "NMEA2000";
BA_ "SigType" SG_ 2583299582 ArgumentOfPerigee 1;
BA_ "SAEDocument" SG_ 2583299582 RootOfSemimajorAxis "NMEA2000";
BA_ "SigType" SG_ 2583299582 RootOfSemimajorAxis 1;
BA_ "SAEDocument" SG_ 2583299582 RateOfRightAscension "NMEA2000";
BA_ "SigType" SG_ 2583299582 RateOfRightAscension 1;
BA_ "SAEDocument" SG_ 2583299582 InclinationAngle "NMEA2000";
BA_ "SigType" SG_ 2583299582 InclinationAngle 1;
BA_ "SAEDocument" SG_ 2583299582 AlmanacReferenceTime "NMEA2000";
BA_ "SigType" SG_ 2583299582 AlmanacReferenceTime 1;
BA_ "SAEDocument" SG_ 2583299582 Eccentricity "NMEA2000";
BA_ "SigType" SG_ 2583299582 Eccentricity 1;
BA_ "SAEDocument" SG_ 2583299582 SVHealthBits "NMEA2000";
BA_ "SigType" SG_ 2583299582 SVHealthBits 1;
BA_ "SAEDocument" SG_ 2583299582 GPSWeekNumber "NMEA2000";
BA_ "SigType" SG_ 2583299582 GPSWeekNumber 1;
BA_ "SAEDocument" SG_ 2583299582 PRN "NMEA2000";
BA_ "SigType" SG_ 2583299582 PRN 1;
BA_ "SAEDocument" SG_ 2583299326 PRNStatusN "NMEA2000";
BA_ "SAEDocument" SG_ 2583299326 RangeResidualsN "NMEA2000";
BA_ "SigType" SG_ 2583299326 RangeResidualsN 2;
BA_ "SAEDocument" SG_ 2583299326 SNRN "NMEA2000";
BA_ "SigType" SG_ 2583299326 SNRN 2;
BA_ "SAEDocument" SG_ 2583299326 AzimuthN "NMEA2000";
BA_ "SigType" SG_ 2583299326 AzimuthN 1;
BA_ "SAEDocument" SG_ 2583299326 ElevationN "NMEA2000";
BA_ "SigType" SG_ 2583299326 ElevationN 2;
BA_ "SAEDocument" SG_ 2583299326 PRNN "NMEA2000";
BA_ "SigType" SG_ 2583299326 PRNN 1;
BA_ "SAEDocument" SG_ 2583299326 PRNStatus1 "NMEA2000";
BA_ "SAEDocument" SG_ 2583299326 RangeResiduals1 "NMEA2000";
BA_ "SigType" SG_ 2583299326 RangeResiduals1 2;
BA_ "SAEDocument" SG_ 2583299326 SNR1 "NMEA2000";
BA_ "SigType" SG_ 2583299326 SNR1 2;
BA_ "SAEDocument" SG_ 2583299326 Azimuth1 "NMEA2000";
BA_ "SigType" SG_ 2583299326 Azimuth1 1;
BA_ "SAEDocument" SG_ 2583299326 Elevation1 "NMEA2000";
BA_ "SigType" SG_ 2583299326 Elevation1 2;
BA_ "SAEDocument" SG_ 2583299326 PRN1 "NMEA2000";
BA_ "SigType" SG_ 2583299326 PRN1 1;
BA_ "SAEDocument" SG_ 2583299326 NumberOfSVs_ "NMEA2000";
BA_ "SigType" SG_ 2583299326 NumberOfSVs_ 1;
BA_ "SAEDocument" SG_ 2583299326 SID "NMEA2000";
BA_ "SigType" SG_ 2583299326 SID 1;
BA_ "SAEDocument" SG_ 2583299326 RangeResidualMode "NMEA2000";
BA_ "SigType" SG_ 2583299326 RangeResidualMode 4;
BA_ "SAEDocument" SG_ 2583300862 PsdrngRsdlFilteringTimeConstant "NMEA2000";
BA_ "SigType" SG_ 2583300862 PsdrngRsdlFilteringTimeConstant 1;
BA_ "SAEDocument" SG_ 2583300862 ProbabilityOfMissedDetection "NMEA2000";
BA_ "SigType" SG_ 2583300862 ProbabilityOfMissedDetection 2;
BA_ "SAEDocument" SG_ 2583300862 ProbabilityOfFalseAlarm "NMEA2000";
BA_ "SigType" SG_ 2583300862 ProbabilityOfFalseAlarm 2;
BA_ "SAEDocument" SG_ 2583300862 RadialPosErrorMaxThreshold "NMEA2000";
BA_ "SigType" SG_ 2583300862 RadialPosErrorMaxThreshold 1;
BA_ "SAEDocument" SG_ 2583300606 StdDeviationOfBias "NMEA2000";
BA_ "SigType" SG_ 2583300606 StdDeviationOfBias 2;
BA_ "SAEDocument" SG_ 2583300606 EstimateOfPseudorangeBias "NMEA2000";
BA_ "SigType" SG_ 2583300606 EstimateOfPseudorangeBias 2;
BA_ "SAEDocument" SG_ 2583300606 ProbabilityOfMissedDetection "NMEA2000";
BA_ "SigType" SG_ 2583300606 ProbabilityOfMissedDetection 2;
BA_ "SAEDocument" SG_ 2583300606 SVIDOfMostLikelyFailedSat "NMEA2000";
BA_ "SigType" SG_ 2583300606 SVIDOfMostLikelyFailedSat 1;
BA_ "SAEDocument" SG_ 2583300606 AltitudeExpectedError "NMEA2000";
BA_ "SigType" SG_ 2583300606 AltitudeExpectedError 2;
BA_ "SAEDocument" SG_ 2583300606 LongitudeExpectedError "NMEA2000";
BA_ "SigType" SG_ 2583300606 LongitudeExpectedError 2;
BA_ "SAEDocument" SG_ 2583300606 LatitudeExpectedError "NMEA2000";
BA_ "SigType" SG_ 2583300606 LatitudeExpectedError 2;
BA_ "SAEDocument" SG_ 2583300606 IntegrityFlag "NMEA2000";
BA_ "SAEDocument" SG_ 2583300606 SequenceID_ "NMEA2000";
BA_ "SigType" SG_ 2583300606 SequenceID_ 1;
BA_ "SAEDocument" SG_ 2583299838 STDOfAltError "NMEA2000";
BA_ "SigType" SG_ 2583299838 STDOfAltError 1;
BA_ "SAEDocument" SG_ 2583299838 STDOfLonError "NMEA2000";
BA_ "SigType" SG_ 2583299838 STDOfLonError 1;
BA_ "SAEDocument" SG_ 2583299838 STDOfLatError "NMEA2000";
BA_ "SigType" SG_ 2583299838 STDOfLatError 1;
BA_ "SAEDocument" SG_ 2583299838 OrientationOfMajorAxis "NMEA2000";
BA_ "SigType" SG_ 2583299838 OrientationOfMajorAxis 1;
BA_ "SAEDocument" SG_ 2583299838 STDOfMinorAxis "NMEA2000";
BA_ "SigType" SG_ 2583299838 STDOfMinorAxis 1;
BA_ "SAEDocument" SG_ 2583299838 STDOfMajorAxis "NMEA2000";
BA_ "SigType" SG_ 2583299838 STDOfMajorAxis 1;
BA_ "SAEDocument" SG_ 2583299838 RMSOfPosUncertainty "NMEA2000";
BA_ "SigType" SG_ 2583299838 RMSOfPosUncertainty 1;
BA_ "SAEDocument" SG_ 2583299838 SID "NMEA2000";
BA_ "SigType" SG_ 2583299838 SID 1;
BA_ "SAEDocument" SG_ 2583301118 StdDevAltitudeError "NMEA2000";
BA_ "SigType" SG_ 2583301118 StdDevAltitudeError 1;
BA_ "SAEDocument" SG_ 2583301118 StdDevLongitudeError "NMEA2000";
BA_ "SigType" SG_ 2583301118 StdDevLongitudeError 1;
BA_ "SAEDocument" SG_ 2583301118 StdDevLatitudeError "NMEA2000";
BA_ "SigType" SG_ 2583301118 StdDevLatitudeError 1;
BA_ "SAEDocument" SG_ 2583301118 OrientationOfErrorEllipse "NMEA2000";
BA_ "SigType" SG_ 2583301118 OrientationOfErrorEllipse 1;
BA_ "SAEDocument" SG_ 2583301118 StdDevMinorErrorEllipse "NMEA2000";
BA_ "SigType" SG_ 2583301118 StdDevMinorErrorEllipse 1;
BA_ "SAEDocument" SG_ 2583301118 StdDevMajorErrorEllipse "NMEA2000";
BA_ "SigType" SG_ 2583301118 StdDevMajorErrorEllipse 1;
BA_ "SAEDocument" SG_ 2583301118 RMSStdDevOfRangeInputs "NMEA2000";
BA_ "SigType" SG_ 2583301118 RMSStdDevOfRangeInputs 1;
BA_ "SAEDocument" SG_ 2583301118 SequenceID_ "NMEA2000";
BA_ "SigType" SG_ 2583301118 SequenceID_ 1;
BA_ "SAEDocument" SG_ 2381841918 AgeOfDGNSSReferenceStationN "NMEA2000";
BA_ "SigType" SG_ 2381841918 AgeOfDGNSSReferenceStationN 1;
BA_ "SAEDocument" SG_ 2381841918 ReferenceStationIDN "NMEA2000";
BA_ "SigType" SG_ 2381841918 ReferenceStationIDN 1;
BA_ "SAEDocument" SG_ 2381841918 ReferenceStationTypeN "NMEA2000";
BA_ "SAEDocument" SG_ 2381841918 AgeOfDGNSSCorrections1_ "NMEA2000";
BA_ "SigType" SG_ 2381841918 AgeOfDGNSSCorrections1_ 1;
BA_ "SAEDocument" SG_ 2381841918 ReferenceStationID1_ "NMEA2000";
BA_ "SigType" SG_ 2381841918 ReferenceStationID1_ 1;
BA_ "SAEDocument" SG_ 2381841918 ReferenceStationType1 "NMEA2000";
BA_ "SAEDocument" SG_ 2381841918 NumberOfReferenceStations_ "NMEA2000";
BA_ "SigType" SG_ 2381841918 NumberOfReferenceStations_ 1;
BA_ "SAEDocument" SG_ 2381841918 GeoidalSeparation_ "NMEA2000";
BA_ "SigType" SG_ 2381841918 GeoidalSeparation_ 2;
BA_ "SAEDocument" SG_ 2381841918 PDOP_ "NMEA2000";
BA_ "SigType" SG_ 2381841918 PDOP_ 2;
BA_ "SAEDocument" SG_ 2381841918 HDOP_ "NMEA2000";
BA_ "SigType" SG_ 2381841918 HDOP_ 2;
BA_ "SAEDocument" SG_ 2381841918 NumberOfSVs_ "NMEA2000";
BA_ "SigType" SG_ 2381841918 NumberOfSVs_ 1;
BA_ "SAEDocument" SG_ 2381841918 Integrity "NMEA2000";
BA_ "SAEDocument" SG_ 2381841918 MethodGNSS "NMEA2000";
BA_ "SAEDocument" SG_ 2381841918 TypeOfSystem_ "NMEA2000";
BA_ "SAEDocument" SG_ 2381841918 Altitude_high "NMEA2000";
BA_ "SigType" SG_ 2381841918 Altitude_high 2;
BA_ "SAEDocument" SG_ 2381841918 Altitude_low "NMEA2000";
BA_ "SigType" SG_ 2381841918 Altitude_low 1;
BA_ "SAEDocument" SG_ 2381841918 Longitude_high "NMEA2000";
BA_ "SigType" SG_ 2381841918 Longitude_high 2;
BA_ "SAEDocument" SG_ 2381841918 Longitude_low "NMEA2000";
BA_ "SigType" SG_ 2381841918 Longitude_low 1;
BA_ "SAEDocument" SG_ 2381841918 Latitude_high "NMEA2000";
BA_ "SigType" SG_ 2381841918 Latitude_high 2;
BA_ "SAEDocument" SG_ 2381841918 Latitude_low "NMEA2000";
BA_ "SigType" SG_ 2381841918 Latitude_low 1;
BA_ "SAEDocument" SG_ 2381841918 PosTime "NMEA2000";
BA_ "SigType" SG_ 2381841918 PosTime 1;
BA_ "SAEDocument" SG_ 2381841918 PosDate "NMEA2000";
BA_ "SigType" SG_ 2381841918 PosDate 1;
BA_ "SAEDocument" SG_ 2381841918 SID "NMEA2000";
BA_ "SigType" SG_ 2381841918 SID 1;
BA_ "SAEDocument" SG_ 2583301886 DiffOperationMode "NMEA2000";
BA_ "SAEDocument" SG_ 2583301886 DiffSource "NMEA2000";
BA_ "SAEDocument" SG_ 2583301886 SerialInterfaceDetectionMode "NMEA2000";
BA_ "SAEDocument" SG_ 2583301886 SerialInterfaceBitRate "NMEA2000";
BA_ "SAEDocument" SG_ 2583301886 Frequency "NMEA2000";
BA_ "SigType" SG_ 2583301886 Frequency 1;
BA_ "SAEDocument" SG_ 2583301886 Channel "NMEA2000";
BA_ "SigType" SG_ 2583301886 Channel 1;
BA_ "SAEDocument" SG_ 2583302142 SatelliteServiceIDNo "NMEA2000";
BA_ "SigType" SG_ 2583302142 SatelliteServiceIDNo 1;
BA_ "SAEDocument" SG_ 2583302142 TimeSinceLastSatDiffSync "NMEA2000";
BA_ "SigType" SG_ 2583302142 TimeSinceLastSatDiffSync 1;
BA_ "SAEDocument" SG_ 2583302142 DiffSource "NMEA2000";
BA_ "SAEDocument" SG_ 2583302142 UsedAsCorrectionSource "NMEA2000";
BA_ "SigType" SG_ 2583302142 UsedAsCorrectionSource 4;
BA_ "SAEDocument" SG_ 2583302142 DiffSignalDetectionMode "NMEA2000";
BA_ "SAEDocument" SG_ 2583302142 DiffSignalBitRate "NMEA2000";
BA_ "SAEDocument" SG_ 2583302142 StationID "NMEA2000";
BA_ "SigType" SG_ 2583302142 StationID 1;
BA_ "SAEDocument" SG_ 2583302142 StationType "NMEA2000";
BA_ "SAEDocument" SG_ 2583302142 Frequency "NMEA2000";
BA_ "SigType" SG_ 2583302142 Frequency 1;
BA_ "SAEDocument" SG_ 2583302142 SignalSNR "NMEA2000";
BA_ "SigType" SG_ 2583302142 SignalSNR 2;
BA_ "SAEDocument" SG_ 2583302142 SignalStrength "NMEA2000";
BA_ "SigType" SG_ 2583302142 SignalStrength 2;
BA_ "SAEDocument" SG_ 2583302142 Channel "NMEA2000";
BA_ "SigType" SG_ 2583302142 Channel 1;
BA_ "SAEDocument" SG_ 2583302142 SID "NMEA2000";
BA_ "SigType" SG_ 2583302142 SID 1;
VAL_ 3221225472 TirePressThresholdDetection 7 "Not available" 6 "Error indicator" 5 "Not defined" 4 "Extreme under pressure  The tire pressure is at a level where the safety of the vehicle may be jeopardised" 3 "Under pressure  The tire pressure is lower than the pressure defined by the vehicle or tire manufacturer" 2 "No warning pressure  The tire pressure is within the thresholds defined by the vehicle or tire manufacturer" 1 "Over pressure  The tire pressure is higher than the pressure defined by the vehicle or tire manufacturer" 0 "Extreme over pressure  The tire pressure is at a level where the safety of the vehicle may be jeopardised" ;
VAL_ 3221225472 CTIWheelEndElectricalFault 3 "Not Supported" 2 "Error" 1 "Not Defined" 0 "Ok  No Fault" ;
VAL_ 3221225472 CTITireStatus 3 "Not Supported" 2 "Error" 1 "Tire leak detected" 0 "Ok no fault" ;
VAL_ 3221225472 CTIWheelSensorStatus 3 "Not Supported" 2 "Not Defined" 1 "On tire is polled" 0 "Off / isolated from CTI Pressure Controller" ;
VAL_ 3221225472 EngTurningGearEngaged 1 "Engaged" 0 "Not engaged" 3 "Not available" 2 "Error" ;
VAL_ 3221225472 MalfunctionIndicatorLampStatus 3 "Not available" 2 "Reserved" 1 "Lamp on" 0 "Lamp off" ;
VAL_ 3221225472 RedStopLampState 3 "Not available" 2 "Reserved" 1 "Lamp on" 0 "Lamp off" ;
VAL_ 3221225472 AmberWarningLampStatus 3 "Not available" 2 "Reserved" 1 "Lamp on" 0 "Lamp off" ;
VAL_ 3221225472 ProtectLampStatus 3 "Not available" 2 "Reserved" 1 "Lamp on" 0 "Lamp off" ;
VAL_ 3221225472 FlashRedStopLamp 3 "Unavailable / Do Not Flash" 2 "Reserved" 1 "Fast Flash" 0 "Slow Flash" ;
VAL_ 3221225472 FlashProtectLamp 3 "Unavailable / Do Not Flash" 2 "Reserved" 1 "Fast Flash" 0 "Slow Flash" ;
VAL_ 3221225472 FlashMalfuncIndicatorLamp 3 "Unavailable / Do Not Flash" 2 "Reserved" 1 "Fast Flash" 0 "Slow Flash" ;
VAL_ 3221225472 FlashAmberWarningLamp 3 "Unavailable / Do Not Flash" 2 "Reserved" 1 "Fast Flash" 0 "Slow Flash" ;
VAL_ 2566835198 Failure_Mode_Indentifier5 31 "Not available" 19 "Received network data in error" 18 "Below normal (moderately severe)" 17 "Below normal (least severe)" 16 "Above normal (moderately severe)" 15 "Above normal (least severe)" 14 "Special intstructions" 13 "Out of calibration" 12 "Bad intelligent device" 11 "Root cause not known" 10 "Abnormal rate of change" 9 "Abnormal update rate" 8 "Abnormal frequency" 7 "Mechanical system not responding" 6 "Current above normal" 5 "Current below normal" 4 "Voltage below normal" 3 "Voltage above normal" 2 "Data erratic" 1 "Below normal (most severe)" 0 "Above normal (most severe)" ;
VAL_ 2566835198 Failure_Mode_Indentifier4 31 "Not available" 19 "Received network data in error" 18 "Below normal (moderately severe)" 17 "Below normal (least severe)" 16 "Above normal (moderately severe)" 15 "Above normal (least severe)" 14 "Special intstructions" 13 "Out of calibration" 12 "Bad intelligent device" 11 "Root cause not known" 10 "Abnormal rate of change" 9 "Abnormal update rate" 8 "Abnormal frequency" 7 "Mechanical system not responding" 6 "Current above normal" 5 "Current below normal" 4 "Voltage below normal" 3 "Voltage above normal" 2 "Data erratic" 1 "Below normal (most severe)" 0 "Above normal (most severe)" ;
VAL_ 2566835198 Failure_Mode_Indentifier3 31 "Not available" 19 "Received network data in error" 18 "Below normal (moderately severe)" 17 "Below normal (least severe)" 16 "Above normal (moderately severe)" 15 "Above normal (least severe)" 14 "Special intstructions" 13 "Out of calibration" 12 "Bad intelligent device" 11 "Root cause not known" 10 "Abnormal rate of change" 9 "Abnormal update rate" 8 "Abnormal frequency" 7 "Mechanical system not responding" 6 "Current above normal" 5 "Current below normal" 4 "Voltage below normal" 3 "Voltage above normal" 2 "Data erratic" 1 "Below normal (most severe)" 0 "Above normal (most severe)" ;
VAL_ 2566835198 Failure_Mode_Indentifier2 31 "Not available" 19 "Received network data in error" 18 "Below normal (moderately severe)" 17 "Below normal (least severe)" 16 "Above normal (moderately severe)" 15 "Above normal (least severe)" 14 "Special intstructions" 13 "Out of calibration" 12 "Bad intelligent device" 11 "Root cause not known" 10 "Abnormal rate of change" 9 "Abnormal update rate" 8 "Abnormal frequency" 7 "Mechanical system not responding" 6 "Current above normal" 5 "Current below normal" 4 "Voltage below normal" 3 "Voltage above normal" 2 "Data erratic" 1 "Below normal (most severe)" 0 "Above normal (most severe)" ;
VAL_ 2566835198 Failure_Mode_Indentifier 31 "Not available" 19 "Received network data in error" 18 "Below normal (moderately severe)" 17 "Below normal (least severe)" 16 "Above normal (moderately severe)" 15 "Above normal (least severe)" 14 "Special intstructions" 13 "Out of calibration" 12 "Bad intelligent device" 11 "Root cause not known" 10 "Abnormal rate of change" 9 "Abnormal update rate" 8 "Abnormal frequency" 7 "Mechanical system not responding" 6 "Current above normal" 5 "Current below normal" 4 "Voltage below normal" 3 "Voltage above normal" 2 "Data erratic" 1 "Below normal (most severe)" 0 "Above normal (most severe)" ;
VAL_ 2566835198 FlashRedStopLamp 3 "Unavailable / Do Not Flash" 2 "Reserved" 1 "Fast Flash" 0 "Slow Flash" ;
VAL_ 2566835198 FlashProtectLamp 3 "Unavailable / Do Not Flash" 2 "Reserved" 1 "Fast Flash" 0 "Slow Flash" ;
VAL_ 2566835198 FlashMalfuncIndicatorLamp 3 "Unavailable / Do Not Flash" 2 "Reserved" 1 "Fast Flash" 0 "Slow Flash" ;
VAL_ 2566835198 FlashAmberWarningLamp 3 "Unavailable / Do Not Flash" 2 "Reserved" 1 "Fast Flash" 0 "Slow Flash" ;
VAL_ 2566835198 MalfunctionIndicatorLampStatus 3 "Not available" 2 "Reserved" 1 "Lamp on" 0 "Lamp off" ;
VAL_ 2566835198 AmberWarningLampStatus 3 "Not available" 2 "Reserved" 1 "Lamp on" 0 "Lamp off" ;
VAL_ 2566835198 RedStopLampState 3 "Not available" 2 "Reserved" 1 "Lamp on" 0 "Lamp off" ;
VAL_ 2566835198 ProtectLampStatus 3 "Not available" 2 "Reserved" 1 "Lamp on" 0 "Lamp off" ;
VAL_ 2315059966 WindReference 7 "Null" 6 "Error" 5 "Reserved" 3 "True (boat referenced)" 2 "Apparent" 1 "Magnetic" 0 "True (referenced to North)" ;
VAL_ 2315059966 SequenceID_ 255 "nVldPsFxTTItTRng0T250FrVldPstnFx" ;
VAL_ 2381646846 SID 255 "nVldPsFxTTItTRng0T250FrVldPstnFx" ;
VAL_ 2314277630 HeadingSensorReference 3 "Null" 2 "Error" 1 "Magnetic" 0 "True" ;
VAL_ 2314277630 SID 255 "nVldPsFxTTItTRng0T250FrVldPstnFx" ;
VAL_ 2515667454 EngInstance 255 "Not available" 254 "Error" 253 "Reserve" 1 "DlEngStrBrdTStrnStrbrdNInstncNWh" 0 "SingleEngDualEnginePort" ;
VAL_ 2314339838 TransGear 3 "[Unavailable, Unknown]" 2 "Reverse" 1 "Neutral" 0 "Forward" ;
VAL_ 2314339838 TransInstance 255 "Not available" 254 "Error" 253 "Reserve" 1 "DlEngStrBrdTStrnStrbrdNInstncNWh" 0 "SingleEngDualEnginePort" ;
VAL_ 2314602750 BearingReference 3 "Releative" 2 "Error" 1 "Magnetic" 0 "True" ;
VAL_ 2314602750 SequenceID_ 255 "nVldPsFxTTItTRng0T250FrVldPstnFx" ;
VAL_ 2314602750 UTCOfFix 0 "midnight,  time is in UTC" ;
VAL_ 2381842942 Time 0 "midnight,  time is in UTC" ;
VAL_ 2381911550 MarkType 15 "Null" 14 "Error" 5 "Reserved" 4 "Waypoint" 3 "Wheelover" 2 "Reference (general)" 1 "Turning Point" 0 "Collision" ;
VAL_ 2381911550 SID 255 "nVldPsFxTTItTRng0T250FrVldPstnFx" ;
VAL_ 2583499006 MeasurementTime 0 "midnight,  time is in UTC" ;
VAL_ 2583499006 TideTendency 11 "Unavailable, Unknown" 10 "Error" 1 "Rising" 0 "Falling" ;
VAL_ 2583499006 Mode 15 "Data not available" 14 "Error" 4 "Manual mode" 3 "Simulator mode" 2 "Estimated mode" 1 "Differential, enhanced mode" 0 "Autonomous mode" ;
VAL_ 2381320446 Time 0 "midnight,  time is in UTC" ;
VAL_ 2381320446 Source 15 "Null" 14 "reserved" 5 "Local Crystal clock, 

0x6 -" 4 "Local Rubidium clock" 3 "Local Cesium clock" 2 "WWVEqvalentRadioStationTimeSync" 1 "GLONASS" 0 "GPS" ;
VAL_ 2381320446 SID 255 "nVldPsFxTTItTRng0T250FrVldPstnFx" ;
VAL_ 2381451006 Switch28 3 "No action" 2 "Reserved" 1 "TurnOnEnableSetMake1" 0 "TurnOffDisableResetMake0" ;
VAL_ 2381451006 Switch27 3 "No action" 2 "Reserved" 1 "TurnOnEnableSetMake1" 0 "TurnOffDisableResetMake0" ;
VAL_ 2381451006 Switch26 3 "No action" 2 "Reserved" 1 "TurnOnEnableSetMake1" 0 "TurnOffDisableResetMake0" ;
VAL_ 2381451006 Switch25 3 "No action" 2 "Reserved" 1 "TurnOnEnableSetMake1" 0 "TurnOffDisableResetMake0" ;
VAL_ 2381451006 Switch24 3 "No action" 2 "Reserved" 1 "TurnOnEnableSetMake1" 0 "TurnOffDisableResetMake0" ;
VAL_ 2381451006 Switch23 3 "No action" 2 "Reserved" 1 "TurnOnEnableSetMake1" 0 "TurnOffDisableResetMake0" ;
VAL_ 2381451006 Switch22 3 "No action" 2 "Reserved" 1 "TurnOnEnableSetMake1" 0 "TurnOffDisableResetMake0" ;
VAL_ 2381451006 Switch21 3 "No action" 2 "Reserved" 1 "TurnOnEnableSetMake1" 0 "TurnOffDisableResetMake0" ;
VAL_ 2381451006 Switch20 3 "No action" 2 "Reserved" 1 "TurnOnEnableSetMake1" 0 "TurnOffDisableResetMake0" ;
VAL_ 2381451006 Switch19 3 "No action" 2 "Reserved" 1 "TurnOnEnableSetMake1" 0 "TurnOffDisableResetMake0" ;
VAL_ 2381451006 Switch18 3 "No action" 2 "Reserved" 1 "TurnOnEnableSetMake1" 0 "TurnOffDisableResetMake0" ;
VAL_ 2381451006 Switch17 3 "No action" 2 "Reserved" 1 "TurnOnEnableSetMake1" 0 "TurnOffDisableResetMake0" ;
VAL_ 2381451006 Switch16 3 "No action" 2 "Reserved" 1 "TurnOnEnableSetMake1" 0 "TurnOffDisableResetMake0" ;
VAL_ 2381451006 Switch15 3 "No action" 2 "Reserved" 1 "TurnOnEnableSetMake1" 0 "TurnOffDisableResetMake0" ;
VAL_ 2381451006 Switch14 3 "No action" 2 "Reserved" 1 "TurnOnEnableSetMake1" 0 "TurnOffDisableResetMake0" ;
VAL_ 2381451006 Switch13 3 "No action" 2 "Reserved" 1 "TurnOnEnableSetMake1" 0 "TurnOffDisableResetMake0" ;
VAL_ 2381451006 Switch12 3 "No action" 2 "Reserved" 1 "TurnOnEnableSetMake1" 0 "TurnOffDisableResetMake0" ;
VAL_ 2381451006 Switch11 3 "No action" 2 "Reserved" 1 "TurnOnEnableSetMake1" 0 "TurnOffDisableResetMake0" ;
VAL_ 2381451006 Switch10 3 "No action" 2 "Reserved" 1 "TurnOnEnableSetMake1" 0 "TurnOffDisableResetMake0" ;
VAL_ 2381451006 Switch9 3 "No action" 2 "Reserved" 1 "TurnOnEnableSetMake1" 0 "TurnOffDisableResetMake0" ;
VAL_ 2381451006 Switch8 3 "No action" 2 "Reserved" 1 "TurnOnEnableSetMake1" 0 "TurnOffDisableResetMake0" ;
VAL_ 2381451006 Switch7 3 "No action" 2 "Reserved" 1 "TurnOnEnableSetMake1" 0 "TurnOffDisableResetMake0" ;
VAL_ 2381451006 Switch6 3 "No action" 2 "Reserved" 1 "TurnOnEnableSetMake1" 0 "TurnOffDisableResetMake0" ;
VAL_ 2381451006 Switch5 3 "No action" 2 "Reserved" 1 "TurnOnEnableSetMake1" 0 "TurnOffDisableResetMake0" ;
VAL_ 2381451006 Switch4 3 "No action" 2 "Reserved" 1 "TurnOnEnableSetMake1" 0 "TurnOffDisableResetMake0" ;
VAL_ 2381451006 Switch3 3 "No action" 2 "Reserved" 1 "TurnOnEnableSetMake1" 0 "TurnOffDisableResetMake0" ;
VAL_ 2381451006 Switch2 3 "No action" 2 "Reserved" 1 "TurnOnEnableSetMake1" 0 "TurnOffDisableResetMake0" ;
VAL_ 2381451006 Switch1 3 "No action" 2 "Reserved" 1 "TurnOnEnableSetMake1" 0 "TurnOffDisableResetMake0" ;
VAL_ 2314535934 SequenceID_ 255 "nVldPsFxTTItTRng0T250FrVldPstnFx" ;
VAL_ 2381908990 SetReference 3 "Null" 2 "Error" 1 "Magnetic" 0 "True" ;
VAL_ 2381908990 SID 255 "nVldPsFxTTItTRng0T250FrVldPstnFx" ;
VAL_ 2583499262 MeasurementTime 0 "midnight,  time is in UTC" ;
VAL_ 2583499262 Mode 15 "Data not available" 14 "Error" 4 "Manual mode" 3 "Simulator mode" 2 "Estimated mode" 1 "Differential, enhanced mode" 0 "Autonomous mode" ;
VAL_ 2314276350 Directionder 2 "Move to port" 1 "Move to starboard" 0 "No Order" ;
VAL_ 2314276350 RudderInstance 255 "Not available" 254 "Error" 253 "Reserve" 1 "DlEngStrBrdTStrnStrbrdNInstncNWh" 0 "SingleEngDualEnginePort" ;
VAL_ 2650543614 NavMethodInLegAfterWP 3 "Null" 2 "Error" 1 "Rhumb Line calculations" 0 "Great Circle calculations" ;
VAL_ 2314277886 SequenceID_ 255 "nVldPsFxTTItTRng0T250FrVldPstnFx" ;
VAL_ 2314732542 SequenceID_ 255 "nVldPsFxTTItTRng0T250FrVldPstnFx" ;
VAL_ 2582576894 GrpFnctnTrnsmtAndReceivePGNList 1 "Receive PGN List Message" 0 "Transmit PGN List Message" ;
VAL_ 2583234046 SpplmntaryRoute_WPDataAvailable 3 "[Unavailable, Unknown]" 2 "Error" 1 "[Yes, On, Enabled, Set, '1']" 0 "[No, Off, Disabled, Reset, '0']" ;
VAL_ 2381907198 ETATime 0 "midnight,  time is in UTC" ;
VAL_ 2381907198 CalculationType 3 "Null" 2 "Error" 1 "Rhumb Line calculations" 0 "Great Circle calculations" ;
VAL_ 2381907198 ArrivalCircleEntered 3 "[Unavailable, Unknown]" 2 "Error" 1 "[Yes, On, Enabled, Set, '1']" 0 "[No, Off, Disabled, Reset, '0']" ;
VAL_ 2381907198 PerpendicularCrossed 3 "[Unavailable, Unknown]" 2 "Error" 1 "[Yes, On, Enabled, Set, '1']" 0 "[No, Off, Disabled, Reset, '0']" ;
VAL_ 2381907198 Course_BearingRef 3 "Null" 2 "Error" 1 "Magnetic" 0 "True" ;
VAL_ 2381907198 SID 255 "nVldPsFxTTItTRng0T250FrVldPstnFx" ;
VAL_ 2381184766 VrblNmbrOfFldsFldNmber6Repeated3 5 "RqCmdGroupFunctionNotSupported" 4 "Access denied" 3 "RqCmdParameterOutofrange" 2 "Temporarily unable to comply" 1 "InvalidRqCmdParameterField" 0 "No Error/Acknowledge" ;
VAL_ 2381184766 FirstParameterErrorCode 5 "RqCmdGroupFunctionNotSupported" 4 "Access denied" 3 "RqCmdParameterOutofrange" 2 "Temporarily unable to comply" 1 "InvalidRqCmdParameterField" 0 "No Error/Acknowledge" ;
VAL_ 2381184766 TransInterval_PriorityErrorCode 4 "Request is not supported" 3 "Access denied" 2 "TrnsmtIntrvlIsLssThnMsrmnt_Clclt" 1 "TrnsmtIntrvl_PrrityNotSupported" 0 "No Error/Acknowledge" ;
VAL_ 2381184766 PGNErrorCode 4 "Request is not supported" 3 "Access denied" 2 "PGN temporarily not available" 1 "PGN not supported" 0 "No Error/Acknowledge" ;
VAL_ 2381184766 PrioritySetting 15 "reserved" 9 "returnPriorityToDefault0xATo" 8 "do not change priority" 7 "commanded priority value" ;
VAL_ 2381184766 TransIntervalOffset 65535 "Do not change offset" 0 "transmit immediately" ;
VAL_ 2381184766 TransInterval 65535 "Do not change interval" 0 "Turn-off transmission" ;
VAL_ 2381184766 GroupFunctionRq_Cmd_Acknowledge 2 "Acknowledge Message" 1 "Command Message" 0 "Request Message" ;
VAL_ 2583500030 WindReference 7 "Null" 6 "Error" 5 "Reserved" 3 "True (boat referenced)" 2 "Apparent" 1 "Magnetic" 0 "True (referenced to North)" ;
VAL_ 2583500030 MeasurementTime 0 "midnight,  time is in UTC" ;
VAL_ 2583500030 Mode 15 "Data not available" 14 "Error" 4 "Manual mode" 3 "Simulator mode" 2 "Estimated mode" 1 "Differential, enhanced mode" 0 "Autonomous mode" ;
VAL_ 2583499774 WindReference 7 "Null" 6 "Error" 5 "Reserved" 3 "True (boat referenced)" 2 "Apparent" 1 "Magnetic" 0 "True (referenced to North)" ;
VAL_ 2583499774 MeasurementTime 0 "midnight,  time is in UTC" ;
VAL_ 2583499774 Mode 15 "Data not available" 14 "Error" 4 "Manual mode" 3 "Simulator mode" 2 "Estimated mode" 1 "Differential, enhanced mode" 0 "Autonomous mode" ;
VAL_ 2649823998 VariationSource 63 "Data Not Available" 62 "Reserve" 9 "Reserve,

 thru" 8 "WMM 2020" 7 "WMM 2015" 6 "WMM 2010" 5 "WMM 2005" 4 "WMM 2000" 3 "Automatic Calculation" 2 "Automatic Table" 1 "Automatic - Chart" 0 "Manual Entry" ;
VAL_ 2649823998 SequenceID_ 255 "nVldPsFxTTItTRng0T250FrVldPstnFx" ;
VAL_ 2382103806 Mode 15 "Data not available" 14 "Error" 4 "Manual mode" 3 "Simulator mode" 2 "Estimated mode" 1 "Differential, enhanced mode" 0 "Autonomous mode" ;
VAL_ 2382103806 GroupRepetitionInterval 9960 "99,600,000 ns)" ;
VAL_ 2382104318 GroupRepetitionInterval 9960 "99,600,000 ns)" ;
VAL_ 2382104062 Mode 15 "Data not available" 14 "Error" 4 "Manual mode" 3 "Simulator mode" 2 "Estimated mode" 1 "Differential, enhanced mode" 0 "Autonomous mode" ;
VAL_ 2382104062 GroupRepetitionInterval 9960 "99,600,000 ns)" ;
VAL_ 2314274302 CmdedRudderDirection 2 "Move to port" 1 "Move to starboard" 0 "No Order" ;
VAL_ 2314274302 HeadingReference 3 "Null" 2 "Error" 1 "Magnetic" 0 "True" ;
VAL_ 2314274302 TurnMode 2 "rdsCtrlldDfntnsRddrAnOprtrStRddr" 1 "turn rate controlled" 0 "Rudder Limit controlled" ;
VAL_ 2314274302 SteerMode 2 "Follow-up Device" 1 "Non-Follow-up Device" 0 "Main Steering" 5 "TrckCtrlDfntnsMnStr_OtsdSystmMnS" 4 "Heading Control" 3 "Heading Control Standalone" ;
VAL_ 2314274302 Override 0 "NYsMnsATmprryIntrrptnOfSlctdStrM" 1 "Yes" ;
VAL_ 2314274302 OffTrackLimitExceeded 3 "[Unavailable, Unknown]" 2 "Error" 1 "[Yes, On, Enabled, Set, '1']" 0 "[No, Off, Disabled, Reset, '0']" ;
VAL_ 2314274302 OffHeadingLimitExceeded 3 "[Unavailable, Unknown]" 2 "Error" 1 "[Yes, On, Enabled, Set, '1']" 0 "[No, Off, Disabled, Reset, '0']" ;
VAL_ 2314274302 RudderLimitExceeded 3 "[Unavailable, Unknown]" 2 "Error" 1 "[Yes, On, Enabled, Set, '1']" 0 "[No, Off, Disabled, Reset, '0']" ;
VAL_ 2583299582 PRN 96 "GLONASSFrGLONASSStlltsArIdntfdBy" 64 "SBASStlltBsdAgmentationSystem65" 1 "GPS, 

33-" 0 "value not used" ;
VAL_ 2583299326 PRNStatusN 6 "Reserved14Error15NoSelection" 5 "usedWithDiffCorrections" 4 "TrackedWithDiffCorrections" 3 "DiffCorrectionsAvailable" 2 "UsdInSltnWithoutDiffCorrections" 1 "TrackedButNotUsedInSolution" 0 "Not Tracked" ;
VAL_ 2583299326 PRNN 96 "GLONASSFrGLONASSStlltsArIdntfdBy" 64 "SBASStlltBsdAgmentationSystem65" 1 "GPS, 

33-" 0 "value not used" ;
VAL_ 2583299326 PRNStatus1 6 "Reserved14Error15NoSelection" 5 "usedWithDiffCorrections" 4 "TrackedWithDiffCorrections" 3 "DiffCorrectionsAvailable" 2 "UsdInSltnWithoutDiffCorrections" 1 "TrackedButNotUsedInSolution" 0 "Not Tracked" ;
VAL_ 2583299326 PRN1 96 "GLONASSFrGLONASSStlltsArIdntfdBy" 64 "SBASStlltBsdAgmentationSystem65" 1 "GPS, 

33-" 0 "value not used" ;
VAL_ 2583299326 SID 255 "nVldPsFxTTItTRng0T250FrVldPstnFx" ;
VAL_ 2583299326 RangeResidualMode 3 "Null" 2 "Error" 1 "RangeResidualCalculateddAfterPos" 0 "RangeResidualWereUsedtoCalcData" ;
VAL_ 2583300606 SVIDOfMostLikelyFailedSat 96 "GLONASSFrGLONASSStlltsArIdntfdBy" 64 "SBASStlltBsdAgmentationSystem65" 1 "GPS, 

33-" 0 "value not used" ;
VAL_ 2583300606 IntegrityFlag 3 "UnsfMnsRcvrDsNtHvThisCapability" 2 "Caution" 1 "Safe" 0 "No Integrity checking,*" ;
VAL_ 2583300606 SequenceID_ 255 "nVldPsFxTTItTRng0T250FrVldPstnFx" ;
VAL_ 2583299838 SID 255 "nVldPsFxTTItTRng0T250FrVldPstnFx" ;
VAL_ 2583301118 SequenceID_ 255 "nVldPsFxTTItTRng0T250FrVldPstnFx" ;
VAL_ 2381841918 ReferenceStationTypeN 15 "Null" 14 "Error" 13 "Reserved" 1 "GLONASS; 

0x3 to" 0 "GPS" ;
VAL_ 2381841918 ReferenceStationType1 15 "Null" 14 "Error" 13 "Reserved" 1 "GLONASS; 

0x3 to" 0 "GPS" ;
VAL_ 2381841918 Integrity 3 "UnsfMnsRcvrDsNtHvThisCapability" 2 "Caution" 1 "Safe" 0 "No Integrity checking,*" ;
VAL_ 2381841918 MethodGNSS 15 "NllPrcsGNSSMnsNDlbrtDgrdtnAndHgh" 14 "Error" 9 "Reserved" 8 "Simulate mode" 7 "Manual Input" 6 "Estimated (DR) mode" 5 "RTK Float" 4 "RTK Fixed Integer" 3 "Precise GNSS*" 2 "DGNSS fix" 1 "GNSS fix" 0 "no GPS" ;
VAL_ 2381841918 TypeOfSystem_ 21 "Reserved for future combinations" 4 "GPS+SBAS+GLONASS

0x05 -" 3 "GPS+SBAS(WAAS)" 2 "GPS+GLONASS" 1 "GLONASS" 0 "GPS" ;
VAL_ 2381841918 PosTime 0 "midnight,  time is in UTC" ;
VAL_ 2381841918 SID 255 "nVldPsFxTTItTRng0T250FrVldPstnFx" ;
VAL_ 2583301886 DiffOperationMode 15 "No Selection" 14 "Error" 3 "Reserved" 2 "Auto Range" 1 "Auto Power" 0 "Manual" ;
VAL_ 2583301886 DiffSource 15 "No Selection" 14 "Error" 8 "Reserved" 7 "Other Satellite" 6 "SBAS" 5 "Other Ground-based Radio" 4 "AIS" 3 "FM Subcarrier" 2 "MSK Beacon" 1 "Loran Communications" 0 "Auto Select" ;
VAL_ 2583301886 SerialInterfaceDetectionMode 7 "Null" 6 "Error" 2 "Reserved" 1 "Manual bit rate set" 0 "Auto bit rate set" ;
VAL_ 2583301886 SerialInterfaceBitRate 31 "Null" 30 "Error" 29 "Reserved" 12 "57600bps,

13-" 11 "38400bps" 10 "19200bps" 9 "9600bps" 8 "4800bps" 7 "2400bps" 6 "1200bps" 5 "500bps" 4 "300bps" 3 "200bps" 2 "100bps" 1 "50bps" 0 "25bps" ;
VAL_ 2583302142 DiffSource 15 "No Selection" 14 "Error" 8 "Reserved" 7 "Other Satellite" 6 "SBAS" 5 "Other Ground-based Radio" 4 "AIS" 3 "FM Subcarrier" 2 "MSK Beacon" 1 "Loran Communications" 0 "Auto Select" ;
VAL_ 2583302142 UsedAsCorrectionSource 3 "[Unavailable, Unknown]" 2 "Error" 1 "[Yes, On, Enabled, Set, '1']" 0 "[No, Off, Disabled, Reset, '0']" ;
VAL_ 2583302142 DiffSignalDetectionMode 7 "Null" 6 "Error" 2 "Reserved" 1 "Manual bit rate set" 0 "Auto bit rate set" ;
VAL_ 2583302142 DiffSignalBitRate 3 "200bps" 2 "100bps" 1 "50bps" 0 "25bps" 31 "Null" 30 "Error" 29 "Reserved" 12 "57600bps,

13-" 11 "38400bps" 10 "19200bps" 9 "9600bps" 8 "4800bps" 7 "2400bps" 6 "1200bps" 5 "500bps" 4 "300bps" ;
VAL_ 2583302142 StationType 15 "Null" 14 "Error" 13 "Reserved" 1 "GLONASS; 

0x3 to" 0 "GPS" ;
VAL_ 2583302142 SID 255 "nVldPsFxTTItTRng0T250FrVldPstnFx" ;
SIG_VALTYPE_ 2583172606 EllipsoidFlatteningInverse : 1;
SIG_VALTYPE_ 2583172606 Scale : 1;
SIG_VALTYPE_ 2583172606 RotationInZ : 1;
SIG_VALTYPE_ 2583172606 RotationInY : 1;
SIG_VALTYPE_ 2583172606 RotationInX : 1;
SIG_VALTYPE_ 2583499262 Salinity : 1;
